VERSION "eCMPilot HS1 database-first 2026-10-28; PSA-RE 67f7581e7622410efdbb29c7eda3b86982b9b450; Apache-2.0"

NS_ :

BS_:

BU_: AAS ABS ARTIV AVAS BCP BSI BSM BVA CAV CMM CSS CVM DAE DMTR ESM E_VCU HCU1 HCU2 LVNSD MCM MDS RBG SBW VCU

BO_ 1012 E_VCU_BattTempSlots: 8 E_VCU
 SG_ RawByte8_Mux7 m7 : 63|8@0+ (1,0) [0|255] "raw"  BSI,MDS
 SG_ BatteryTempSlot49 m6 : 63|8@0+ (1,-40) [-40|215] "degC"  BSI,MDS
 SG_ BatteryTempSlot42 m5 : 63|8@0+ (1,-40) [-40|215] "degC"  BSI,MDS
 SG_ BatteryTempSlot35 m4 : 63|8@0+ (1,-40) [-40|215] "degC"  BSI,MDS
 SG_ BatteryTempSlot28 m3 : 63|8@0+ (1,-40) [-40|215] "degC"  BSI,MDS
 SG_ BatteryTempSlot21 m2 : 63|8@0+ (1,-40) [-40|215] "degC"  BSI,MDS
 SG_ BatteryTempSlot14 m1 : 63|8@0+ (1,-40) [-40|215] "degC"  BSI,MDS
 SG_ BatteryTempSlot07 m0 : 63|8@0+ (1,-40) [-40|215] "degC"  BSI,MDS
 SG_ RawByte7_Mux7 m7 : 55|8@0+ (1,0) [0|255] "raw"  BSI,MDS
 SG_ BatteryTempSlot48 m6 : 55|8@0+ (1,-40) [-40|215] "degC"  BSI,MDS
 SG_ BatteryTempSlot41 m5 : 55|8@0+ (1,-40) [-40|215] "degC"  BSI,MDS
 SG_ BatteryTempSlot34 m4 : 55|8@0+ (1,-40) [-40|215] "degC"  BSI,MDS
 SG_ BatteryTempSlot27 m3 : 55|8@0+ (1,-40) [-40|215] "degC"  BSI,MDS
 SG_ BatteryTempSlot20 m2 : 55|8@0+ (1,-40) [-40|215] "degC"  BSI,MDS
 SG_ BatteryTempSlot13 m1 : 55|8@0+ (1,-40) [-40|215] "degC"  BSI,MDS
 SG_ BatteryTempSlot06 m0 : 55|8@0+ (1,-40) [-40|215] "degC"  BSI,MDS
 SG_ BatteryTempSlot54 m7 : 47|8@0+ (1,-40) [-40|215] "degC"  BSI,MDS
 SG_ BatteryTempSlot47 m6 : 47|8@0+ (1,-40) [-40|215] "degC"  BSI,MDS
 SG_ BatteryTempSlot40 m5 : 47|8@0+ (1,-40) [-40|215] "degC"  BSI,MDS
 SG_ BatteryTempSlot33 m4 : 47|8@0+ (1,-40) [-40|215] "degC"  BSI,MDS
 SG_ BatteryTempSlot26 m3 : 47|8@0+ (1,-40) [-40|215] "degC"  BSI,MDS
 SG_ BatteryTempSlot19 m2 : 47|8@0+ (1,-40) [-40|215] "degC"  BSI,MDS
 SG_ BatteryTempSlot12 m1 : 47|8@0+ (1,-40) [-40|215] "degC"  BSI,MDS
 SG_ BatteryTempSlot05 m0 : 47|8@0+ (1,-40) [-40|215] "degC"  BSI,MDS
 SG_ BatteryTempSlot53 m7 : 39|8@0+ (1,-40) [-40|215] "degC"  BSI,MDS
 SG_ BatteryTempSlot46 m6 : 39|8@0+ (1,-40) [-40|215] "degC"  BSI,MDS
 SG_ BatteryTempSlot39 m5 : 39|8@0+ (1,-40) [-40|215] "degC"  BSI,MDS
 SG_ BatteryTempSlot32 m4 : 39|8@0+ (1,-40) [-40|215] "degC"  BSI,MDS
 SG_ BatteryTempSlot25 m3 : 39|8@0+ (1,-40) [-40|215] "degC"  BSI,MDS
 SG_ BatteryTempSlot18 m2 : 39|8@0+ (1,-40) [-40|215] "degC"  BSI,MDS
 SG_ BatteryTempSlot11 m1 : 39|8@0+ (1,-40) [-40|215] "degC"  BSI,MDS
 SG_ BatteryTempSlot04 m0 : 39|8@0+ (1,-40) [-40|215] "degC"  BSI,MDS
 SG_ BatteryTempSlot52 m7 : 31|8@0+ (1,-40) [-40|215] "degC"  BSI,MDS
 SG_ BatteryTempSlot45 m6 : 31|8@0+ (1,-40) [-40|215] "degC"  BSI,MDS
 SG_ BatteryTempSlot38 m5 : 31|8@0+ (1,-40) [-40|215] "degC"  BSI,MDS
 SG_ BatteryTempSlot31 m4 : 31|8@0+ (1,-40) [-40|215] "degC"  BSI,MDS
 SG_ BatteryTempSlot24 m3 : 31|8@0+ (1,-40) [-40|215] "degC"  BSI,MDS
 SG_ BatteryTempSlot17 m2 : 31|8@0+ (1,-40) [-40|215] "degC"  BSI,MDS
 SG_ BatteryTempSlot10 m1 : 31|8@0+ (1,-40) [-40|215] "degC"  BSI,MDS
 SG_ BatteryTempSlot03 m0 : 31|8@0+ (1,-40) [-40|215] "degC"  BSI,MDS
 SG_ BatteryTempSlot51 m7 : 23|8@0+ (1,-40) [-40|215] "degC"  BSI,MDS
 SG_ BatteryTempSlot44 m6 : 23|8@0+ (1,-40) [-40|215] "degC"  BSI,MDS
 SG_ BatteryTempSlot37 m5 : 23|8@0+ (1,-40) [-40|215] "degC"  BSI,MDS
 SG_ BatteryTempSlot30 m4 : 23|8@0+ (1,-40) [-40|215] "degC"  BSI,MDS
 SG_ BatteryTempSlot23 m3 : 23|8@0+ (1,-40) [-40|215] "degC"  BSI,MDS
 SG_ BatteryTempSlot16 m2 : 23|8@0+ (1,-40) [-40|215] "degC"  BSI,MDS
 SG_ BatteryTempSlot09 m1 : 23|8@0+ (1,-40) [-40|215] "degC"  BSI,MDS
 SG_ BatteryTempSlot02 m0 : 23|8@0+ (1,-40) [-40|215] "degC"  BSI,MDS
 SG_ BatteryTempSlot50 m7 : 15|8@0+ (1,-40) [-40|215] "degC"  BSI,MDS
 SG_ BatteryTempSlot43 m6 : 15|8@0+ (1,-40) [-40|215] "degC"  BSI,MDS
 SG_ BatteryTempSlot36 m5 : 15|8@0+ (1,-40) [-40|215] "degC"  BSI,MDS
 SG_ BatteryTempSlot29 m4 : 15|8@0+ (1,-40) [-40|215] "degC"  BSI,MDS
 SG_ BatteryTempSlot22 m3 : 15|8@0+ (1,-40) [-40|215] "degC"  BSI,MDS
 SG_ BatteryTempSlot15 m2 : 15|8@0+ (1,-40) [-40|215] "degC"  BSI,MDS
 SG_ BatteryTempSlot08 m1 : 15|8@0+ (1,-40) [-40|215] "degC"  BSI,MDS
 SG_ BatteryTempSlot01 m0 : 15|8@0+ (1,-40) [-40|215] "degC"  BSI,MDS
 SG_ RawBits3_7 : 4|5@0+ (1,0) [0|31] "raw"  BSI,MDS
 SG_ TemperatureGroup M : 7|3@0+ (1,0) [0|7] ""  BSI,MDS

BO_ 1018 Unknown_Message03: 2 Vector__XXX
 SG_ RawByte2 : 15|8@0+ (1,0) [0|255] "raw" Vector__XXX
 SG_ RawByte1 : 7|8@0+ (1,0) [0|255] "raw" Vector__XXX

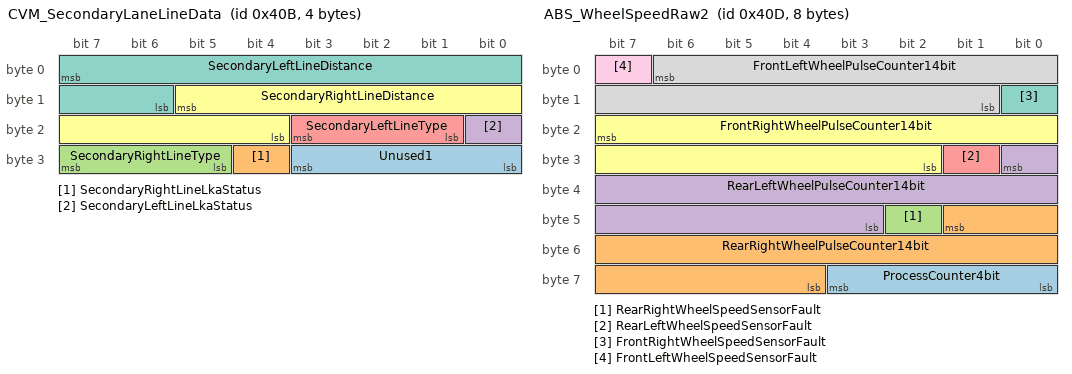
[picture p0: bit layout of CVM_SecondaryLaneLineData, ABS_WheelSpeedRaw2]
BO_ 1035 CVM_SecondaryLaneLineData: 4 CVM
 SG_ Unused1 : 27|4@0+ (1,0) [0|15] ""  BSI
 SG_ SecondaryRightLineLkaStatus : 28|1@0+ (1,0) [0|1] ""  BSI
 SG_ SecondaryRightLineType : 31|3@0+ (1,0) [0|7] ""  BSI
 SG_ SecondaryLeftLineLkaStatus : 16|1@0+ (1,0) [0|1] ""  BSI
 SG_ SecondaryLeftLineType : 19|3@0+ (1,0) [0|7] ""  BSI
 SG_ SecondaryRightLineDistance : 13|10@0- (0.016,0) [-5|5] "m"  BSI
 SG_ SecondaryLeftLineDistance : 7|10@0- (0.016,0) [-5|5] "m"  BSI

BO_ 1037 ABS_WheelSpeedRaw2: 8 ABS
 SG_ ProcessCounter4bit : 59|4@0+ (1,0) [0|15] ""  CVM,BSM,SBW,AAS,HCU1
 SG_ RearRightWheelPulseCounter14bit : 41|14@0+ (1,0) [0|16383] ""  CVM,BSM,SBW,AAS,HCU1
 SG_ RearRightWheelSpeedSensorFault : 42|1@0+ (1,0) [0|1] ""  CVM,BSM,SBW,AAS,HCU1
 SG_ RearLeftWheelPulseCounter14bit : 24|14@0+ (1,0) [0|16383] ""  CVM,BSM,SBW,AAS,HCU1
 SG_ RearLeftWheelSpeedSensorFault : 25|1@0+ (1,0) [0|1] ""  CVM,BSM,SBW,AAS,HCU1
 SG_ FrontRightWheelPulseCounter14bit : 23|14@0+ (1,0) [0|16383] ""  CVM,BSM,SBW,AAS,HCU1
 SG_ FrontRightWheelSpeedSensorFault : 8|1@0+ (1,0) [0|1] ""  CVM,BSM,SBW,AAS,HCU1
 SG_ FrontLeftWheelPulseCounter14bit : 6|14@0+ (1,0) [0|16383] ""  CVM,BSM,SBW,AAS,HCU1
 SG_ FrontLeftWheelSpeedSensorFault : 7|1@0+ (1,0) [0|1] ""  CVM,BSM,SBW,AAS,HCU1

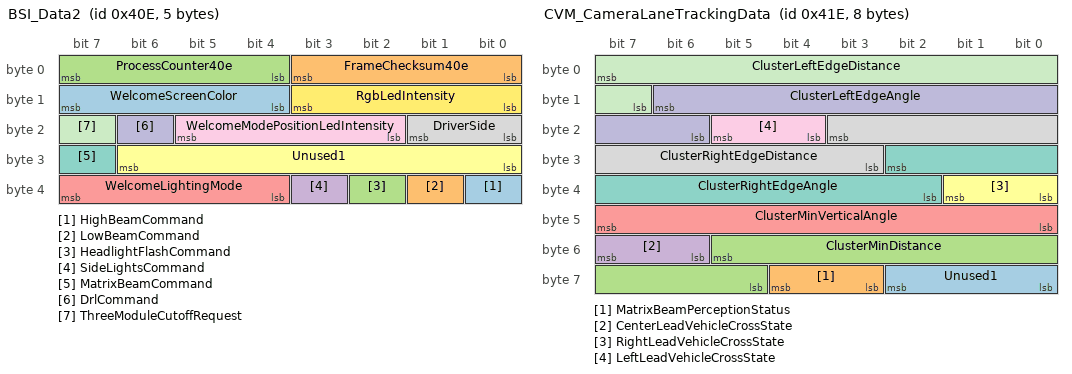
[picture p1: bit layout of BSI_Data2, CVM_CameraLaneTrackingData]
BO_ 1038 BSI_Data2: 5 BSI
 SG_ HighBeamCommand : 32|1@0+ (1,0) [0|1] ""  BCP,AVAS
 SG_ LowBeamCommand : 33|1@0+ (1,0) [0|1] ""  BCP,AVAS
 SG_ HeadlightFlashCommand : 34|1@0+ (1,0) [0|1] ""  BCP,AVAS
 SG_ SideLightsCommand : 35|1@0+ (1,0) [0|1] ""  BCP,AVAS
 SG_ WelcomeLightingMode : 39|4@0+ (1,0) [0|15] ""  BCP,AVAS
 SG_ Unused1 : 30|7@0+ (1,0) [0|127] ""  BCP,AVAS
 SG_ MatrixBeamCommand : 31|1@0+ (1,0) [0|1] ""  BCP,AVAS
 SG_ DriverSide : 17|2@0+ (1,0) [0|3] ""  BCP,AVAS
 SG_ WelcomeModePositionLedIntensity : 21|4@0+ (1,0) [0|15] ""  BCP,AVAS
 SG_ DrlCommand : 22|1@0+ (1,0) [0|1] ""  BCP,AVAS
 SG_ ThreeModuleCutoffRequest : 23|1@0+ (1,0) [0|1] ""  BCP,AVAS
 SG_ RgbLedIntensity : 11|4@0+ (1,0) [0|15] ""  BCP,AVAS
 SG_ WelcomeScreenColor : 15|4@0+ (1,0) [0|15] ""  BCP,AVAS
 SG_ FrameChecksum40e : 3|4@0+ (1,0) [0|15] ""  BCP,AVAS
 SG_ ProcessCounter40e : 7|4@0+ (1,0) [0|15] ""  BCP,AVAS

BO_ 1042 BSI_CabinData4: 8 BSI
 SG_ FapDownstreamTemperature : 63|8@0+ (1,0) [3|250] ""  VCU,CVM,ABS,BCP,CSS,CMM,BVA,AAS,HCU1,DAE,SBW,BSM,E_VCU
 SG_ MinAdditiveLevelReached : 49|2@0+ (1,0) [0|3] ""  VCU,CVM,ABS,BCP,CSS,CMM,BVA,AAS,HCU1,DAE,SBW,BSM,E_VCU
 SG_ RearWindowStatus : 50|1@0+ (1,0) [0|1] ""  VCU,CVM,ABS,BCP,CSS,CMM,BVA,AAS,HCU1,DAE,SBW,BSM,E_VCU
 SG_ DoorsStatus : 55|5@0+ (1,0) [0|31] ""  VCU,CVM,ABS,BCP,CSS,CMM,BVA,AAS,HCU1,DAE,SBW,BSM,E_VCU
 SG_ EngineOilTemperatureBsi : 47|8@0+ (1,-40) [-40|214] "degC"  VCU,CVM,ABS,BCP,CSS,CMM,BVA,AAS,HCU1,DAE,SBW,BSM,E_VCU
 SG_ SlidingRoofState : 33|2@0+ (1,0) [0|3] ""  VCU,CVM,ABS,BCP,CSS,CMM,BVA,AAS,HCU1,DAE,SBW,BSM,E_VCU
 SG_ Unused6 : 35|2@0+ (1,0) [0|3] ""  VCU,CVM,ABS,BCP,CSS,CMM,BVA,AAS,HCU1,DAE,SBW,BSM,E_VCU
 SG_ Unused5 : 39|4@0+ (1,0) [0|15] ""  VCU,CVM,ABS,BCP,CSS,CMM,BVA,AAS,HCU1,DAE,SBW,BSM,E_VCU
 SG_ FuelLow : 24|1@0+ (1,0) [0|1] ""  VCU,CVM,ABS,BCP,CSS,CMM,BVA,AAS,HCU1,DAE,SBW,BSM,E_VCU
 SG_ FuelGaugeDiagnostic : 26|2@0+ (1,0) [0|3] ""  VCU,CVM,ABS,BCP,CSS,CMM,BVA,AAS,HCU1,DAE,SBW,BSM,E_VCU
 SG_ Unused4 : 29|3@0+ (1,0) [0|7] ""  VCU,CVM,ABS,BCP,CSS,CMM,BVA,AAS,HCU1,DAE,SBW,BSM,E_VCU
 SG_ PowerSteeringModeRequest : 31|2@0+ (1,0) [0|3] ""  VCU,CVM,ABS,BCP,CSS,CMM,BVA,AAS,HCU1,DAE,SBW,BSM,E_VCU
 SG_ GearboxSnowSwitch : 16|1@0+ (1,0) [0|1] ""  VCU,CVM,ABS,BCP,CSS,CMM,BVA,AAS,HCU1,DAE,SBW,BSM,E_VCU
 SG_ GearboxSportSwitch : 17|1@0+ (1,0) [0|1] ""  VCU,CVM,ABS,BCP,CSS,CMM,BVA,AAS,HCU1,DAE,SBW,BSM,E_VCU
 SG_ GearboxPaddleInfo : 19|2@0+ (1,0) [0|3] ""  VCU,CVM,ABS,BCP,CSS,CMM,BVA,AAS,HCU1,DAE,SBW,BSM,E_VCU
 SG_ Unused3 : 22|3@0+ (1,0) [0|7] ""  VCU,CVM,ABS,BCP,CSS,CMM,BVA,AAS,HCU1,DAE,SBW,BSM,E_VCU
 SG_ AsrEspDisconnectRequest : 23|1@0+ (1,0) [0|1] ""  VCU,CVM,ABS,BCP,CSS,CMM,BVA,AAS,HCU1,DAE,SBW,BSM,E_VCU
 SG_ Unused2 : 8|1@0+ (1,0) [0|1] ""  VCU,CVM,ABS,BCP,CSS,CMM,BVA,AAS,HCU1,DAE,SBW,BSM,E_VCU
 SG_ BrakeSwitchDiagnosticCondition : 9|1@0+ (1,0) [0|1] ""  VCU,CVM,ABS,BCP,CSS,CMM,BVA,AAS,HCU1,DAE,SBW,BSM,E_VCU
 SG_ EngineOilMeasurementRequest : 10|1@0+ (1,0) [0|1] ""  VCU,CVM,ABS,BCP,CSS,CMM,BVA,AAS,HCU1,DAE,SBW,BSM,E_VCU
 SG_ CabinHeatingRequest : 11|1@0+ (1,0) [0|1] ""  VCU,CVM,ABS,BCP,CSS,CMM,BVA,AAS,HCU1,DAE,SBW,BSM,E_VCU
 SG_ AdaptiveDampingModeRequest : 13|2@0+ (1,0) [0|3] ""  VCU,CVM,ABS,BCP,CSS,CMM,BVA,AAS,HCU1,DAE,SBW,BSM,E_VCU
 SG_ Unused1 : 15|2@0+ (1,0) [0|3] ""  VCU,CVM,ABS,BCP,CSS,CMM,BVA,AAS,HCU1,DAE,SBW,BSM,E_VCU
 SG_ BrakePedalSwitchDisabled : 0|1@0+ (1,0) [0|1] ""  VCU,CVM,ABS,BCP,CSS,CMM,BVA,AAS,HCU1,DAE,SBW,BSM,E_VCU
 SG_ GearboxManualModePushRequest : 1|1@0+ (1,0) [0|1] ""  VCU,CVM,ABS,BCP,CSS,CMM,BVA,AAS,HCU1,DAE,SBW,BSM,E_VCU
 SG_ ReverseGearManualGearbox : 2|1@0+ (1,0) [0|1] ""  VCU,CVM,ABS,BCP,CSS,CMM,BVA,AAS,HCU1,DAE,SBW,BSM,E_VCU
 SG_ ParkingBrakeSwitch : 3|1@0+ (1,0) [0|1] ""  VCU,CVM,ABS,BCP,CSS,CMM,BVA,AAS,HCU1,DAE,SBW,BSM,E_VCU
 SG_ DynamicPackActivationComplement : 4|1@0+ (1,0) [0|1] ""  VCU,CVM,ABS,BCP,CSS,CMM,BVA,AAS,HCU1,DAE,SBW,BSM,E_VCU
 SG_ BrakePedalSwitch : 5|1@0+ (1,0) [0|1] ""  VCU,CVM,ABS,BCP,CSS,CMM,BVA,AAS,HCU1,DAE,SBW,BSM,E_VCU
 SG_ DynamicPackActivation : 6|1@0+ (1,0) [0|1] ""  VCU,CVM,ABS,BCP,CSS,CMM,BVA,AAS,HCU1,DAE,SBW,BSM,E_VCU
 SG_ ElectricalSystemNeedFault : 7|1@0+ (1,0) [0|1] ""  VCU,CVM,ABS,BCP,CSS,CMM,BVA,AAS,HCU1,DAE,SBW,BSM,E_VCU

BO_ 1054 CVM_CameraLaneTrackingData: 8 CVM
 SG_ Unused1 : 58|3@0+ (1,0) [0|7] ""  BCP,BSI
 SG_ MatrixBeamPerceptionStatus : 60|2@0+ (1,0) [0|3] ""  BCP,BSI
 SG_ ClusterMinDistance : 53|9@0+ (2,0) [0|600] "m"  BCP,BSI
 SG_ CenterLeadVehicleCrossState : 55|2@0+ (1,0) [0|3] ""  BCP,BSI
 SG_ ClusterMinVerticalAngle : 47|8@0- (0.1,0) [-12|12] "%rad"  BCP,BSI
 SG_ RightLeadVehicleCrossState : 33|2@0+ (1,0) [0|3] ""  BCP,BSI
 SG_ ClusterRightEdgeAngle : 26|9@0- (0.1,0) [-25|25] "°"  BCP,BSI
 SG_ ClusterRightEdgeDistance : 19|9@0+ (2,0) [0|600] "m"  BCP,BSI
 SG_ LeftLeadVehicleCrossState : 21|2@0+ (1,0) [0|3] ""  BCP,BSI
 SG_ ClusterLeftEdgeAngle : 14|9@0- (0.1,0) [-25|25] "°"  BCP,BSI
 SG_ ClusterLeftEdgeDistance : 7|9@0+ (2,0) [0|600] "m"  BCP,BSI

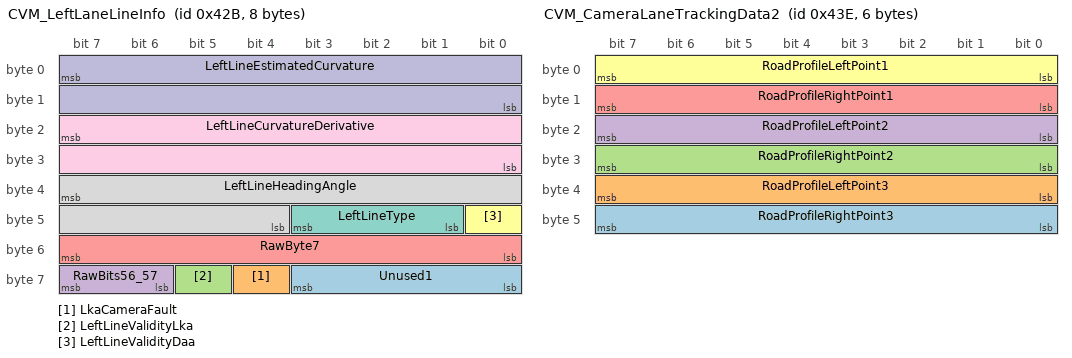
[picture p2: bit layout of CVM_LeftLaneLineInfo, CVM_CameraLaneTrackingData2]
BO_ 1067 CVM_LeftLaneLineInfo: 8 CVM
 SG_ Unused1 : 59|4@0+ (1,0) [0|15] ""  BSI
 SG_ LkaCameraFault : 60|1@0+ (1,0) [0|1] ""  BSI
 SG_ LeftLineValidityLka : 61|1@0+ (1,0) [0|1] ""  BSI
 SG_ RawBits56_57 : 63|2@0+ (1,0) [0|3] "raw"  BSI
 SG_ RawByte7 : 55|8@0+ (1,0) [0|255] "raw"  BSI
 SG_ LeftLineValidityDaa : 40|1@0+ (1,0) [0|1] ""  BSI
 SG_ LeftLineType : 43|3@0+ (1,0) [0|7] ""  BSI
 SG_ LeftLineHeadingAngle : 39|12@0- (0.015,0) [-30|30] "°"  BSI
 SG_ LeftLineCurvatureDerivative : 23|16@0- (4e-09,0) [-0.00012|0.00012] ""  BSI
 SG_ LeftLineEstimatedCurvature : 7|16@0- (2e-06,0) [-0.05|0.05] "m-1"  BSI

BO_ 1074 BSI_CabinData6: 8 BSI
 SG_ EngineStartIntentGeneral : 57|2@0+ (1,0) [0|3] ""  VCU,ESM,CVM,DMTR,DAE,SBW,ABS,BCP,CSS,CMM,BVA,BSM,HCU1,LVNSD,MDS,E_VCU
 SG_ EcoModeDriverRequest : 58|1@0+ (1,0) [0|1] ""  VCU,ESM,CVM,DMTR,DAE,SBW,ABS,BCP,CSS,CMM,BVA,BSM,HCU1,LVNSD,MDS,E_VCU
 SG_ HybridPowerLatchWakeup : 59|1@0+ (1,0) [0|1] ""  VCU,ESM,CVM,DMTR,DAE,SBW,ABS,BCP,CSS,CMM,BVA,BSM,HCU1,LVNSD,MDS,E_VCU
 SG_ ElectricalNetworkState : 63|4@0+ (1,0) [0|15] ""  VCU,ESM,CVM,DMTR,DAE,SBW,ABS,BCP,CSS,CMM,BVA,BSM,HCU1,LVNSD,MDS,E_VCU
 SG_ MainStatus : 49|2@0+ (1,0) [0|3] ""  VCU,ESM,CVM,DMTR,DAE,SBW,ABS,BCP,CSS,CMM,BVA,BSM,HCU1,LVNSD,MDS,E_VCU
 SG_ FaultLogContext : 55|6@0+ (1,0) [0|63] ""  VCU,ESM,CVM,DMTR,DAE,SBW,ABS,BCP,CSS,CMM,BVA,BSM,HCU1,LVNSD,MDS,E_VCU
 SG_ AddedFuelVolumeCounter : 42|3@0+ (1,0) [0|6] ""  VCU,ESM,CVM,DMTR,DAE,SBW,ABS,BCP,CSS,CMM,BVA,BSM,HCU1,LVNSD,MDS,E_VCU
 SG_ StartRequestStatus : 43|1@0+ (1,0) [0|1] ""  VCU,ESM,CVM,DMTR,DAE,SBW,ABS,BCP,CSS,CMM,BVA,BSM,HCU1,LVNSD,MDS,E_VCU
 SG_ Unused2 : 44|1@0+ (1,0) [0|1] ""  VCU,ESM,CVM,DMTR,DAE,SBW,ABS,BCP,CSS,CMM,BVA,BSM,HCU1,LVNSD,MDS,E_VCU
 SG_ UcapsPrechargeWakeup : 45|1@0+ (1,0) [0|1] ""  VCU,ESM,CVM,DMTR,DAE,SBW,ABS,BCP,CSS,CMM,BVA,BSM,HCU1,LVNSD,MDS,E_VCU
 SG_ EnginePostVentilationWakeup : 46|1@0+ (1,0) [0|1] ""  VCU,ESM,CVM,DMTR,DAE,SBW,ABS,BCP,CSS,CMM,BVA,BSM,HCU1,LVNSD,MDS,E_VCU
 SG_ TcuHydraulicWakeupRequest : 47|1@0+ (1,0) [0|1] ""  VCU,ESM,CVM,DMTR,DAE,SBW,ABS,BCP,CSS,CMM,BVA,BSM,HCU1,LVNSD,MDS,E_VCU
 SG_ TireHeightCorrectionWakeu_4ee41a : 32|1@0+ (1,0) [0|1] ""  VCU,ESM,CVM,DMTR,DAE,SBW,ABS,BCP,CSS,CMM,BVA,BSM,HCU1,LVNSD,MDS,E_VCU
 SG_ EbbBrakeAssistWakeup : 33|1@0+ (1,0) [0|1] ""  VCU,ESM,CVM,DMTR,DAE,SBW,ABS,BCP,CSS,CMM,BVA,BSM,HCU1,LVNSD,MDS,E_VCU
 SG_ DisplayNeedsWakeupRequest : 34|1@0+ (1,0) [0|1] ""  VCU,ESM,CVM,DMTR,DAE,SBW,ABS,BCP,CSS,CMM,BVA,BSM,HCU1,LVNSD,MDS,E_VCU
 SG_ MecatronicHeadlampWakeupRequest : 35|1@0+ (1,0) [0|1] ""  VCU,ESM,CVM,DMTR,DAE,SBW,ABS,BCP,CSS,CMM,BVA,BSM,HCU1,LVNSD,MDS,E_VCU
 SG_ EngineOilMeasurementWakeup : 36|1@0+ (1,0) [0|1] ""  VCU,ESM,CVM,DMTR,DAE,SBW,ABS,BCP,CSS,CMM,BVA,BSM,HCU1,LVNSD,MDS,E_VCU
 SG_ VehicleOverloadWakeup : 37|1@0+ (1,0) [0|1] ""  VCU,ESM,CVM,DMTR,DAE,SBW,ABS,BCP,CSS,CMM,BVA,BSM,HCU1,LVNSD,MDS,E_VCU
 SG_ EngineStartPreparationWakeup : 38|1@0+ (1,0) [0|1] ""  VCU,ESM,CVM,DMTR,DAE,SBW,ABS,BCP,CSS,CMM,BVA,BSM,HCU1,LVNSD,MDS,E_VCU
 SG_ BrakeEcuSpeedWakeupRequest : 39|1@0+ (1,0) [0|1] ""  VCU,ESM,CVM,DMTR,DAE,SBW,ABS,BCP,CSS,CMM,BVA,BSM,HCU1,LVNSD,MDS,E_VCU
 SG_ AddedFuelVolume : 31|8@0+ (0.5,0) [0|126.5] "L"  VCU,ESM,CVM,DMTR,DAE,SBW,ABS,BCP,CSS,CMM,BVA,BSM,HCU1,LVNSD,MDS,E_VCU
 SG_ FseDisplayWakeupRequest : 16|1@0+ (1,0) [0|1] ""  VCU,ESM,CVM,DMTR,DAE,SBW,ABS,BCP,CSS,CMM,BVA,BSM,HCU1,LVNSD,MDS,E_VCU
 SG_ ShortSharedPrePostWakeup : 17|1@0+ (1,0) [0|1] ""  VCU,ESM,CVM,DMTR,DAE,SBW,ABS,BCP,CSS,CMM,BVA,BSM,HCU1,LVNSD,MDS,E_VCU
 SG_ ShortPostMainWakeup1 : 18|1@0+ (1,0) [0|1] ""  VCU,ESM,CVM,DMTR,DAE,SBW,ABS,BCP,CSS,CMM,BVA,BSM,HCU1,LVNSD,MDS,E_VCU
 SG_ PriorityElectricalConsumer : 19|1@0+ (1,0) [0|1] ""  VCU,ESM,CVM,DMTR,DAE,SBW,ABS,BCP,CSS,CMM,BVA,BSM,HCU1,LVNSD,MDS,E_VCU
 SG_ HadcEnableRequest : 20|1@0+ (1,0) [0|1] ""  VCU,ESM,CVM,DMTR,DAE,SBW,ABS,BCP,CSS,CMM,BVA,BSM,HCU1,LVNSD,MDS,E_VCU
 SG_ EngineStartPreparationRequest : 21|1@0+ (1,0) [0|1] ""  VCU,ESM,CVM,DMTR,DAE,SBW,ABS,BCP,CSS,CMM,BVA,BSM,HCU1,LVNSD,MDS,E_VCU
 SG_ PulseStartRequest : 23|2@0+ (1,0) [0|3] ""  VCU,ESM,CVM,DMTR,DAE,SBW,ABS,BCP,CSS,CMM,BVA,BSM,HCU1,LVNSD,MDS,E_VCU
 SG_ BsiCalculationProcessCounter : 11|4@0+ (1,0) [0|15] ""  VCU,ESM,CVM,DMTR,DAE,SBW,ABS,BCP,CSS,CMM,BVA,BSM,HCU1,LVNSD,MDS,E_VCU
 SG_ ElectricalSystemStartIntent : 13|2@0+ (1,0) [0|3] ""  VCU,ESM,CVM,DMTR,DAE,SBW,ABS,BCP,CSS,CMM,BVA,BSM,HCU1,LVNSD,MDS,E_VCU
 SG_ Unused1 : 15|2@0+ (1,0) [0|3] ""  VCU,ESM,CVM,DMTR,DAE,SBW,ABS,BCP,CSS,CMM,BVA,BSM,HCU1,LVNSD,MDS,E_VCU
 SG_ EngineStopRequest : 1|2@0+ (1,0) [0|3] ""  VCU,ESM,CVM,DMTR,DAE,SBW,ABS,BCP,CSS,CMM,BVA,BSM,HCU1,LVNSD,MDS,E_VCU
 SG_ StarterStopRequest : 2|1@0+ (1,0) [0|1] ""  VCU,ESM,CVM,DMTR,DAE,SBW,ABS,BCP,CSS,CMM,BVA,BSM,HCU1,LVNSD,MDS,E_VCU
 SG_ HeightCorrectionWakeupRequest : 3|1@0+ (1,0) [0|1] ""  VCU,ESM,CVM,DMTR,DAE,SBW,ABS,BCP,CSS,CMM,BVA,BSM,HCU1,LVNSD,MDS,E_VCU
 SG_ AntiTheftWakeupRequest : 4|1@0+ (1,0) [0|1] ""  VCU,ESM,CVM,DMTR,DAE,SBW,ABS,BCP,CSS,CMM,BVA,BSM,HCU1,LVNSD,MDS,E_VCU
 SG_ GearboxStateWakeupRequest : 5|1@0+ (1,0) [0|1] ""  VCU,ESM,CVM,DMTR,DAE,SBW,ABS,BCP,CSS,CMM,BVA,BSM,HCU1,LVNSD,MDS,E_VCU
 SG_ MainWakeupStatus : 7|2@0+ (1,0) [0|3] ""  VCU,ESM,CVM,DMTR,DAE,SBW,ABS,BCP,CSS,CMM,BVA,BSM,HCU1,LVNSD,MDS,E_VCU

BO_ 1086 CVM_CameraLaneTrackingData2: 6 CVM
 SG_ RoadProfileRightPoint3 : 47|8@0+ (0.002,-0.25) [-0.25|0.25] "m"  CSS
 SG_ RoadProfileLeftPoint3 : 39|8@0+ (0.002,-0.25) [-0.25|0.25] "m"  CSS
 SG_ RoadProfileRightPoint2 : 31|8@0+ (0.002,-0.25) [-0.25|0.25] "m"  CSS
 SG_ RoadProfileLeftPoint2 : 23|8@0+ (0.002,-0.25) [-0.25|0.25] "m"  CSS
 SG_ RoadProfileRightPoint1 : 15|8@0+ (0.002,-0.25) [-0.25|0.25] "m"  CSS
 SG_ RoadProfileLeftPoint1 : 7|8@0+ (0.002,-0.25) [-0.25|0.25] "m"  CSS

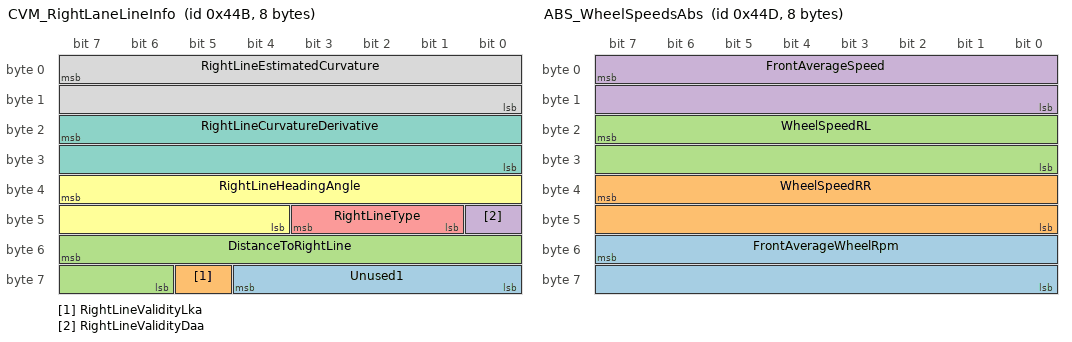
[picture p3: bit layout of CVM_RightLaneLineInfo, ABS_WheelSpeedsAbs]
BO_ 1099 CVM_RightLaneLineInfo: 8 CVM
 SG_ Unused1 : 60|5@0+ (1,0) [0|31] ""  BSI
 SG_ RightLineValidityLka : 61|1@0+ (1,0) [0|1] ""  BSI
 SG_ DistanceToRightLine : 55|10@0- (0.016,0) [-5|5] "m"  BSI
 SG_ RightLineValidityDaa : 40|1@0+ (1,0) [0|1] ""  BSI
 SG_ RightLineType : 43|3@0+ (1,0) [0|7] ""  BSI
 SG_ RightLineHeadingAngle : 39|12@0- (0.015,0) [-30|30] "°"  BSI
 SG_ RightLineCurvatureDerivative : 23|16@0- (4e-09,0) [-0.00012|0.00012] ""  BSI
 SG_ RightLineEstimatedCurvature : 7|16@0- (2e-06,0) [-0.05|0.05] "m-1"  BSI

BO_ 1101 ABS_WheelSpeedsAbs: 8 ABS
 SG_ FrontAverageWheelRpm : 55|16@0+ (0.04,0) [0|2621] "rpm"  VCU,CVM,BSM,SBW,BVA,CMM,HCU1
 SG_ WheelSpeedRR : 39|16@0+ (0.01,0) [0|655.34] "km/h"  VCU,CVM,BSM,SBW,BVA,CMM,HCU1
 SG_ WheelSpeedRL : 23|16@0+ (0.01,0) [0|655.34] "km/h"  VCU,CVM,BSM,SBW,BVA,CMM,HCU1
 SG_ FrontAverageSpeed : 7|16@0+ (0.01,0) [0|655.34] "km/h"  VCU,CVM,BSM,SBW,BVA,CMM,HCU1

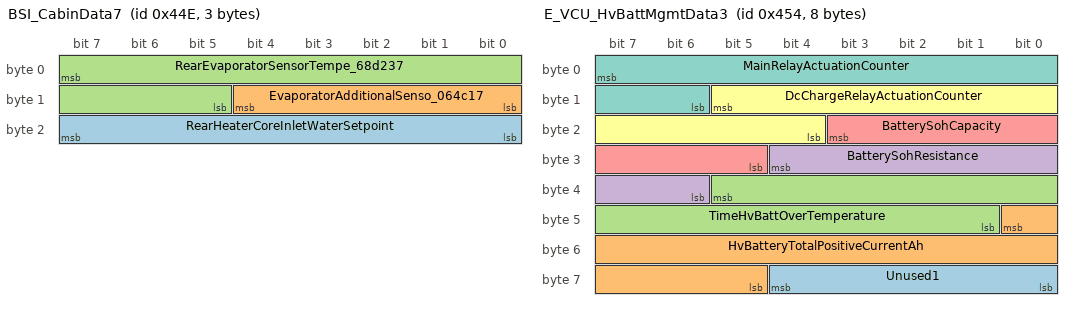
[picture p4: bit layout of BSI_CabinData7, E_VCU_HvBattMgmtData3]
BO_ 1102 BSI_CabinData7: 3 BSI
 SG_ RearHeaterCoreInletWaterSetpoint : 23|8@0+ (0.5,0) [0|70] "degC"  E_VCU
 SG_ EvaporatorAdditionalSenso_064c17 : 12|5@0+ (0.5,0) [0|15] "degC"  E_VCU
 SG_ RearEvaporatorSensorTempe_68d237 : 7|11@0+ (0.1,-40) [-40|85] "degC"  E_VCU

BO_ 1108 E_VCU_HvBattMgmtData3: 8 E_VCU
 SG_ Unused1 : 60|5@0+ (1,0) [0|31] ""  MDS,BSI
 SG_ HvBatteryTotalPositiveCurrentAh : 40|12@0+ (125,0) [0|500000] "Ah"  MDS,BSI
 SG_ TimeHvBattOverTemperature : 37|13@0+ (0.1,0) [0|600] "h"  MDS,BSI
 SG_ BatterySohResistance : 28|7@0+ (1,0) [0|100] "%"  MDS,BSI
 SG_ BatterySohCapacity : 19|7@0+ (1,0) [0|100] "%"  MDS,BSI
 SG_ DcChargeRelayActuationCounter : 13|10@0+ (200,0) [0|200000] ""  MDS,BSI
 SG_ MainRelayActuationCounter : 7|10@0+ (200,0) [0|200000] ""  MDS,BSI

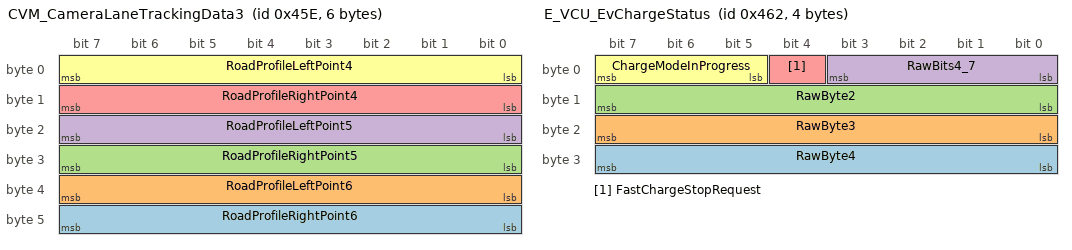
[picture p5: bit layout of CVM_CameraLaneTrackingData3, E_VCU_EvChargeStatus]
BO_ 1118 CVM_CameraLaneTrackingData3: 6 CVM
 SG_ RoadProfileRightPoint6 : 47|8@0+ (0.002,-0.25) [-0.25|0.25] "m"  CSS
 SG_ RoadProfileLeftPoint6 : 39|8@0+ (0.002,-0.25) [-0.25|0.25] "m"  CSS
 SG_ RoadProfileRightPoint5 : 31|8@0+ (0.002,-0.25) [-0.25|0.25] "m"  CSS
 SG_ RoadProfileLeftPoint5 : 23|8@0+ (0.002,-0.25) [-0.25|0.25] "m"  CSS
 SG_ RoadProfileRightPoint4 : 15|8@0+ (0.002,-0.25) [-0.25|0.25] "m"  CSS
 SG_ RoadProfileLeftPoint4 : 7|8@0+ (0.002,-0.25) [-0.25|0.25] "m"  CSS

BO_ 1122 E_VCU_EvChargeStatus: 4 E_VCU
 SG_ RawByte4 : 31|8@0+ (1,0) [0|255] "raw"  BSI
 SG_ RawByte3 : 23|8@0+ (1,0) [0|255] "raw"  BSI
 SG_ RawByte2 : 15|8@0+ (1,0) [0|255] "raw"  BSI
 SG_ RawBits4_7 : 3|4@0+ (1,0) [0|15] "raw"  BSI
 SG_ FastChargeStopRequest : 4|1@0+ (1,0) [0|1] ""  BSI
 SG_ ChargeModeInProgress : 7|3@0+ (1,0) [0|7] ""  BSI

BO_ 1128 E_VCU_EngineDynData3: 8 E_VCU
 SG_ ElectricalConsumerClass1Cut : 56|1@0+ (1,0) [0|1] ""  BCP,SBW,DMTR,BVA,BSI,DAE,ABS
 SG_ ElectricalConsumerClass2Cut : 57|1@0+ (1,0) [0|1] ""  BCP,SBW,DMTR,BVA,BSI,DAE,ABS
 SG_ ElectricalConsumerClass3Cut : 58|1@0+ (1,0) [0|1] ""  BCP,SBW,DMTR,BVA,BSI,DAE,ABS
 SG_ ElectricalConsumerClass4Cut : 59|1@0+ (1,0) [0|1] ""  BCP,SBW,DMTR,BVA,BSI,DAE,ABS
 SG_ ElectricalConsumerClass5Cut : 60|1@0+ (1,0) [0|1] ""  BCP,SBW,DMTR,BVA,BSI,DAE,ABS
 SG_ ElectricalConsumerClass6Cut : 61|1@0+ (1,0) [0|1] ""  BCP,SBW,DMTR,BVA,BSI,DAE,ABS
 SG_ ElectricalConsumerClass7Cut : 62|1@0+ (1,0) [0|1] ""  BCP,SBW,DMTR,BVA,BSI,DAE,ABS
 SG_ ElectricalConsumerClass8Cut : 63|1@0+ (1,0) [0|1] ""  BCP,SBW,DMTR,BVA,BSI,DAE,ABS
 SG_ ElectricalConsumerClass9Cut : 48|1@0+ (1,0) [0|1] ""  BCP,SBW,DMTR,BVA,BSI,DAE,ABS
 SG_ EngineStopImminent : 49|1@0+ (1,0) [0|1] ""  BCP,SBW,DMTR,BVA,BSI,DAE,ABS
 SG_ LoadSheddingRequest : 50|1@0+ (1,0) [0|1] ""  BCP,SBW,DMTR,BVA,BSI,DAE,ABS
 SG_ VacuumSupplyFaultLampRequest : 51|1@0+ (1,0) [0|1] ""  BCP,SBW,DMTR,BVA,BSI,DAE,ABS
 SG_ GeneratorLoadRequest : 53|2@0+ (1,0) [0|3] ""  BCP,SBW,DMTR,BVA,BSI,DAE,ABS
 SG_ AutomaticGearboxLockupRequest : 54|1@0+ (1,0) [0|1] ""  BCP,SBW,DMTR,BVA,BSI,DAE,ABS
 SG_ SafetyLoadSheddingLevel1 : 55|1@0+ (1,0) [0|1] ""  BCP,SBW,DMTR,BVA,BSI,DAE,ABS
 SG_ ElectricalSupplyStatus12v : 43|4@0+ (1,0) [0|15] ""  BCP,SBW,DMTR,BVA,BSI,DAE,ABS
 SG_ StubbedSignal1 : 44|1@0+ (1,0) [0|1] ""  BCP,SBW,DMTR,BVA,BSI,DAE,ABS
 SG_ RawBits41_42 : 46|2@0+ (1,0) [0|3] "raw"  BCP,SBW,DMTR,BVA,BSI,DAE,ABS
 SG_ CreepAuthorization : 47|1@0+ (1,0) [0|1] ""  BCP,SBW,DMTR,BVA,BSI,DAE,ABS
 SG_ RelayR3ControlRequest : 32|1@0+ (1,0) [0|1] ""  BCP,SBW,DMTR,BVA,BSI,DAE,ABS
 SG_ RelayR2ControlRequest : 33|1@0+ (1,0) [0|1] ""  BCP,SBW,DMTR,BVA,BSI,DAE,ABS
 SG_ RelayR1ControlRequest : 34|1@0+ (1,0) [0|1] ""  BCP,SBW,DMTR,BVA,BSI,DAE,ABS
 SG_ GeneratorProductionFault : 35|1@0+ (1,0) [0|1] ""  BCP,SBW,DMTR,BVA,BSI,DAE,ABS
 SG_ DcdcLvVoltageSetpoint : 25|6@0+ (0.1,10.6) [10.6|16] "V"  BCP,SBW,DMTR,BVA,BSI,DAE,ABS
 SG_ GeneratorProductionLevel : 28|3@0+ (1,0) [0|7] ""  BCP,SBW,DMTR,BVA,BSI,DAE,ABS
 SG_ GeneratorProductionStatus : 31|3@0+ (1,0) [0|7] ""  BCP,SBW,DMTR,BVA,BSI,DAE,ABS
 SG_ StarterInhibitDriverUnavailable : 16|1@0+ (1,0) [0|1] ""  BCP,SBW,DMTR,BVA,BSI,DAE,ABS
 SG_ BoostPressure : 21|5@0+ (100,0) [0|3000] "mbar"  BCP,SBW,DMTR,BVA,BSI,DAE,ABS
 SG_ ElectricalConsumerActivat_f46ef1 : 23|2@0+ (1,0) [0|3] ""  BCP,SBW,DMTR,BVA,BSI,DAE,ABS
 SG_ TractionChainStatus : 9|2@0+ (1,0) [0|3] ""  BCP,SBW,DMTR,BVA,BSI,DAE,ABS
 SG_ StartAuthorizationStatus : 11|2@0+ (1,0) [0|3] ""  BCP,SBW,DMTR,BVA,BSI,DAE,ABS
 SG_ CmmFault : 13|2@0+ (1,0) [0|3] ""  BCP,SBW,DMTR,BVA,BSI,DAE,ABS
 SG_ TurboTransitionInProgress : 15|2@0+ (1,0) [0|3] ""  BCP,SBW,DMTR,BVA,BSI,DAE,ABS
 SG_ Unused1 : 2|3@0+ (1,0) [0|7] ""  BCP,SBW,DMTR,BVA,BSI,DAE,ABS
 SG_ DampFunctionStatus : 4|2@0+ (1,0) [0|3] ""  BCP,SBW,DMTR,BVA,BSI,DAE,ABS
 SG_ StarterProtectionStatus : 5|1@0+ (1,0) [0|1] ""  BCP,SBW,DMTR,BVA,BSI,DAE,ABS
 SG_ BrakePedalSecondarySwitch_db3725 : 6|1@0+ (1,0) [0|1] ""  BCP,SBW,DMTR,BVA,BSI,DAE,ABS
 SG_ StarterCommandFeedback : 7|1@0+ (1,0) [0|1] ""  BCP,SBW,DMTR,BVA,BSI,DAE,ABS

BO_ 1134 BSI_CabinData8: 2 BSI
 SG_ RawBits9_15 : 14|7@0+ (1,0) [0|127] "raw"  CMM
 SG_ FuelGaugeResistance : 7|9@0+ (1,0) [0|500] "Ohm"  CMM

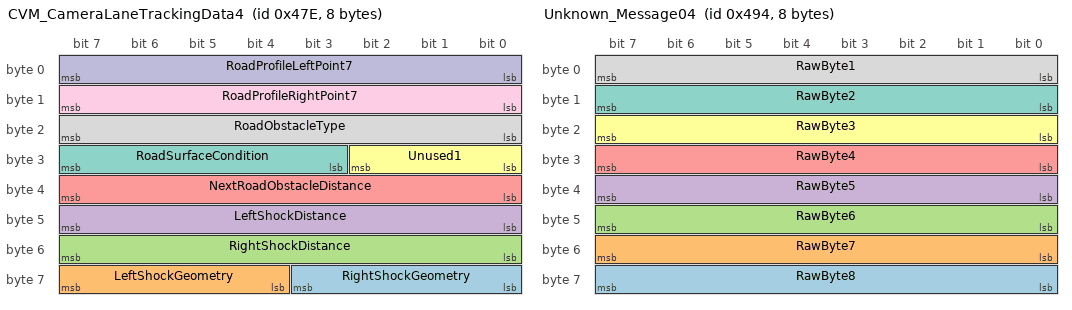
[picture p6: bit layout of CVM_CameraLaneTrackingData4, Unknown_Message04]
BO_ 1150 CVM_CameraLaneTrackingData4: 8 CVM
 SG_ RightShockGeometry : 59|4@0+ (1,0) [0|12] ""  CSS
 SG_ LeftShockGeometry : 63|4@0+ (1,0) [0|12] ""  CSS
 SG_ RightShockDistance : 55|8@0+ (0.03,5) [5|12.02] "m"  CSS
 SG_ LeftShockDistance : 47|8@0+ (0.03,5) [5|12.02] "m"  CSS
 SG_ NextRoadObstacleDistance : 39|8@0+ (0.03,5) [5|12.02] "m"  CSS
 SG_ Unused1 : 26|3@0+ (1,0) [0|7] ""  CSS
 SG_ RoadSurfaceCondition : 31|5@0+ (0.05,0) [0|1] ""  CSS
 SG_ RoadObstacleType : 23|8@0+ (1,0) [0|255] ""  CSS
 SG_ RoadProfileRightPoint7 : 15|8@0+ (0.002,-0.25) [-0.25|0.25] "m"  CSS
 SG_ RoadProfileLeftPoint7 : 7|8@0+ (0.002,-0.25) [-0.25|0.25] "m"  CSS

BO_ 1161 E_VCU_GearboxDataV2: 8 E_VCU
 SG_ DriverTargetGearDisplay : 59|4@0+ (1,0) [0|15] ""  CVM,ABS,SBW,BCP,CMM,BSI,BSM
 SG_ GearboxDynamicModeAvailability : 61|2@0+ (1,0) [0|3] ""  CVM,ABS,SBW,BCP,CMM,BSI,BSM
 SG_ GearboxLongInitInProgress : 62|1@0+ (1,0) [0|1] ""  CVM,ABS,SBW,BCP,CMM,BSI,BSM
 SG_ GearboxRedWarningLampRequest : 63|1@0+ (1,0) [0|1] ""  CVM,ABS,SBW,BCP,CMM,BSI,BSM
 SG_ PowertrainSportinessIndexState : 55|8@0+ (1,0) [0|255] ""  CVM,ABS,SBW,BCP,CMM,BSI,BSM
 SG_ TorqueConversionRatioExtended : 35|12@0+ (0.01,1) [1|40] ""  CVM,ABS,SBW,BCP,CMM,BSI,BSM
 SG_ GearboxDynamicModeStatus : 37|2@0+ (1,0) [0|3] ""  CVM,ABS,SBW,BCP,CMM,BSI,BSM
 SG_ BrakePressRequest : 38|1@0+ (1,0) [0|1] ""  CVM,ABS,SBW,BCP,CMM,BSI,BSM
 SG_ SportMode : 39|1@0+ (1,0) [0|1] ""  CVM,ABS,SBW,BCP,CMM,BSI,BSM
 SG_ GearboxOilTemperature : 31|8@0+ (1,-40) [-40|214] "degC"  CVM,ABS,SBW,BCP,CMM,BSI,BSM
 SG_ GearboxMilContinuousRequest : 16|1@0+ (1,0) [0|1] ""  CVM,ABS,SBW,BCP,CMM,BSI,BSM
 SG_ GearboxMilBlinkingRequest : 17|1@0+ (1,0) [0|1] ""  CVM,ABS,SBW,BCP,CMM,BSI,BSM
 SG_ GearboxMilOnCounterResetCommand : 18|1@0+ (1,0) [0|1] ""  CVM,ABS,SBW,BCP,CMM,BSI,BSM
 SG_ GearboxMisfireAlgorithmDi_6d0f78 : 19|1@0+ (1,0) [0|1] ""  CVM,ABS,SBW,BCP,CMM,BSI,BSM
 SG_ CrankingProhibit : 20|1@0+ (1,0) [0|1] ""  CVM,ABS,SBW,BCP,CMM,BSI,BSM
 SG_ DoublePedalPressDetection : 21|1@0+ (1,0) [0|1] ""  CVM,ABS,SBW,BCP,CMM,BSI,BSM
 SG_ ShiftLockActive : 22|1@0+ (1,0) [0|1] ""  CVM,ABS,SBW,BCP,CMM,BSI,BSM
 SG_ RadiatorFanIncreaseReques_ff8db7 : 23|1@0+ (1,0) [0|1] ""  CVM,ABS,SBW,BCP,CMM,BSI,BSM
 SG_ GearboxReadinessCodeSummary : 8|1@0+ (1,0) [0|1] ""  CVM,ABS,SBW,BCP,CMM,BSI,BSM
 SG_ GearChangeRefused : 9|1@0+ (1,0) [0|1] ""  CVM,ABS,SBW,BCP,CMM,BSI,BSM
 SG_ GearboxDrivingLawSelection : 11|2@0+ (1,0) [0|3] ""  CVM,ABS,SBW,BCP,CMM,BSI,BSM
 SG_ GearboxFaultsStates : 15|4@0+ (1,0) [0|15] ""  CVM,ABS,SBW,BCP,CMM,BSI,BSM
 SG_ GearPositionDisplay : 3|4@0+ (1,0) [0|15] ""  CVM,ABS,SBW,BCP,CMM,BSI,BSM
 SG_ GearboxMechanicallyEngagedGear : 7|4@0+ (1,0) [0|15] ""  CVM,ABS,SBW,BCP,CMM,BSI,BSM

BO_ 1172 Unknown_Message04: 8 Vector__XXX
 SG_ RawByte8 : 63|8@0+ (1,0) [0|255] "raw" Vector__XXX
 SG_ RawByte7 : 55|8@0+ (1,0) [0|255] "raw" Vector__XXX
 SG_ RawByte6 : 47|8@0+ (1,0) [0|255] "raw" Vector__XXX
 SG_ RawByte5 : 39|8@0+ (1,0) [0|255] "raw" Vector__XXX
 SG_ RawByte4 : 31|8@0+ (1,0) [0|255] "raw" Vector__XXX
 SG_ RawByte3 : 23|8@0+ (1,0) [0|255] "raw" Vector__XXX
 SG_ RawByte2 : 15|8@0+ (1,0) [0|255] "raw" Vector__XXX
 SG_ RawByte1 : 7|8@0+ (1,0) [0|255] "raw" Vector__XXX

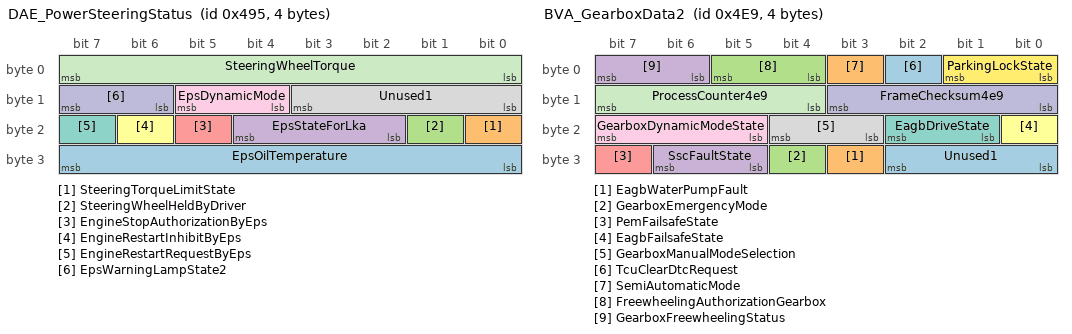
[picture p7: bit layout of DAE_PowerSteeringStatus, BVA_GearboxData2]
BO_ 1173 DAE_PowerSteeringStatus: 4 DAE
 SG_ EpsOilTemperature : 31|8@0+ (1,-40) [-40|214] "degC"  BSI,CMM,E_VCU
 SG_ SteeringTorqueLimitState : 16|1@0+ (1,0) [0|1] ""  BSI,CMM,E_VCU
 SG_ SteeringWheelHeldByDriver : 17|1@0+ (1,0) [0|1] ""  BSI,CMM,E_VCU
 SG_ EpsStateForLka : 20|3@0+ (1,0) [0|7] ""  BSI,CMM,E_VCU
 SG_ EngineStopAuthorizationByEps : 21|1@0+ (1,0) [0|1] ""  BSI,CMM,E_VCU
 SG_ EngineRestartInhibitByEps : 22|1@0+ (1,0) [0|1] ""  BSI,CMM,E_VCU
 SG_ EngineRestartRequestByEps : 23|1@0+ (1,0) [0|1] ""  BSI,CMM,E_VCU
 SG_ Unused1 : 11|4@0+ (1,0) [0|15] ""  BSI,CMM,E_VCU
 SG_ EpsDynamicMode : 13|2@0+ (1,0) [0|3] ""  BSI,CMM,E_VCU
 SG_ EpsWarningLampState2 : 15|2@0+ (1,0) [0|3] ""  BSI,CMM,E_VCU
 SG_ SteeringWheelTorque : 7|8@0- (0.25,0) [-32|31.5] "Nm"  BSI,CMM,E_VCU

BO_ 1186 Unknown_Message05: 2 Vector__XXX
 SG_ RawByte2 : 15|8@0+ (1,0) [0|255] "raw" Vector__XXX
 SG_ RawByte1 : 7|8@0+ (1,0) [0|255] "raw" Vector__XXX

BO_ 1230 BSI_CabinData11: 8 BSI
 SG_ RawByte8 : 63|8@0+ (1,0) [0|255] "raw" Vector__XXX
 SG_ RawBits54_55 : 49|2@0+ (1,0) [0|3] "raw" Vector__XXX
 SG_ FrontLeftWheelStatus : 54|5@0+ (1,0) [0|31] "" Vector__XXX
 SG_ FrontRightWheelStatus : 43|5@0+ (1,0) [0|31] "" Vector__XXX
 SG_ RearLeftWheelStatus : 32|5@0+ (1,0) [0|31] "" Vector__XXX
 SG_ RearRightWheelStatus : 37|5@0+ (1,0) [0|31] "" Vector__XXX
 SG_ AbsFault : 38|1@0+ (1,0) [0|1] "" Vector__XXX
 SG_ BrakeLevelAlert : 39|1@0+ (1,0) [0|1] "" Vector__XXX
 SG_ RejectPowerOnInEco : 24|1@0+ (1,0) [0|1] "" Vector__XXX
 SG_ BrakesFault : 25|1@0+ (1,0) [0|1] "" Vector__XXX
 SG_ FonctActLvvRvv : 27|2@0+ (1,0) [0|3] "" Vector__XXX
 SG_ GearPositionToDisplay : 31|4@0+ (1,0) [0|15] "" Vector__XXX
 SG_ FrontBlowerPlusSwitchState : 19|4@0+ (1,0) [0|15] "" Vector__XXX
 SG_ RearBlowerPlusSwitchState : 23|4@0+ (1,0) [0|15] "" Vector__XXX
 SG_ UnderinflationAlert : 8|1@0+ (1,0) [0|1] "" Vector__XXX
 SG_ CenterTemperatureSetpoint : 11|3@0+ (1,0) [0|7] "" Vector__XXX
 SG_ MaintenanceType2 : 12|1@0+ (1,0) [0|1] "" Vector__XXX
 SG_ MaintenanceType : 13|1@0+ (1,0) [0|1] "" Vector__XXX
 SG_ TimeSymbol : 14|1@0+ (1,0) [0|1] "" Vector__XXX
 SG_ ParkingBrakes : 15|1@0+ (1,0) [0|1] "" Vector__XXX
 SG_ ParticleFilterFault : 0|1@0+ (1,0) [0|1] "" Vector__XXX
 SG_ CheckAutonomy : 1|1@0+ (1,0) [0|1] "" Vector__XXX
 SG_ DistanceBlinking : 2|1@0+ (1,0) [0|1] "" Vector__XXX
 SG_ MaintenanceWrenchIconDisplay : 3|1@0+ (1,0) [0|1] "" Vector__XXX
 SG_ OilPressureAlert : 4|1@0+ (1,0) [0|1] "" Vector__XXX
 SG_ OilLevelAlert : 5|1@0+ (1,0) [0|1] "" Vector__XXX
 SG_ LowFuelBlink : 6|1@0+ (1,0) [0|1] "" Vector__XXX
 SG_ DieselWaterFault : 7|1@0+ (1,0) [0|1] "" Vector__XXX

BO_ 1257 BVA_GearboxData2: 4 BVA
 SG_ Unused1 : 26|3@0+ (1,0) [0|7] ""  ABS,CMM,BSI,AAS,LVNSD,VCU
 SG_ EagbWaterPumpFault : 27|1@0+ (1,0) [0|1] ""  ABS,CMM,BSI,AAS,LVNSD,VCU
 SG_ GearboxEmergencyMode : 28|1@0+ (1,0) [0|1] ""  ABS,CMM,BSI,AAS,LVNSD,VCU
 SG_ SscFaultState : 30|2@0+ (1,0) [0|3] ""  ABS,CMM,BSI,AAS,LVNSD,VCU
 SG_ PemFailsafeState : 31|1@0+ (1,0) [0|1] ""  ABS,CMM,BSI,AAS,LVNSD,VCU
 SG_ EagbFailsafeState : 16|1@0+ (1,0) [0|1] ""  ABS,CMM,BSI,AAS,LVNSD,VCU
 SG_ EagbDriveState : 18|2@0+ (1,0) [0|3] ""  ABS,CMM,BSI,AAS,LVNSD,VCU
 SG_ GearboxManualModeSelection : 20|2@0+ (1,0) [0|3] ""  ABS,CMM,BSI,AAS,LVNSD,VCU
 SG_ GearboxDynamicModeState : 23|3@0+ (1,0) [0|7] ""  ABS,CMM,BSI,AAS,LVNSD,VCU
 SG_ FrameChecksum4e9 : 11|4@0+ (1,0) [0|15] ""  ABS,CMM,BSI,AAS,LVNSD,VCU
 SG_ ProcessCounter4e9 : 15|4@0+ (1,0) [0|15] ""  ABS,CMM,BSI,AAS,LVNSD,VCU
 SG_ ParkingLockState : 1|2@0+ (1,0) [0|3] ""  ABS,CMM,BSI,AAS,LVNSD,VCU
 SG_ TcuClearDtcRequest : 2|1@0+ (1,0) [0|1] ""  ABS,CMM,BSI,AAS,LVNSD,VCU
 SG_ SemiAutomaticMode : 3|1@0+ (1,0) [0|1] ""  ABS,CMM,BSI,AAS,LVNSD,VCU
 SG_ FreewheelingAuthorizationGearbox : 5|2@0+ (1,0) [0|3] ""  ABS,CMM,BSI,AAS,LVNSD,VCU
 SG_ GearboxFreewheelingStatus : 7|2@0+ (1,0) [0|3] ""  ABS,CMM,BSI,AAS,LVNSD,VCU

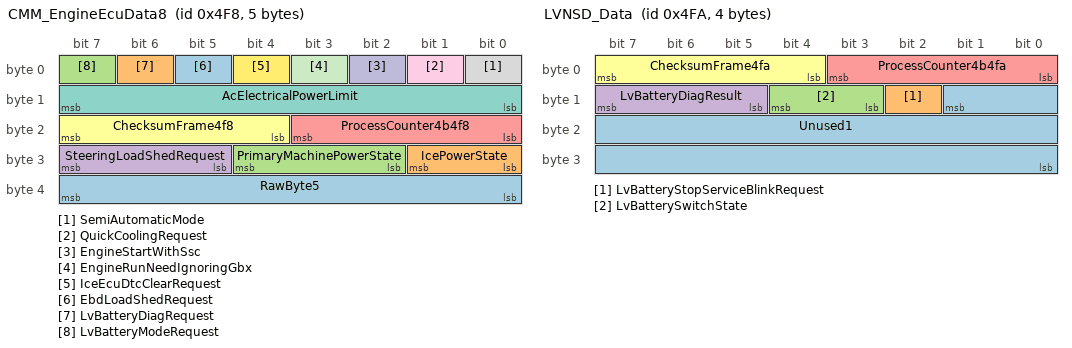
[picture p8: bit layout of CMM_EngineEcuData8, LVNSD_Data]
BO_ 1272 CMM_EngineEcuData8: 5 CMM
 SG_ RawByte5 : 39|8@0+ (1,0) [0|255] "raw"  LVNSD,BVA,BSI,DAE,ABS,VCU
 SG_ IcePowerState : 25|2@0+ (1,0) [0|3] ""  LVNSD,BVA,BSI,DAE,ABS,VCU
 SG_ PrimaryMachinePowerState : 28|3@0+ (1,0) [0|7] ""  LVNSD,BVA,BSI,DAE,ABS,VCU
 SG_ SteeringLoadShedRequest : 31|3@0+ (1,0) [0|7] ""  LVNSD,BVA,BSI,DAE,ABS,VCU
 SG_ ProcessCounter4b4f8 : 19|4@0+ (1,0) [0|15] ""  LVNSD,BVA,BSI,DAE,ABS,VCU
 SG_ ChecksumFrame4f8 : 23|4@0+ (1,0) [0|15] ""  LVNSD,BVA,BSI,DAE,ABS,VCU
 SG_ AcElectricalPowerLimit : 15|8@0+ (50,0) [0|12000] "W"  LVNSD,BVA,BSI,DAE,ABS,VCU
 SG_ SemiAutomaticMode : 0|1@0+ (1,0) [0|1] ""  LVNSD,BVA,BSI,DAE,ABS,VCU
 SG_ QuickCoolingRequest : 1|1@0+ (1,0) [0|1] ""  LVNSD,BVA,BSI,DAE,ABS,VCU
 SG_ EngineStartWithSsc : 2|1@0+ (1,0) [0|1] ""  LVNSD,BVA,BSI,DAE,ABS,VCU
 SG_ EngineRunNeedIgnoringGbx : 3|1@0+ (1,0) [0|1] ""  LVNSD,BVA,BSI,DAE,ABS,VCU
 SG_ IceEcuDtcClearRequest : 4|1@0+ (1,0) [0|1] ""  LVNSD,BVA,BSI,DAE,ABS,VCU
 SG_ EbdLoadShedRequest : 5|1@0+ (1,0) [0|1] ""  LVNSD,BVA,BSI,DAE,ABS,VCU
 SG_ LvBatteryDiagRequest : 6|1@0+ (1,0) [0|1] ""  LVNSD,BVA,BSI,DAE,ABS,VCU
 SG_ LvBatteryModeRequest : 7|1@0+ (1,0) [0|1] ""  LVNSD,BVA,BSI,DAE,ABS,VCU

BO_ 1274 LVNSD_Data: 4 LVNSD
 SG_ Unused1 : 9|18@0+ (1,0) [0|262143] ""  CMM
 SG_ LvBatteryStopServiceBlinkRequest : 10|1@0+ (1,0) [0|1] ""  CMM
 SG_ LvBatterySwitchState : 12|2@0+ (1,0) [0|3] ""  CMM
 SG_ LvBatteryDiagResult : 15|3@0+ (1,0) [0|7] ""  CMM
 SG_ ProcessCounter4b4fa : 3|4@0+ (1,0) [0|15] ""  CMM
 SG_ ChecksumFrame4fa : 7|4@0+ (1,0) [0|15] ""  CMM

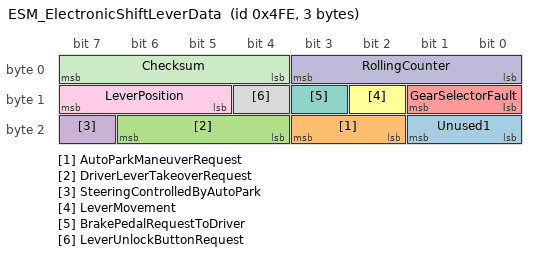
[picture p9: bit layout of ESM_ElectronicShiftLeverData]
BO_ 1278 ESM_ElectronicShiftLeverData: 3 ESM
 SG_ Unused1 : 17|2@0+ (1,0) [0|3] ""  CMM,BVA,SBW,ABS,AAS,E_VCU
 SG_ AutoParkManeuverRequest : 19|2@0+ (1,0) [0|3] ""  CMM,BVA,SBW,ABS,AAS,E_VCU
 SG_ DriverLeverTakeoverRequest : 22|3@0+ (1,0) [0|7] ""  CMM,BVA,SBW,ABS,AAS,E_VCU
 SG_ SteeringControlledByAutoPark : 23|1@0+ (1,0) [0|1] ""  CMM,BVA,SBW,ABS,AAS,E_VCU
 SG_ GearSelectorFault : 9|2@0+ (1,0) [0|3] ""  CMM,BVA,SBW,ABS,AAS,E_VCU
 SG_ LeverMovement : 10|1@0+ (1,0) [0|1] ""  CMM,BVA,SBW,ABS,AAS,E_VCU
 SG_ BrakePedalRequestToDriver : 11|1@0+ (1,0) [0|1] ""  CMM,BVA,SBW,ABS,AAS,E_VCU
 SG_ LeverUnlockButtonRequest : 12|1@0+ (1,0) [0|1] ""  CMM,BVA,SBW,ABS,AAS,E_VCU
 SG_ LeverPosition : 15|3@0+ (1,0) [0|7] ""  CMM,BVA,SBW,ABS,AAS,E_VCU
 SG_ RollingCounter : 3|4@0+ (1,0) [0|15] ""  CMM,BVA,SBW,ABS,AAS,E_VCU
 SG_ Checksum : 7|4@0+ (1,0) [0|15] ""  CMM,BVA,SBW,ABS,AAS,E_VCU

BO_TX_BU_ 1012 : E_VCU,VCU;
BO_TX_BU_ 1108 : E_VCU,VCU;
BO_TX_BU_ 1128 : E_VCU,CMM;
BO_TX_BU_ 1161 : E_VCU,BVA;
BO_TX_BU_ 1278 : ESM,BSI;
CM_ BO_ 1012 "Observed OBD 6/14 HS1. CAN ID 0x3F4; ID_DLC_match. PSA-RE name: TRACTION_BATTERY_DYNAMIC_DATA_7. Traction battery management data: measured HV current/voltage, disconnect state, unexpected contactor opening and hydrogen detection. Source: https://github.com/prototux/PSA-RE/blob/67f7581e7622410efdbb29c7eda3b86982b9b450/buses/AEE2010.electric/HS.HS1/3F4.yml. Database sender alternatives: E_VCU,VCU. ECU labels are database claims; forwarding/physical transmitter not independently identified. All fitting source fields retained, including default/unavailable-only candidates. See audit/source JSON for exclusions and unresolved alternatives.";
CM_ SG_ 1012 RawByte8_Mux7 "RAW. PSA-RE bits 8.7-8.0. Raw unmapped/padding bits; no physical interpretation.";
CM_ SG_ 1012 BatteryTempSlot49 "DATABASE_CANDIDATE: layout imported; physical meaning not independently verified. PSA-RE bits 8.7-8.0. Logical group/byte temperature slot. Physical sensor numbering and repeated values unverified. Group-7 padding is raw, not a -40 degC sensor. Raw invalid=255; numeric DBC decoders may still scale it: check raw before use.";
CM_ SG_ 1012 BatteryTempSlot42 "DATABASE_CANDIDATE: layout imported; physical meaning not independently verified. PSA-RE bits 8.7-8.0. Logical group/byte temperature slot. Physical sensor numbering and repeated values unverified. Group-7 padding is raw, not a -40 degC sensor. Raw invalid=255; numeric DBC decoders may still scale it: check raw before use.";
CM_ SG_ 1012 BatteryTempSlot35 "DATABASE_CANDIDATE: layout imported; physical meaning not independently verified. PSA-RE bits 8.7-8.0. Logical group/byte temperature slot. Physical sensor numbering and repeated values unverified. Group-7 padding is raw, not a -40 degC sensor. Raw invalid=255; numeric DBC decoders may still scale it: check raw before use.";
CM_ SG_ 1012 BatteryTempSlot28 "DATABASE_CANDIDATE: layout imported; physical meaning not independently verified. PSA-RE bits 8.7-8.0. Logical group/byte temperature slot. Physical sensor numbering and repeated values unverified. Group-7 padding is raw, not a -40 degC sensor. Raw invalid=255; numeric DBC decoders may still scale it: check raw before use.";
CM_ SG_ 1012 BatteryTempSlot21 "DATABASE_CANDIDATE: layout imported; physical meaning not independently verified. PSA-RE bits 8.7-8.0. Logical group/byte temperature slot. Physical sensor numbering and repeated values unverified. Group-7 padding is raw, not a -40 degC sensor. Raw invalid=255; numeric DBC decoders may still scale it: check raw before use.";
CM_ SG_ 1012 BatteryTempSlot14 "DATABASE_CANDIDATE: layout imported; physical meaning not independently verified. PSA-RE bits 8.7-8.0. Logical group/byte temperature slot. Physical sensor numbering and repeated values unverified. Group-7 padding is raw, not a -40 degC sensor. Raw invalid=255; numeric DBC decoders may still scale it: check raw before use.";
CM_ SG_ 1012 BatteryTempSlot07 "DATABASE_CANDIDATE: layout imported; physical meaning not independently verified. PSA-RE bits 8.7-8.0. Logical group/byte temperature slot. Physical sensor numbering and repeated values unverified. Group-7 padding is raw, not a -40 degC sensor. Raw invalid=255; numeric DBC decoders may still scale it: check raw before use.";
CM_ SG_ 1012 RawByte7_Mux7 "RAW. PSA-RE bits 7.7-7.0. Raw unmapped/padding bits; no physical interpretation.";
CM_ SG_ 1012 BatteryTempSlot48 "DATABASE_CANDIDATE: layout imported; physical meaning not independently verified. PSA-RE bits 7.7-7.0. Logical group/byte temperature slot. Physical sensor numbering and repeated values unverified. Group-7 padding is raw, not a -40 degC sensor. Raw invalid=255; numeric DBC decoders may still scale it: check raw before use.";
CM_ SG_ 1012 BatteryTempSlot41 "DATABASE_CANDIDATE: layout imported; physical meaning not independently verified. PSA-RE bits 7.7-7.0. Logical group/byte temperature slot. Physical sensor numbering and repeated values unverified. Group-7 padding is raw, not a -40 degC sensor. Raw invalid=255; numeric DBC decoders may still scale it: check raw before use.";
CM_ SG_ 1012 BatteryTempSlot34 "DATABASE_CANDIDATE: layout imported; physical meaning not independently verified. PSA-RE bits 7.7-7.0. Logical group/byte temperature slot. Physical sensor numbering and repeated values unverified. Group-7 padding is raw, not a -40 degC sensor. Raw invalid=255; numeric DBC decoders may still scale it: check raw before use.";
CM_ SG_ 1012 BatteryTempSlot27 "DATABASE_CANDIDATE: layout imported; physical meaning not independently verified. PSA-RE bits 7.7-7.0. Logical group/byte temperature slot. Physical sensor numbering and repeated values unverified. Group-7 padding is raw, not a -40 degC sensor. Raw invalid=255; numeric DBC decoders may still scale it: check raw before use.";
CM_ SG_ 1012 BatteryTempSlot20 "DATABASE_CANDIDATE: layout imported; physical meaning not independently verified. PSA-RE bits 7.7-7.0. Logical group/byte temperature slot. Physical sensor numbering and repeated values unverified. Group-7 padding is raw, not a -40 degC sensor. Raw invalid=255; numeric DBC decoders may still scale it: check raw before use.";
CM_ SG_ 1012 BatteryTempSlot13 "DATABASE_CANDIDATE: layout imported; physical meaning not independently verified. PSA-RE bits 7.7-7.0. Logical group/byte temperature slot. Physical sensor numbering and repeated values unverified. Group-7 padding is raw, not a -40 degC sensor. Raw invalid=255; numeric DBC decoders may still scale it: check raw before use.";
CM_ SG_ 1012 BatteryTempSlot06 "DATABASE_CANDIDATE: layout imported; physical meaning not independently verified. PSA-RE bits 7.7-7.0. Logical group/byte temperature slot. Physical sensor numbering and repeated values unverified. Group-7 padding is raw, not a -40 degC sensor. Raw invalid=255; numeric DBC decoders may still scale it: check raw before use.";
CM_ SG_ 1012 BatteryTempSlot54 "DATABASE_CANDIDATE: layout imported; physical meaning not independently verified. PSA-RE bits 6.7-6.0. Logical group/byte temperature slot. Physical sensor numbering and repeated values unverified. Group-7 padding is raw, not a -40 degC sensor. Raw invalid=255; numeric DBC decoders may still scale it: check raw before use.";
CM_ SG_ 1012 BatteryTempSlot47 "DATABASE_CANDIDATE: layout imported; physical meaning not independently verified. PSA-RE bits 6.7-6.0. Logical group/byte temperature slot. Physical sensor numbering and repeated values unverified. Group-7 padding is raw, not a -40 degC sensor. Raw invalid=255; numeric DBC decoders may still scale it: check raw before use.";
CM_ SG_ 1012 BatteryTempSlot40 "DATABASE_CANDIDATE: layout imported; physical meaning not independently verified. PSA-RE bits 6.7-6.0. Logical group/byte temperature slot. Physical sensor numbering and repeated values unverified. Group-7 padding is raw, not a -40 degC sensor. Raw invalid=255; numeric DBC decoders may still scale it: check raw before use.";
CM_ SG_ 1012 BatteryTempSlot33 "DATABASE_CANDIDATE: layout imported; physical meaning not independently verified. PSA-RE bits 6.7-6.0. Logical group/byte temperature slot. Physical sensor numbering and repeated values unverified. Group-7 padding is raw, not a -40 degC sensor. Raw invalid=255; numeric DBC decoders may still scale it: check raw before use.";
CM_ SG_ 1012 BatteryTempSlot26 "DATABASE_CANDIDATE: layout imported; physical meaning not independently verified. PSA-RE bits 6.7-6.0. Logical group/byte temperature slot. Physical sensor numbering and repeated values unverified. Group-7 padding is raw, not a -40 degC sensor. Raw invalid=255; numeric DBC decoders may still scale it: check raw before use.";
CM_ SG_ 1012 BatteryTempSlot19 "DATABASE_CANDIDATE: layout imported; physical meaning not independently verified. PSA-RE bits 6.7-6.0. Logical group/byte temperature slot. Physical sensor numbering and repeated values unverified. Group-7 padding is raw, not a -40 degC sensor. Raw invalid=255; numeric DBC decoders may still scale it: check raw before use.";
CM_ SG_ 1012 BatteryTempSlot12 "DATABASE_CANDIDATE: layout imported; physical meaning not independently verified. PSA-RE bits 6.7-6.0. Logical group/byte temperature slot. Physical sensor numbering and repeated values unverified. Group-7 padding is raw, not a -40 degC sensor. Raw invalid=255; numeric DBC decoders may still scale it: check raw before use.";
CM_ SG_ 1012 BatteryTempSlot05 "DATABASE_CANDIDATE: layout imported; physical meaning not independently verified. PSA-RE bits 6.7-6.0. Logical group/byte temperature slot. Physical sensor numbering and repeated values unverified. Group-7 padding is raw, not a -40 degC sensor. Raw invalid=255; numeric DBC decoders may still scale it: check raw before use.";
CM_ SG_ 1012 BatteryTempSlot53 "DATABASE_CANDIDATE: layout imported; physical meaning not independently verified. PSA-RE bits 5.7-5.0. Logical group/byte temperature slot. Physical sensor numbering and repeated values unverified. Group-7 padding is raw, not a -40 degC sensor. Raw invalid=255; numeric DBC decoders may still scale it: check raw before use.";
CM_ SG_ 1012 BatteryTempSlot46 "DATABASE_CANDIDATE: layout imported; physical meaning not independently verified. PSA-RE bits 5.7-5.0. Logical group/byte temperature slot. Physical sensor numbering and repeated values unverified. Group-7 padding is raw, not a -40 degC sensor. Raw invalid=255; numeric DBC decoders may still scale it: check raw before use.";
CM_ SG_ 1012 BatteryTempSlot39 "DATABASE_CANDIDATE: layout imported; physical meaning not independently verified. PSA-RE bits 5.7-5.0. Logical group/byte temperature slot. Physical sensor numbering and repeated values unverified. Group-7 padding is raw, not a -40 degC sensor. Raw invalid=255; numeric DBC decoders may still scale it: check raw before use.";
CM_ SG_ 1012 BatteryTempSlot32 "DATABASE_CANDIDATE: layout imported; physical meaning not independently verified. PSA-RE bits 5.7-5.0. Logical group/byte temperature slot. Physical sensor numbering and repeated values unverified. Group-7 padding is raw, not a -40 degC sensor. Raw invalid=255; numeric DBC decoders may still scale it: check raw before use.";
CM_ SG_ 1012 BatteryTempSlot25 "DATABASE_CANDIDATE: layout imported; physical meaning not independently verified. PSA-RE bits 5.7-5.0. Logical group/byte temperature slot. Physical sensor numbering and repeated values unverified. Group-7 padding is raw, not a -40 degC sensor. Raw invalid=255; numeric DBC decoders may still scale it: check raw before use.";
CM_ SG_ 1012 BatteryTempSlot18 "DATABASE_CANDIDATE: layout imported; physical meaning not independently verified. PSA-RE bits 5.7-5.0. Logical group/byte temperature slot. Physical sensor numbering and repeated values unverified. Group-7 padding is raw, not a -40 degC sensor. Raw invalid=255; numeric DBC decoders may still scale it: check raw before use.";
CM_ SG_ 1012 BatteryTempSlot11 "DATABASE_CANDIDATE: layout imported; physical meaning not independently verified. PSA-RE bits 5.7-5.0. Logical group/byte temperature slot. Physical sensor numbering and repeated values unverified. Group-7 padding is raw, not a -40 degC sensor. Raw invalid=255; numeric DBC decoders may still scale it: check raw before use.";
CM_ SG_ 1012 BatteryTempSlot04 "DATABASE_CANDIDATE: layout imported; physical meaning not independently verified. PSA-RE bits 5.7-5.0. Logical group/byte temperature slot. Physical sensor numbering and repeated values unverified. Group-7 padding is raw, not a -40 degC sensor. Raw invalid=255; numeric DBC decoders may still scale it: check raw before use.";
CM_ SG_ 1012 BatteryTempSlot52 "DATABASE_CANDIDATE: layout imported; physical meaning not independently verified. PSA-RE bits 4.7-4.0. Logical group/byte temperature slot. Physical sensor numbering and repeated values unverified. Group-7 padding is raw, not a -40 degC sensor. Raw invalid=255; numeric DBC decoders may still scale it: check raw before use.";
CM_ SG_ 1012 BatteryTempSlot45 "DATABASE_CANDIDATE: layout imported; physical meaning not independently verified. PSA-RE bits 4.7-4.0. Logical group/byte temperature slot. Physical sensor numbering and repeated values unverified. Group-7 padding is raw, not a -40 degC sensor. Raw invalid=255; numeric DBC decoders may still scale it: check raw before use.";
CM_ SG_ 1012 BatteryTempSlot38 "DATABASE_CANDIDATE: layout imported; physical meaning not independently verified. PSA-RE bits 4.7-4.0. Logical group/byte temperature slot. Physical sensor numbering and repeated values unverified. Group-7 padding is raw, not a -40 degC sensor. Raw invalid=255; numeric DBC decoders may still scale it: check raw before use.";
CM_ SG_ 1012 BatteryTempSlot31 "DATABASE_CANDIDATE: layout imported; physical meaning not independently verified. PSA-RE bits 4.7-4.0. Logical group/byte temperature slot. Physical sensor numbering and repeated values unverified. Group-7 padding is raw, not a -40 degC sensor. Raw invalid=255; numeric DBC decoders may still scale it: check raw before use.";
CM_ SG_ 1012 BatteryTempSlot24 "DATABASE_CANDIDATE: layout imported; physical meaning not independently verified. PSA-RE bits 4.7-4.0. Logical group/byte temperature slot. Physical sensor numbering and repeated values unverified. Group-7 padding is raw, not a -40 degC sensor. Raw invalid=255; numeric DBC decoders may still scale it: check raw before use.";
CM_ SG_ 1012 BatteryTempSlot17 "DATABASE_CANDIDATE: layout imported; physical meaning not independently verified. PSA-RE bits 4.7-4.0. Logical group/byte temperature slot. Physical sensor numbering and repeated values unverified. Group-7 padding is raw, not a -40 degC sensor. Raw invalid=255; numeric DBC decoders may still scale it: check raw before use.";
CM_ SG_ 1012 BatteryTempSlot10 "DATABASE_CANDIDATE: layout imported; physical meaning not independently verified. PSA-RE bits 4.7-4.0. Logical group/byte temperature slot. Physical sensor numbering and repeated values unverified. Group-7 padding is raw, not a -40 degC sensor. Raw invalid=255; numeric DBC decoders may still scale it: check raw before use.";
CM_ SG_ 1012 BatteryTempSlot03 "DATABASE_CANDIDATE: layout imported; physical meaning not independently verified. PSA-RE bits 4.7-4.0. Logical group/byte temperature slot. Physical sensor numbering and repeated values unverified. Group-7 padding is raw, not a -40 degC sensor. Raw invalid=255; numeric DBC decoders may still scale it: check raw before use.";
CM_ SG_ 1012 BatteryTempSlot51 "DATABASE_CANDIDATE: layout imported; physical meaning not independently verified. PSA-RE bits 3.7-3.0. Logical group/byte temperature slot. Physical sensor numbering and repeated values unverified. Group-7 padding is raw, not a -40 degC sensor. Raw invalid=255; numeric DBC decoders may still scale it: check raw before use.";
CM_ SG_ 1012 BatteryTempSlot44 "DATABASE_CANDIDATE: layout imported; physical meaning not independently verified. PSA-RE bits 3.7-3.0. Logical group/byte temperature slot. Physical sensor numbering and repeated values unverified. Group-7 padding is raw, not a -40 degC sensor. Raw invalid=255; numeric DBC decoders may still scale it: check raw before use.";
CM_ SG_ 1012 BatteryTempSlot37 "DATABASE_CANDIDATE: layout imported; physical meaning not independently verified. PSA-RE bits 3.7-3.0. Logical group/byte temperature slot. Physical sensor numbering and repeated values unverified. Group-7 padding is raw, not a -40 degC sensor. Raw invalid=255; numeric DBC decoders may still scale it: check raw before use.";
CM_ SG_ 1012 BatteryTempSlot30 "DATABASE_CANDIDATE: layout imported; physical meaning not independently verified. PSA-RE bits 3.7-3.0. Logical group/byte temperature slot. Physical sensor numbering and repeated values unverified. Group-7 padding is raw, not a -40 degC sensor. Raw invalid=255; numeric DBC decoders may still scale it: check raw before use.";
CM_ SG_ 1012 BatteryTempSlot23 "DATABASE_CANDIDATE: layout imported; physical meaning not independently verified. PSA-RE bits 3.7-3.0. Logical group/byte temperature slot. Physical sensor numbering and repeated values unverified. Group-7 padding is raw, not a -40 degC sensor. Raw invalid=255; numeric DBC decoders may still scale it: check raw before use.";
CM_ SG_ 1012 BatteryTempSlot16 "DATABASE_CANDIDATE: layout imported; physical meaning not independently verified. PSA-RE bits 3.7-3.0. Logical group/byte temperature slot. Physical sensor numbering and repeated values unverified. Group-7 padding is raw, not a -40 degC sensor. Raw invalid=255; numeric DBC decoders may still scale it: check raw before use.";
CM_ SG_ 1012 BatteryTempSlot09 "DATABASE_CANDIDATE: layout imported; physical meaning not independently verified. PSA-RE bits 3.7-3.0. Logical group/byte temperature slot. Physical sensor numbering and repeated values unverified. Group-7 padding is raw, not a -40 degC sensor. Raw invalid=255; numeric DBC decoders may still scale it: check raw before use.";
CM_ SG_ 1012 BatteryTempSlot02 "DATABASE_CANDIDATE: layout imported; physical meaning not independently verified. PSA-RE bits 3.7-3.0. Logical group/byte temperature slot. Physical sensor numbering and repeated values unverified. Group-7 padding is raw, not a -40 degC sensor. Raw invalid=255; numeric DBC decoders may still scale it: check raw before use.";
CM_ SG_ 1012 BatteryTempSlot50 "DATABASE_CANDIDATE: layout imported; physical meaning not independently verified. PSA-RE bits 2.7-2.0. Logical group/byte temperature slot. Physical sensor numbering and repeated values unverified. Group-7 padding is raw, not a -40 degC sensor. Raw invalid=255; numeric DBC decoders may still scale it: check raw before use.";
CM_ SG_ 1012 BatteryTempSlot43 "DATABASE_CANDIDATE: layout imported; physical meaning not independently verified. PSA-RE bits 2.7-2.0. Logical group/byte temperature slot. Physical sensor numbering and repeated values unverified. Group-7 padding is raw, not a -40 degC sensor. Raw invalid=255; numeric DBC decoders may still scale it: check raw before use.";
CM_ SG_ 1012 BatteryTempSlot36 "DATABASE_CANDIDATE: layout imported; physical meaning not independently verified. PSA-RE bits 2.7-2.0. Logical group/byte temperature slot. Physical sensor numbering and repeated values unverified. Group-7 padding is raw, not a -40 degC sensor. Raw invalid=255; numeric DBC decoders may still scale it: check raw before use.";
CM_ SG_ 1012 BatteryTempSlot29 "DATABASE_CANDIDATE: layout imported; physical meaning not independently verified. PSA-RE bits 2.7-2.0. Logical group/byte temperature slot. Physical sensor numbering and repeated values unverified. Group-7 padding is raw, not a -40 degC sensor. Raw invalid=255; numeric DBC decoders may still scale it: check raw before use.";
CM_ SG_ 1012 BatteryTempSlot22 "DATABASE_CANDIDATE: layout imported; physical meaning not independently verified. PSA-RE bits 2.7-2.0. Logical group/byte temperature slot. Physical sensor numbering and repeated values unverified. Group-7 padding is raw, not a -40 degC sensor. Raw invalid=255; numeric DBC decoders may still scale it: check raw before use.";
CM_ SG_ 1012 BatteryTempSlot15 "DATABASE_CANDIDATE: layout imported; physical meaning not independently verified. PSA-RE bits 2.7-2.0. Logical group/byte temperature slot. Physical sensor numbering and repeated values unverified. Group-7 padding is raw, not a -40 degC sensor. Raw invalid=255; numeric DBC decoders may still scale it: check raw before use.";
CM_ SG_ 1012 BatteryTempSlot08 "DATABASE_CANDIDATE: layout imported; physical meaning not independently verified. PSA-RE bits 2.7-2.0. Logical group/byte temperature slot. Physical sensor numbering and repeated values unverified. Group-7 padding is raw, not a -40 degC sensor. Raw invalid=255; numeric DBC decoders may still scale it: check raw before use.";
CM_ SG_ 1012 BatteryTempSlot01 "DATABASE_CANDIDATE: layout imported; physical meaning not independently verified. PSA-RE bits 2.7-2.0. Logical group/byte temperature slot. Physical sensor numbering and repeated values unverified. Group-7 padding is raw, not a -40 degC sensor. Raw invalid=255; numeric DBC decoders may still scale it: check raw before use.";
CM_ SG_ 1012 RawBits3_7 "RAW. PSA-RE bits 1.4-1.0. Raw unmapped/padding bits; no physical interpretation.";
CM_ SG_ 1012 TemperatureGroup "SUPPORTED_CAPTURE: group counter. PSA-RE bits 1.7-1.5. Source group index; logical slots do not assert installed sensor identities.";
CM_ BO_ 1018 "Observed OBD 6/14 HS1. CAN ID 0x3FA; no_HS1_definition. PSA-RE name: unknown.  Source: none in HS.HS1. Database sender alternatives: unknown. ECU labels are database claims; forwarding/physical transmitter not independently identified. All fitting source fields retained, including default/unavailable-only candidates. See audit/source JSON for exclusions and unresolved alternatives.";
CM_ SG_ 1018 RawByte2 "RAW. PSA-RE bits 2.7-2.0. Raw unmapped/padding bits; no physical interpretation.";
CM_ SG_ 1018 RawByte1 "RAW. PSA-RE bits 1.7-1.0. Raw unmapped/padding bits; no physical interpretation.";
CM_ BO_ 1035 "Observed OBD 6/14 HS1. CAN ID 0x40B; DLC_unspecified. PSA-RE name: SECONDARY_LANE_LINE_DATA. Secondary lane line detection data from the camera module (CVM): distance to left/right line and detection type for lane-keeping. Source: https://github.com/prototux/PSA-RE/blob/67f7581e7622410efdbb29c7eda3b86982b9b450/buses/AEE2010.full/HS.HS1/40B.yml. Database sender alternatives: CVM. ECU labels are database claims; forwarding/physical transmitter not independently identified. All fitting source fields retained, including default/unavailable-only candidates. See audit/source JSON for exclusions and unresolved alternatives.";
CM_ SG_ 1035 Unused1 "DATABASE_CANDIDATE: layout imported; physical meaning not independently verified. PSA-RE bits 4.3-4.0. ";
CM_ SG_ 1035 SecondaryRightLineLkaStatus "DATABASE_CANDIDATE: layout imported; physical meaning not independently verified. PSA-RE bits 4.4. Secondary right line status for the LKA function, seen by the camera Upstream default raw=0 (not necessarily valid data).";
CM_ SG_ 1035 SecondaryRightLineType "DATABASE_CANDIDATE: layout imported; physical meaning not independently verified. PSA-RE bits 4.7-4.5. Secondary right line type, seen by the camera Upstream default raw=0 (not necessarily valid data).";
CM_ SG_ 1035 SecondaryLeftLineLkaStatus "DATABASE_CANDIDATE: layout imported; physical meaning not independently verified. PSA-RE bits 3.0. Secondary left line status for the LKA function, seen by the camera Upstream default raw=0 (not necessarily valid data).";
CM_ SG_ 1035 SecondaryLeftLineType "DATABASE_CANDIDATE: layout imported; physical meaning not independently verified. PSA-RE bits 3.3-3.1. Secondary left line type, seen by the camera Upstream default raw=0 (not necessarily valid data).";
CM_ SG_ 1035 SecondaryRightLineDistance "DATABASE_CANDIDATE: layout imported; physical meaning not independently verified. PSA-RE bits 2.5-3.4. Distance from the camera to the secondary right line edge Raw invalid=511; numeric DBC decoders may still scale it: check raw before use. Upstream default raw=510 (not necessarily valid data).";
CM_ SG_ 1035 SecondaryLeftLineDistance "DATABASE_CANDIDATE: layout imported; physical meaning not independently verified. PSA-RE bits 1.7-2.6. Distance from the camera to the secondary left line edge Raw invalid=511; numeric DBC decoders may still scale it: check raw before use. Upstream default raw=510 (not necessarily valid data).";
CM_ BO_ 1037 "Observed OBD 6/14 HS1. CAN ID 0x40D; ID_DLC_match. PSA-RE name: WHEEL_SPEED_RAW_2. Unfiltered wheel speeds, front and rear, left and right. Source: https://github.com/prototux/PSA-RE/blob/67f7581e7622410efdbb29c7eda3b86982b9b450/buses/AEE2010.full/HS.HS1/40D.yml. Database sender alternatives: ABS. ECU labels are database claims; forwarding/physical transmitter not independently identified. All fitting source fields retained, including default/unavailable-only candidates. See audit/source JSON for exclusions and unresolved alternatives.";
CM_ SG_ 1037 ProcessCounter4bit "DATABASE_CANDIDATE: layout imported; physical meaning not independently verified. PSA-RE bits 8.3-8.0. 4-bit process counter Upstream default raw=0 (not necessarily valid data).";
CM_ SG_ 1037 RearRightWheelPulseCounter14bit "DATABASE_CANDIDATE: layout imported; physical meaning not independently verified. PSA-RE bits 6.1-8.4. 14-bit free-running pulse counter, rear right wheel Upstream default raw=0 (not necessarily valid data).";
CM_ SG_ 1037 RearRightWheelSpeedSensorFault "DATABASE_CANDIDATE: layout imported; physical meaning not independently verified. PSA-RE bits 6.2. Rear right wheel-speed pulse counter malfunction Upstream default raw=0 (not necessarily valid data).";
CM_ SG_ 1037 RearLeftWheelPulseCounter14bit "DATABASE_CANDIDATE: layout imported; physical meaning not independently verified. PSA-RE bits 4.0-6.3. 14-bit free-running pulse counter, rear left wheel Upstream default raw=0 (not necessarily valid data).";
CM_ SG_ 1037 RearLeftWheelSpeedSensorFault "DATABASE_CANDIDATE: layout imported; physical meaning not independently verified. PSA-RE bits 4.1. Rear left wheel-speed pulse counter malfunction Upstream default raw=0 (not necessarily valid data).";
CM_ SG_ 1037 FrontRightWheelPulseCounter14bit "DATABASE_CANDIDATE: layout imported; physical meaning not independently verified. PSA-RE bits 3.7-4.2. 14-bit free-running pulse counter, front right wheel Upstream default raw=0 (not necessarily valid data).";
CM_ SG_ 1037 FrontRightWheelSpeedSensorFault "DATABASE_CANDIDATE: layout imported; physical meaning not independently verified. PSA-RE bits 2.0. Front right wheel-speed pulse counter malfunction Upstream default raw=0 (not necessarily valid data).";
CM_ SG_ 1037 FrontLeftWheelPulseCounter14bit "DATABASE_CANDIDATE: layout imported; physical meaning not independently verified. PSA-RE bits 1.6-2.1. 14-bit free-running pulse counter, front left wheel Upstream default raw=0 (not necessarily valid data).";
CM_ SG_ 1037 FrontLeftWheelSpeedSensorFault "DATABASE_CANDIDATE: layout imported; physical meaning not independently verified. PSA-RE bits 1.7. Front left wheel-speed pulse counter malfunction Upstream default raw=0 (not necessarily valid data).";
CM_ BO_ 1038 "Observed OBD 6/14 HS1. CAN ID 0x40E; ID_DLC_match. PSA-RE name: BSI_DATA_2. Body controller data 7: left/right indicator requests, low/high-beam state, fuel level info, and daytime-running/motorway/town/dynamic-bend lighting inhibitions. Source: https://github.com/prototux/PSA-RE/blob/67f7581e7622410efdbb29c7eda3b86982b9b450/buses/AEE2010.full/HS.HS1/40E.yml. Database sender alternatives: BSI. ECU labels are database claims; forwarding/physical transmitter not independently identified. All fitting source fields retained, including default/unavailable-only candidates. See audit/source JSON for exclusions and unresolved alternatives.";
CM_ SG_ 1038 HighBeamCommand "DATABASE_CANDIDATE: layout imported; physical meaning not independently verified. PSA-RE bits 5.0. High beam headlights command Upstream default raw=0 (not necessarily valid data).";
CM_ SG_ 1038 LowBeamCommand "DATABASE_CANDIDATE: layout imported; physical meaning not independently verified. PSA-RE bits 5.1. Low beam headlights command Upstream default raw=0 (not necessarily valid data).";
CM_ SG_ 1038 HeadlightFlashCommand "DATABASE_CANDIDATE: layout imported; physical meaning not independently verified. PSA-RE bits 5.2. Headlight flash command Upstream default raw=0 (not necessarily valid data).";
CM_ SG_ 1038 SideLightsCommand "DATABASE_CANDIDATE: layout imported; physical meaning not independently verified. PSA-RE bits 5.3. Side (position) lights command Upstream default raw=0 (not necessarily valid data).";
CM_ SG_ 1038 WelcomeLightingMode "DATABASE_CANDIDATE: layout imported; physical meaning not independently verified. PSA-RE bits 5.7-5.4. Welcome lighting mode (RGB LED duration at unlocking) Upstream default raw=0 (not necessarily valid data).";
CM_ SG_ 1038 Unused1 "DATABASE_CANDIDATE: layout imported; physical meaning not independently verified. PSA-RE bits 4.6-4.0. ";
CM_ SG_ 1038 MatrixBeamCommand "DATABASE_CANDIDATE: layout imported; physical meaning not independently verified. PSA-RE bits 4.7. MatrixBeam headlight function command Upstream default raw=0 (not necessarily valid data).";
CM_ SG_ 1038 DriverSide "DATABASE_CANDIDATE: layout imported; physical meaning not independently verified. PSA-RE bits 3.1-3.0. Side of the vehicle where the driver's seat is installed Upstream default raw=0 (not necessarily valid data).";
CM_ SG_ 1038 WelcomeModePositionLedIntensity "DATABASE_CANDIDATE: layout imported; physical meaning not independently verified. PSA-RE bits 3.5-3.2. Intensity level of the position LEDs in welcome mode Upstream default raw=8 (not necessarily valid data).";
CM_ SG_ 1038 DrlCommand "DATABASE_CANDIDATE: layout imported; physical meaning not independently verified. PSA-RE bits 3.6. Daytime running lights (DRL) command Upstream default raw=0 (not necessarily valid data).";
CM_ SG_ 1038 ThreeModuleCutoffRequest "DATABASE_CANDIDATE: layout imported; physical meaning not independently verified. PSA-RE bits 3.7. Cutoff request for the three additional modules Upstream default raw=0 (not necessarily valid data).";
CM_ SG_ 1038 RgbLedIntensity "DATABASE_CANDIDATE: layout imported; physical meaning not independently verified. PSA-RE bits 2.3-2.0. RGB LED intensity level Upstream default raw=8 (not necessarily valid data).";
CM_ SG_ 1038 WelcomeScreenColor "DATABASE_CANDIDATE: layout imported; physical meaning not independently verified. PSA-RE bits 2.7-2.4. Welcome screen color setting Upstream default raw=0 (not necessarily valid data).";
CM_ SG_ 1038 FrameChecksum40e "DATABASE_CANDIDATE: layout imported; physical meaning not independently verified. PSA-RE bits 1.3-1.0. Checksum of frame 0x40E (initial value 0x2)";
CM_ SG_ 1038 ProcessCounter40e "DATABASE_CANDIDATE: layout imported; physical meaning not independently verified. PSA-RE bits 1.7-1.4. 4-bit rolling process counter of frame 0x40E Upstream default raw=0 (not necessarily valid data).";
CM_ BO_ 1042 "Observed OBD 6/14 HS1. CAN ID 0x412; ID_DLC_match. PSA-RE name: BSI_CABIN_DATA_4. Body controller cabin data: hybrid blower setpoint, load-shedding requests for ABS/ESP, electric power steering, EasyMove and suspension, demisting request and hybrid zero-emission cabin inhibition. Source: https://github.com/prototux/PSA-RE/blob/67f7581e7622410efdbb29c7eda3b86982b9b450/buses/AEE2010.full/HS.HS1/412.yml. Database sender alternatives: BSI. ECU labels are database claims; forwarding/physical transmitter not independently identified. All fitting source fields retained, including default/unavailable-only candidates. See audit/source JSON for exclusions and unresolved alternatives.";
CM_ SG_ 1042 FapDownstreamTemperature "DATABASE_CANDIDATE: layout imported; physical meaning not independently verified. PSA-RE bits 8.7-8.0. Temperature downstream of the particulate filter (FAP), monitored by the CMM Raw invalid=255; numeric DBC decoders may still scale it: check raw before use.";
CM_ SG_ 1042 MinAdditiveLevelReached "DATABASE_CANDIDATE: layout imported; physical meaning not independently verified. PSA-RE bits 7.1-7.0. Minimum exhaust additive (AdBlue) level reached Upstream default raw=3 (not necessarily valid data).";
CM_ SG_ 1042 RearWindowStatus "DATABASE_CANDIDATE: layout imported; physical meaning not independently verified. PSA-RE bits 7.2. Rear window status Upstream default raw=0 (not necessarily valid data).";
CM_ SG_ 1042 DoorsStatus "DATABASE_CANDIDATE: layout imported; physical meaning not independently verified. PSA-RE bits 7.7-7.3. Doors/openings state (5 bits) Upstream default raw=0 (not necessarily valid data).";
CM_ SG_ 1042 EngineOilTemperatureBsi "DATABASE_CANDIDATE: layout imported; physical meaning not independently verified. PSA-RE bits 6.7-6.0. Engine oil temperature, as acquired by the BSI Raw invalid=255; numeric DBC decoders may still scale it: check raw before use. Upstream default raw=20 (not necessarily valid data).";
CM_ SG_ 1042 SlidingRoofState "DATABASE_CANDIDATE: layout imported; physical meaning not independently verified. PSA-RE bits 5.1-5.0. Sliding roof position state Upstream default raw=3 (not necessarily valid data).";
CM_ SG_ 1042 Unused6 "DATABASE_CANDIDATE: layout imported; physical meaning not independently verified. PSA-RE bits 5.3-5.2. ";
CM_ SG_ 1042 Unused5 "DATABASE_CANDIDATE: layout imported; physical meaning not independently verified. PSA-RE bits 5.7-5.4. ";
CM_ SG_ 1042 FuelLow "DATABASE_CANDIDATE: layout imported; physical meaning not independently verified. PSA-RE bits 4.0. Minimum fuel level reached Upstream default raw=0 (not necessarily valid data).";
CM_ SG_ 1042 FuelGaugeDiagnostic "DATABASE_CANDIDATE: layout imported; physical meaning not independently verified. PSA-RE bits 4.2-4.1. Fuel gauge diagnostic (low fuel, invalid, short-circuit, open circuit) Upstream default raw=0 (not necessarily valid data).";
CM_ SG_ 1042 Unused4 "DATABASE_CANDIDATE: layout imported; physical meaning not independently verified. PSA-RE bits 4.5-4.3. ";
CM_ SG_ 1042 PowerSteeringModeRequest "DATABASE_CANDIDATE: layout imported; physical meaning not independently verified. PSA-RE bits 4.7-4.6. Power steering multi-mode request Upstream default raw=0 (not necessarily valid data).";
CM_ SG_ 1042 GearboxSnowSwitch "DATABASE_CANDIDATE: layout imported; physical meaning not independently verified. PSA-RE bits 3.0. Gearbox snow mode switch pressed Upstream default raw=0 (not necessarily valid data).";
CM_ SG_ 1042 GearboxSportSwitch "DATABASE_CANDIDATE: layout imported; physical meaning not independently verified. PSA-RE bits 3.1. Gearbox sport mode switch pressed Upstream default raw=0 (not necessarily valid data).";
CM_ SG_ 1042 GearboxPaddleInfo "DATABASE_CANDIDATE: layout imported; physical meaning not independently verified. PSA-RE bits 3.3-3.2. Gearbox paddle shifter information (upshift/downshift request) Upstream default raw=0 (not necessarily valid data).";
CM_ SG_ 1042 Unused3 "DATABASE_CANDIDATE: layout imported; physical meaning not independently verified. PSA-RE bits 3.6-3.4. ";
CM_ SG_ 1042 AsrEspDisconnectRequest "DATABASE_CANDIDATE: layout imported; physical meaning not independently verified. PSA-RE bits 3.7. ASR or ESP disconnection request Upstream default raw=0 (not necessarily valid data).";
CM_ SG_ 1042 Unused2 "DATABASE_CANDIDATE: layout imported; physical meaning not independently verified. PSA-RE bits 2.0. ";
CM_ SG_ 1042 BrakeSwitchDiagnosticCondition "DATABASE_CANDIDATE: layout imported; physical meaning not independently verified. PSA-RE bits 2.1. Brake pedal switch diagnostic window condition Upstream default raw=0 (not necessarily valid data).";
CM_ SG_ 1042 EngineOilMeasurementRequest "DATABASE_CANDIDATE: layout imported; physical meaning not independently verified. PSA-RE bits 2.2. Engine oil measurement request Upstream default raw=0 (not necessarily valid data).";
CM_ SG_ 1042 CabinHeatingRequest "DATABASE_CANDIDATE: layout imported; physical meaning not independently verified. PSA-RE bits 2.3. Cabin heating system activation request Upstream default raw=0 (not necessarily valid data).";
CM_ SG_ 1042 AdaptiveDampingModeRequest "DATABASE_CANDIDATE: layout imported; physical meaning not independently verified. PSA-RE bits 2.5-2.4. Adaptive damping mode request Upstream default raw=0 (not necessarily valid data).";
CM_ SG_ 1042 Unused1 "DATABASE_CANDIDATE: layout imported; physical meaning not independently verified. PSA-RE bits 2.7-2.6. ";
CM_ SG_ 1042 BrakePedalSwitchDisabled "DATABASE_CANDIDATE: layout imported; physical meaning not independently verified. PSA-RE bits 1.0. Main brake pedal switch out-of-service status Upstream default raw=0 (not necessarily valid data).";
CM_ SG_ 1042 GearboxManualModePushRequest "DATABASE_CANDIDATE: layout imported; physical meaning not independently verified. PSA-RE bits 1.1. Manual gearbox mode request via push button Upstream default raw=0 (not necessarily valid data).";
CM_ SG_ 1042 ReverseGearManualGearbox "DATABASE_CANDIDATE: layout imported; physical meaning not independently verified. PSA-RE bits 1.2. Reverse gear engaged (manual gearbox) Upstream default raw=0 (not necessarily valid data).";
CM_ SG_ 1042 ParkingBrakeSwitch "DATABASE_CANDIDATE: layout imported; physical meaning not independently verified. PSA-RE bits 1.3. Handbrake (parking brake) switch state Upstream default raw=0 (not necessarily valid data).";
CM_ SG_ 1042 DynamicPackActivationComplement "DATABASE_CANDIDATE: layout imported; physical meaning not independently verified. PSA-RE bits 1.4. Complement of the dynamic pack activation signal Upstream default raw=1 (not necessarily valid data).";
CM_ SG_ 1042 BrakePedalSwitch "DATABASE_CANDIDATE: layout imported; physical meaning not independently verified. PSA-RE bits 1.5. Main brake pedal switch state Upstream default raw=0 (not necessarily valid data).";
CM_ SG_ 1042 DynamicPackActivation "DATABASE_CANDIDATE: layout imported; physical meaning not independently verified. PSA-RE bits 1.6. Dynamic driving pack activation request Upstream default raw=0 (not necessarily valid data).";
CM_ SG_ 1042 ElectricalSystemNeedFault "DATABASE_CANDIDATE: layout imported; physical meaning not independently verified. PSA-RE bits 1.7. Electrical system need management fault Upstream default raw=0 (not necessarily valid data).";
CM_ BO_ 1054 "Observed OBD 6/14 HS1. CAN ID 0x41E; ID_DLC_match. PSA-RE name: CAMERA_LANE_TRACKING_DATA. Camera lane-tracking data: lead-vehicle lane-crossing flags, cluster angle/distance left and right, minimum cluster distance/angle and perception status. Source: https://github.com/prototux/PSA-RE/blob/67f7581e7622410efdbb29c7eda3b86982b9b450/buses/AEE2010.full/HS.HS1/41E.yml. Database sender alternatives: CVM. ECU labels are database claims; forwarding/physical transmitter not independently identified. All fitting source fields retained, including default/unavailable-only candidates. See audit/source JSON for exclusions and unresolved alternatives.";
CM_ SG_ 1054 Unused1 "DATABASE_CANDIDATE: layout imported; physical meaning not independently verified. PSA-RE bits 8.2-8.0. ";
CM_ SG_ 1054 MatrixBeamPerceptionStatus "DATABASE_CANDIDATE: layout imported; physical meaning not independently verified. PSA-RE bits 8.4-8.3. Matrix LED beam perception function status Upstream default raw=2 (not necessarily valid data).";
CM_ SG_ 1054 ClusterMinDistance "DATABASE_CANDIDATE: layout imported; physical meaning not independently verified. PSA-RE bits 7.5-8.5. Minimum horizontal distance to the closest detected vehicle in the camera's field of view (m) Upstream default raw=0 (not necessarily valid data).";
CM_ SG_ 1054 CenterLeadVehicleCrossState "DATABASE_CANDIDATE: layout imported; physical meaning not independently verified. PSA-RE bits 7.7-7.6. Orientation of the vehicle detected at the far right of the camera's field of view (approaching or moving away) Upstream default raw=3 (not necessarily valid data).";
CM_ SG_ 1054 ClusterMinVerticalAngle "DATABASE_CANDIDATE: layout imported; physical meaning not independently verified. PSA-RE bits 6.7-6.0. Vertical angle of the closest detected vehicle in the camera's field of view (%rad) Raw invalid=127; numeric DBC decoders may still scale it: check raw before use. Upstream default raw=0 (not necessarily valid data).";
CM_ SG_ 1054 RightLeadVehicleCrossState "DATABASE_CANDIDATE: layout imported; physical meaning not independently verified. PSA-RE bits 5.1-5.0. Orientation of the vehicle detected at the far right of the camera's field of view (approaching or moving away) Upstream default raw=3 (not necessarily valid data).";
CM_ SG_ 1054 ClusterRightEdgeAngle "DATABASE_CANDIDATE: layout imported; physical meaning not independently verified. PSA-RE bits 4.2-5.2. Horizontal angle to the far-right edge of the detected vehicle in the camera's field of view (°) Raw invalid=255; numeric DBC decoders may still scale it: check raw before use. Upstream default raw=0 (not necessarily valid data).";
CM_ SG_ 1054 ClusterRightEdgeDistance "DATABASE_CANDIDATE: layout imported; physical meaning not independently verified. PSA-RE bits 3.3-4.3. Horizontal distance to the far-right edge of the detected vehicle in the camera's field of view (m) Raw invalid=511; numeric DBC decoders may still scale it: check raw before use. Upstream default raw=0 (not necessarily valid data).";
CM_ SG_ 1054 LeftLeadVehicleCrossState "DATABASE_CANDIDATE: layout imported; physical meaning not independently verified. PSA-RE bits 3.5-3.4. Orientation of the vehicle detected at the far left of the camera's field of view (approaching or moving away) Upstream default raw=3 (not necessarily valid data).";
CM_ SG_ 1054 ClusterLeftEdgeAngle "DATABASE_CANDIDATE: layout imported; physical meaning not independently verified. PSA-RE bits 2.6-3.6. Horizontal angle to the far-left edge of the detected vehicle in the camera's field of view (°) Raw invalid=255; numeric DBC decoders may still scale it: check raw before use. Upstream default raw=0 (not necessarily valid data).";
CM_ SG_ 1054 ClusterLeftEdgeDistance "DATABASE_CANDIDATE: layout imported; physical meaning not independently verified. PSA-RE bits 1.7-2.7. Horizontal distance to the far-left edge of the detected vehicle in the camera's field of view (m) Raw invalid=511; numeric DBC decoders may still scale it: check raw before use. Upstream default raw=0 (not necessarily valid data).";
CM_ BO_ 1067 "Observed OBD 6/14 HS1. CAN ID 0x42B; DLC_unspecified. PSA-RE name: LEFT_LANE_LINE_INFO. Left lane line detection data from the front camera: curvature, heading angle, line type and detection status for lane keeping and departure warning. Source: https://github.com/prototux/PSA-RE/blob/67f7581e7622410efdbb29c7eda3b86982b9b450/buses/AEE2010.full/HS.HS1/42B.yml. Database sender alternatives: CVM. ECU labels are database claims; forwarding/physical transmitter not independently identified. All fitting source fields retained, including default/unavailable-only candidates. See audit/source JSON for exclusions and unresolved alternatives.";
CM_ SG_ 1067 Unused1 "DATABASE_CANDIDATE: layout imported; physical meaning not independently verified. PSA-RE bits 8.3-8.0. ";
CM_ SG_ 1067 LkaCameraFault "DATABASE_CANDIDATE: layout imported; physical meaning not independently verified. PSA-RE bits 8.4. Camera module fault status for the lane keeping assist (LKA) function Upstream default raw=0 (not necessarily valid data).";
CM_ SG_ 1067 LeftLineValidityLka "DATABASE_CANDIDATE: layout imported; physical meaning not independently verified. PSA-RE bits 8.5. Validity of the left lane line as seen by the camera, for the LKA function Upstream default raw=0 (not necessarily valid data).";
CM_ SG_ 1067 RawBits56_57 "RAW. PSA-RE bits 8.7-8.6. Raw unmapped/padding bits; no physical interpretation.";
CM_ SG_ 1067 RawByte7 "RAW. PSA-RE bits 7.7-7.0. Raw unmapped/padding bits; no physical interpretation.";
CM_ SG_ 1067 LeftLineValidityDaa "DATABASE_CANDIDATE: layout imported; physical meaning not independently verified. PSA-RE bits 6.0. Validity of the left lane line as seen by the camera, for the DAA function Upstream default raw=0 (not necessarily valid data).";
CM_ SG_ 1067 LeftLineType "DATABASE_CANDIDATE: layout imported; physical meaning not independently verified. PSA-RE bits 6.3-6.1. Type of left lane line seen by the camera Upstream default raw=0 (not necessarily valid data).";
CM_ SG_ 1067 LeftLineHeadingAngle "DATABASE_CANDIDATE: layout imported; physical meaning not independently verified. PSA-RE bits 5.7-6.4. Vehicle heading angle relative to the left lane line Raw invalid=2047; numeric DBC decoders may still scale it: check raw before use. Upstream default raw=2046 (not necessarily valid data).";
CM_ SG_ 1067 LeftLineCurvatureDerivative "DATABASE_CANDIDATE: layout imported; physical meaning not independently verified. PSA-RE bits 3.7-4.0. Derivative of the road curvature, estimated from the left lane line Raw invalid=32767; numeric DBC decoders may still scale it: check raw before use. Upstream default raw=32766 (not necessarily valid data).";
CM_ SG_ 1067 LeftLineEstimatedCurvature "DATABASE_CANDIDATE: layout imported; physical meaning not independently verified. PSA-RE bits 1.7-2.0. Estimated curvature of the left lane line Raw invalid=32767; numeric DBC decoders may still scale it: check raw before use. Upstream default raw=32766 (not necessarily valid data).";
CM_ BO_ 1074 "Observed OBD 6/14 HS1. CAN ID 0x432; ID_DLC_match. PSA-RE name: BSI_CABIN_DATA_6. Body controller cabin data: hybrid blower setpoint, load-shedding requests for ABS/ESP, electric power steering, EasyMove and suspension, demisting request and hybrid zero-emission cabin inhibition. Source: https://github.com/prototux/PSA-RE/blob/67f7581e7622410efdbb29c7eda3b86982b9b450/buses/AEE2010.full/HS.HS1/432.yml. Database sender alternatives: BSI. ECU labels are database claims; forwarding/physical transmitter not independently identified. All fitting source fields retained, including default/unavailable-only candidates. See audit/source JSON for exclusions and unresolved alternatives.";
CM_ SG_ 1074 EngineStartIntentGeneral "DATABASE_CANDIDATE: layout imported; physical meaning not independently verified. PSA-RE bits 8.1-8.0. General engine start intent request Upstream default raw=2 (not necessarily valid data).";
CM_ SG_ 1074 EcoModeDriverRequest "DATABASE_CANDIDATE: layout imported; physical meaning not independently verified. PSA-RE bits 8.2. Eco mode requested by the driver Upstream default raw=0 (not necessarily valid data).";
CM_ SG_ 1074 HybridPowerLatchWakeup "DATABASE_CANDIDATE: layout imported; physical meaning not independently verified. PSA-RE bits 8.3. Hybrid system power latch wake-up Upstream default raw=0 (not necessarily valid data).";
CM_ SG_ 1074 ElectricalNetworkState "DATABASE_CANDIDATE: layout imported; physical meaning not independently verified. PSA-RE bits 8.7-8.4. Vehicle electrical network state (nominal, degraded, available for start, starting, restarting) Upstream default raw=0 (not necessarily valid data).";
CM_ SG_ 1074 MainStatus "DATABASE_CANDIDATE: layout imported; physical meaning not independently verified. PSA-RE bits 7.1-7.0. Vehicle electrical system main state Upstream default raw=0 (not necessarily valid data).";
CM_ SG_ 1074 FaultLogContext "DATABASE_CANDIDATE: layout imported; physical meaning not independently verified. PSA-RE bits 7.7-7.2. Fault log context information";
CM_ SG_ 1074 AddedFuelVolumeCounter "DATABASE_CANDIDATE: layout imported; physical meaning not independently verified. PSA-RE bits 6.2-6.0. Added fuel volume counter Upstream default raw=0 (not necessarily valid data).";
CM_ SG_ 1074 StartRequestStatus "DATABASE_CANDIDATE: layout imported; physical meaning not independently verified. PSA-RE bits 6.3. Start request status (main/secondary) Upstream default raw=0 (not necessarily valid data).";
CM_ SG_ 1074 Unused2 "DATABASE_CANDIDATE: layout imported; physical meaning not independently verified. PSA-RE bits 6.4. ";
CM_ SG_ 1074 UcapsPrechargeWakeup "DATABASE_CANDIDATE: layout imported; physical meaning not independently verified. PSA-RE bits 6.5. Ultracapacitor (UCAPS) precharge/discharge wake-up Upstream default raw=0 (not necessarily valid data).";
CM_ SG_ 1074 EnginePostVentilationWakeup "DATABASE_CANDIDATE: layout imported; physical meaning not independently verified. PSA-RE bits 6.6. Engine post-ventilation wake-up Upstream default raw=0 (not necessarily valid data).";
CM_ SG_ 1074 TcuHydraulicWakeupRequest "DATABASE_CANDIDATE: layout imported; physical meaning not independently verified. PSA-RE bits 6.7. TCU wake-up (RCD) request to restore hydraulic pressure Upstream default raw=0 (not necessarily valid data).";
CM_ SG_ 1074 TireHeightCorrectionWakeu_4ee41a "DATABASE_CANDIDATE: layout imported; physical meaning not independently verified. PSA-RE bits 5.0. Pneumatic (tire) height correction partial wake-up (RCD) request Upstream default raw=0 (not necessarily valid data).";
CM_ SG_ 1074 EbbBrakeAssistWakeup "DATABASE_CANDIDATE: layout imported; physical meaning not independently verified. PSA-RE bits 5.1. Partial wake-up between the BSI and EBB for brake assist needs Upstream default raw=0 (not necessarily valid data).";
CM_ SG_ 1074 DisplayNeedsWakeupRequest "DATABASE_CANDIDATE: layout imported; physical meaning not independently verified. PSA-RE bits 5.2. Wake-up request for display needs Upstream default raw=0 (not necessarily valid data).";
CM_ SG_ 1074 MecatronicHeadlampWakeupRequest "DATABASE_CANDIDATE: layout imported; physical meaning not independently verified. PSA-RE bits 5.3. Partial wake-up request to the BCPM for the mecatronic headlamp Upstream default raw=0 (not necessarily valid data).";
CM_ SG_ 1074 EngineOilMeasurementWakeup "DATABASE_CANDIDATE: layout imported; physical meaning not independently verified. PSA-RE bits 5.4. Wake-up to trigger engine oil information acquisition, requested by the BSI Upstream default raw=0 (not necessarily valid data).";
CM_ SG_ 1074 VehicleOverloadWakeup "DATABASE_CANDIDATE: layout imported; physical meaning not independently verified. PSA-RE bits 5.5. Partial wake-up related to vehicle overload Upstream default raw=0 (not necessarily valid data).";
CM_ SG_ 1074 EngineStartPreparationWakeup "DATABASE_CANDIDATE: layout imported; physical meaning not independently verified. PSA-RE bits 5.6. Engine start preparation wake-up (RCD) request (petrol engine) Upstream default raw=0 (not necessarily valid data).";
CM_ SG_ 1074 BrakeEcuSpeedWakeupRequest "DATABASE_CANDIDATE: layout imported; physical meaning not independently verified. PSA-RE bits 5.7. Partial wake-up (RCD) request of the brake ECU for vehicle speed transmission Upstream default raw=0 (not necessarily valid data).";
CM_ SG_ 1074 AddedFuelVolume "DATABASE_CANDIDATE: layout imported; physical meaning not independently verified. PSA-RE bits 4.7-4.0. Added fuel volume Raw invalid=255; numeric DBC decoders may still scale it: check raw before use. Upstream default raw=254 (not necessarily valid data).";
CM_ SG_ 1074 FseDisplayWakeupRequest "DATABASE_CANDIDATE: layout imported; physical meaning not independently verified. PSA-RE bits 3.0. Wake-up (RCD) request for electric parking brake (FSE) display needs Upstream default raw=0 (not necessarily valid data).";
CM_ SG_ 1074 ShortSharedPrePostWakeup "DATABASE_CANDIDATE: layout imported; physical meaning not independently verified. PSA-RE bits 3.1. Short shared partial wake-up before and/or after main mode Upstream default raw=0 (not necessarily valid data).";
CM_ SG_ 1074 ShortPostMainWakeup1 "DATABASE_CANDIDATE: layout imported; physical meaning not independently verified. PSA-RE bits 3.2. Short partial wake-up 1, after the main wake-up Upstream default raw=0 (not necessarily valid data).";
CM_ SG_ 1074 PriorityElectricalConsumer "DATABASE_CANDIDATE: layout imported; physical meaning not independently verified. PSA-RE bits 3.3. Priority electrical consumer request in the vehicle Upstream default raw=0 (not necessarily valid data).";
CM_ SG_ 1074 HadcEnableRequest "DATABASE_CANDIDATE: layout imported; physical meaning not independently verified. PSA-RE bits 3.4. HADC activation request Upstream default raw=0 (not necessarily valid data).";
CM_ SG_ 1074 EngineStartPreparationRequest "DATABASE_CANDIDATE: layout imported; physical meaning not independently verified. PSA-RE bits 3.5. Internal combustion engine start preparation request sent by the body computer to the engine ECU Upstream default raw=0 (not necessarily valid data).";
CM_ SG_ 1074 PulseStartRequest "DATABASE_CANDIDATE: layout imported; physical meaning not independently verified. PSA-RE bits 3.7-3.6. Pulse start request sent by the body computer to the engine ECU Upstream default raw=1 (not necessarily valid data).";
CM_ SG_ 1074 BsiCalculationProcessCounter "DATABASE_CANDIDATE: layout imported; physical meaning not independently verified. PSA-RE bits 2.3-2.0. Free-running counter (0 to 15) confirming a new BSI calculation cycle Upstream default raw=0 (not necessarily valid data).";
CM_ SG_ 1074 ElectricalSystemStartIntent "DATABASE_CANDIDATE: layout imported; physical meaning not independently verified. PSA-RE bits 2.5-2.4. Engine start intent from the electrical system (SEV) Upstream default raw=1 (not necessarily valid data).";
CM_ SG_ 1074 Unused1 "DATABASE_CANDIDATE: layout imported; physical meaning not independently verified. PSA-RE bits 2.7-2.6. ";
CM_ SG_ 1074 EngineStopRequest "DATABASE_CANDIDATE: layout imported; physical meaning not independently verified. PSA-RE bits 1.1-1.0. Internal combustion engine stop request sent by the body computer to the engine ECU Upstream default raw=1 (not necessarily valid data).";
CM_ SG_ 1074 StarterStopRequest "DATABASE_CANDIDATE: layout imported; physical meaning not independently verified. PSA-RE bits 1.2. Starter stop request sent by the body computer to the engine ECU Upstream default raw=0 (not necessarily valid data).";
CM_ SG_ 1074 HeightCorrectionWakeupRequest "DATABASE_CANDIDATE: layout imported; physical meaning not independently verified. PSA-RE bits 1.3. Vehicle base height correction wake-up (RCD) request Upstream default raw=0 (not necessarily valid data).";
CM_ SG_ 1074 AntiTheftWakeupRequest "DATABASE_CANDIDATE: layout imported; physical meaning not independently verified. PSA-RE bits 1.4. Anti-theft anticipation wake-up (RCD) request Upstream default raw=0 (not necessarily valid data).";
CM_ SG_ 1074 GearboxStateWakeupRequest "DATABASE_CANDIDATE: layout imported; physical meaning not independently verified. PSA-RE bits 1.5. Gearbox wake-up (RCD) request for gearbox status transmission Upstream default raw=0 (not necessarily valid data).";
CM_ SG_ 1074 MainWakeupStatus "DATABASE_CANDIDATE: layout imported; physical meaning not independently verified. PSA-RE bits 1.7-1.6. Main network wake-up request (RCD) Upstream default raw=0 (not necessarily valid data).";
CM_ BO_ 1086 "Observed OBD 6/14 HS1. CAN ID 0x43E; ID_DLC_match. PSA-RE name: CAMERA_LANE_TRACKING_DATA_2. Camera lane-tracking data: lead-vehicle lane-crossing flags, cluster angle/distance left and right, minimum cluster distance/angle and perception status. Source: https://github.com/prototux/PSA-RE/blob/67f7581e7622410efdbb29c7eda3b86982b9b450/buses/AEE2010.full/HS.HS1/43E.yml. Database sender alternatives: CVM. ECU labels are database claims; forwarding/physical transmitter not independently identified. All fitting source fields retained, including default/unavailable-only candidates. See audit/source JSON for exclusions and unresolved alternatives.";
CM_ SG_ 1086 RoadProfileRightPoint3 "DATABASE_CANDIDATE: layout imported; physical meaning not independently verified. PSA-RE bits 6.7-6.0. Point 3 of the right-side road profile (m) Raw invalid=255; numeric DBC decoders may still scale it: check raw before use. Upstream default raw=254 (not necessarily valid data).";
CM_ SG_ 1086 RoadProfileLeftPoint3 "DATABASE_CANDIDATE: layout imported; physical meaning not independently verified. PSA-RE bits 5.7-5.0. Point 3 of the left-side road profile (m) Raw invalid=255; numeric DBC decoders may still scale it: check raw before use. Upstream default raw=254 (not necessarily valid data).";
CM_ SG_ 1086 RoadProfileRightPoint2 "DATABASE_CANDIDATE: layout imported; physical meaning not independently verified. PSA-RE bits 4.7-4.0. Point 2 of the right-side road profile (m) Raw invalid=255; numeric DBC decoders may still scale it: check raw before use. Upstream default raw=254 (not necessarily valid data).";
CM_ SG_ 1086 RoadProfileLeftPoint2 "DATABASE_CANDIDATE: layout imported; physical meaning not independently verified. PSA-RE bits 3.7-3.0. Point 2 of the left-side road profile (m) Raw invalid=255; numeric DBC decoders may still scale it: check raw before use. Upstream default raw=254 (not necessarily valid data).";
CM_ SG_ 1086 RoadProfileRightPoint1 "DATABASE_CANDIDATE: layout imported; physical meaning not independently verified. PSA-RE bits 2.7-2.0. Point 1 of the right-side road profile (m) Raw invalid=255; numeric DBC decoders may still scale it: check raw before use. Upstream default raw=254 (not necessarily valid data).";
CM_ SG_ 1086 RoadProfileLeftPoint1 "DATABASE_CANDIDATE: layout imported; physical meaning not independently verified. PSA-RE bits 1.7-1.0. Point 1 of the left-side road profile (m) Raw invalid=255; numeric DBC decoders may still scale it: check raw before use. Upstream default raw=254 (not necessarily valid data).";
CM_ BO_ 1099 "Observed OBD 6/14 HS1. CAN ID 0x44B; DLC_unspecified. PSA-RE name: RIGHT_LANE_LINE_INFO. Right lane line detection data from the front camera: curvature, distance to line, heading angle, line type and detection status for lane keeping and departure warning. Source: https://github.com/prototux/PSA-RE/blob/67f7581e7622410efdbb29c7eda3b86982b9b450/buses/AEE2010.full/HS.HS1/44B.yml. Database sender alternatives: CVM. ECU labels are database claims; forwarding/physical transmitter not independently identified. All fitting source fields retained, including default/unavailable-only candidates. See audit/source JSON for exclusions and unresolved alternatives.";
CM_ SG_ 1099 Unused1 "DATABASE_CANDIDATE: layout imported; physical meaning not independently verified. PSA-RE bits 8.4-8.0. ";
CM_ SG_ 1099 RightLineValidityLka "DATABASE_CANDIDATE: layout imported; physical meaning not independently verified. PSA-RE bits 8.5. Validity of the right lane line as seen by the camera, for the LKA function Upstream default raw=0 (not necessarily valid data).";
CM_ SG_ 1099 DistanceToRightLine "DATABASE_CANDIDATE: layout imported; physical meaning not independently verified. PSA-RE bits 7.7-8.6. Distance from the vehicle centre to the right lane line Raw invalid=511; numeric DBC decoders may still scale it: check raw before use. Upstream default raw=510 (not necessarily valid data).";
CM_ SG_ 1099 RightLineValidityDaa "DATABASE_CANDIDATE: layout imported; physical meaning not independently verified. PSA-RE bits 6.0. Validity of the right lane line as seen by the camera, for the DAA function Upstream default raw=0 (not necessarily valid data).";
CM_ SG_ 1099 RightLineType "DATABASE_CANDIDATE: layout imported; physical meaning not independently verified. PSA-RE bits 6.3-6.1. Type of right lane line seen by the camera Upstream default raw=0 (not necessarily valid data).";
CM_ SG_ 1099 RightLineHeadingAngle "DATABASE_CANDIDATE: layout imported; physical meaning not independently verified. PSA-RE bits 5.7-6.4. Vehicle heading angle relative to the right lane line Raw invalid=2047; numeric DBC decoders may still scale it: check raw before use. Upstream default raw=2046 (not necessarily valid data).";
CM_ SG_ 1099 RightLineCurvatureDerivative "DATABASE_CANDIDATE: layout imported; physical meaning not independently verified. PSA-RE bits 3.7-4.0. Derivative of the road curvature, estimated from the right lane line Raw invalid=32767; numeric DBC decoders may still scale it: check raw before use. Upstream default raw=32766 (not necessarily valid data).";
CM_ SG_ 1099 RightLineEstimatedCurvature "DATABASE_CANDIDATE: layout imported; physical meaning not independently verified. PSA-RE bits 1.7-2.0. Estimated curvature of the right lane line Raw invalid=32767; numeric DBC decoders may still scale it: check raw before use. Upstream default raw=32766 (not necessarily valid data).";
CM_ BO_ 1101 "Observed OBD 6/14 HS1. CAN ID 0x44D; ID_DLC_match. PSA-RE name: WHEEL_SPEEDS_ABS. Wheel speeds, sent by the ABS unit. Source: https://github.com/prototux/PSA-RE/blob/67f7581e7622410efdbb29c7eda3b86982b9b450/buses/AEE2010.full/HS.HS1/44D.yml. Database sender alternatives: ABS. ECU labels are database claims; forwarding/physical transmitter not independently identified. All fitting source fields retained, including default/unavailable-only candidates. See audit/source JSON for exclusions and unresolved alternatives.";
CM_ SG_ 1101 FrontAverageWheelRpm "OWNER_CONFIRMED in READY capture: speed/SOC agree with vehicle; startup values need validity gating. PSA-RE bits 7.7-8.0. Front wheels average rotational speed Raw invalid=65535; numeric DBC decoders may still scale it: check raw before use. Upstream default raw=65535 (not necessarily valid data).";
CM_ SG_ 1101 WheelSpeedRR "OWNER_CONFIRMED in READY capture: speed/SOC agree with vehicle; startup values need validity gating. PSA-RE bits 5.7-6.0. Rear right wheel speed. Raw invalid=65535; numeric DBC decoders may still scale it: check raw before use. Upstream default raw=65535 (not necessarily valid data).";
CM_ SG_ 1101 WheelSpeedRL "OWNER_CONFIRMED in READY capture: speed/SOC agree with vehicle; startup values need validity gating. PSA-RE bits 3.7-4.0. Rear left wheel speed. Raw invalid=65535; numeric DBC decoders may still scale it: check raw before use. Upstream default raw=65535 (not necessarily valid data).";
CM_ SG_ 1101 FrontAverageSpeed "OWNER_CONFIRMED in READY capture: speed/SOC agree with vehicle; startup values need validity gating. PSA-RE bits 1.7-2.0. Vehicle speed averaged from the front wheels Raw invalid=65535; numeric DBC decoders may still scale it: check raw before use. Upstream default raw=65535 (not necessarily valid data).";
CM_ BO_ 1102 "Observed OBD 6/14 HS1. CAN ID 0x44E; ID_DLC_match. PSA-RE name: BSI_CABIN_DATA_7. Body controller cabin data: hybrid blower setpoint, load-shedding requests for ABS/ESP, electric power steering, EasyMove and suspension, demisting request and hybrid zero-emission cabin inhibition. Source: https://github.com/prototux/PSA-RE/blob/67f7581e7622410efdbb29c7eda3b86982b9b450/buses/AEE2010.full/HS.HS1/44E.yml. Database sender alternatives: BSI. ECU labels are database claims; forwarding/physical transmitter not independently identified. All fitting source fields retained, including default/unavailable-only candidates. See audit/source JSON for exclusions and unresolved alternatives.";
CM_ SG_ 1102 RearHeaterCoreInletWaterSetpoint "DATABASE_CANDIDATE: layout imported; physical meaning not independently verified. PSA-RE bits 3.7-3.0. Rear heater core inlet water temperature setpoint Raw invalid=255; numeric DBC decoders may still scale it: check raw before use.";
CM_ SG_ 1102 EvaporatorAdditionalSenso_064c17 "DATABASE_CANDIDATE: layout imported; physical meaning not independently verified. PSA-RE bits 2.4-2.0. Air temperature measured at the evaporator outlet by the additional sensor Raw invalid=31; numeric DBC decoders may still scale it: check raw before use.";
CM_ SG_ 1102 RearEvaporatorSensorTempe_68d237 "DATABASE_CANDIDATE: layout imported; physical meaning not independently verified. PSA-RE bits 1.7-2.5. Rear evaporator outlet air temperature setpoint Raw invalid=2047; numeric DBC decoders may still scale it: check raw before use.";
CM_ BO_ 1108 "Observed OBD 6/14 HS1. CAN ID 0x454; ID_DLC_match. PSA-RE name: HV_BATTERY_MANAGEMENT_DATA_3. HV battery management data: engine auto-stop authorisation, warning-lamp reset command and request, climate-control inhibition, engine action request, and battery state of charge/state of health. Source: https://github.com/prototux/PSA-RE/blob/67f7581e7622410efdbb29c7eda3b86982b9b450/buses/AEE2010.electric/HS.HS1/454.yml. Database sender alternatives: VCU,E_VCU. ECU labels are database claims; forwarding/physical transmitter not independently identified. All fitting source fields retained, including default/unavailable-only candidates. See audit/source JSON for exclusions and unresolved alternatives.";
CM_ SG_ 1108 Unused1 "DATABASE_CANDIDATE: layout imported; physical meaning not independently verified. PSA-RE bits 8.4-8.0. ";
CM_ SG_ 1108 HvBatteryTotalPositiveCurrentAh "DATABASE_CANDIDATE: layout imported; physical meaning not independently verified. PSA-RE bits 6.0-8.5. Total positive (charge) current quantity of the HV battery Raw invalid=4095; numeric DBC decoders may still scale it: check raw before use.";
CM_ SG_ 1108 TimeHvBattOverTemperature "DATABASE_CANDIDATE: layout imported; physical meaning not independently verified. PSA-RE bits 5.5-6.1. Cumulative time the HV battery has spent above the maximum allowed temperature Raw invalid=8191; numeric DBC decoders may still scale it: check raw before use.";
CM_ SG_ 1108 BatterySohResistance "DATABASE_CANDIDATE: layout imported; physical meaning not independently verified. PSA-RE bits 4.4-5.6. HV battery state of health, resistance-based Raw invalid=127; numeric DBC decoders may still scale it: check raw before use.";
CM_ SG_ 1108 BatterySohCapacity "DATABASE_CANDIDATE: layout imported; physical meaning not independently verified. PSA-RE bits 3.3-4.5. HV battery state of health, capacity-based Raw invalid=127; numeric DBC decoders may still scale it: check raw before use.";
CM_ SG_ 1108 DcChargeRelayActuationCounter "DATABASE_CANDIDATE: layout imported; physical meaning not independently verified. PSA-RE bits 2.5-3.4. Number of times the DC charging relay has been actuated Raw invalid=1023; numeric DBC decoders may still scale it: check raw before use.";
CM_ SG_ 1108 MainRelayActuationCounter "DATABASE_CANDIDATE: layout imported; physical meaning not independently verified. PSA-RE bits 1.7-2.6. Number of times the main HV contactor relay has been actuated Raw invalid=1023; numeric DBC decoders may still scale it: check raw before use.";
CM_ BO_ 1118 "Observed OBD 6/14 HS1. CAN ID 0x45E; ID_DLC_match. PSA-RE name: CAMERA_LANE_TRACKING_DATA_3. Camera lane-tracking data: lead-vehicle lane-crossing flags, cluster angle/distance left and right, minimum cluster distance/angle and perception status. Source: https://github.com/prototux/PSA-RE/blob/67f7581e7622410efdbb29c7eda3b86982b9b450/buses/AEE2010.full/HS.HS1/45E.yml. Database sender alternatives: CVM. ECU labels are database claims; forwarding/physical transmitter not independently identified. All fitting source fields retained, including default/unavailable-only candidates. See audit/source JSON for exclusions and unresolved alternatives.";
CM_ SG_ 1118 RoadProfileRightPoint6 "DATABASE_CANDIDATE: layout imported; physical meaning not independently verified. PSA-RE bits 6.7-6.0. Point 6 of the right-side road profile (m) Raw invalid=255; numeric DBC decoders may still scale it: check raw before use. Upstream default raw=254 (not necessarily valid data).";
CM_ SG_ 1118 RoadProfileLeftPoint6 "DATABASE_CANDIDATE: layout imported; physical meaning not independently verified. PSA-RE bits 5.7-5.0. Point 6 of the left-side road profile (m) Raw invalid=255; numeric DBC decoders may still scale it: check raw before use. Upstream default raw=254 (not necessarily valid data).";
CM_ SG_ 1118 RoadProfileRightPoint5 "DATABASE_CANDIDATE: layout imported; physical meaning not independently verified. PSA-RE bits 4.7-4.0. Point 5 of the right-side road profile (m) Raw invalid=255; numeric DBC decoders may still scale it: check raw before use. Upstream default raw=254 (not necessarily valid data).";
CM_ SG_ 1118 RoadProfileLeftPoint5 "DATABASE_CANDIDATE: layout imported; physical meaning not independently verified. PSA-RE bits 3.7-3.0. Point 5 of the left-side road profile (m) Raw invalid=255; numeric DBC decoders may still scale it: check raw before use. Upstream default raw=254 (not necessarily valid data).";
CM_ SG_ 1118 RoadProfileRightPoint4 "DATABASE_CANDIDATE: layout imported; physical meaning not independently verified. PSA-RE bits 2.7-2.0. Point 4 of the right-side road profile (m) Raw invalid=255; numeric DBC decoders may still scale it: check raw before use. Upstream default raw=254 (not necessarily valid data).";
CM_ SG_ 1118 RoadProfileLeftPoint4 "DATABASE_CANDIDATE: layout imported; physical meaning not independently verified. PSA-RE bits 1.7-1.0. Point 4 of the left-side road profile (m) Raw invalid=255; numeric DBC decoders may still scale it: check raw before use. Upstream default raw=254 (not necessarily valid data).";
CM_ BO_ 1122 "Observed OBD 6/14 HS1. CAN ID 0x462; ID_DLC_match. PSA-RE name: EV_CHARGE_STATUS. Electric vehicle charge status: charging station stop-charge request and charge-in-progress mode. Source: https://github.com/prototux/PSA-RE/blob/67f7581e7622410efdbb29c7eda3b86982b9b450/buses/AEE2010.electric/HS.HS1/462.yml. Database sender alternatives: E_VCU. ECU labels are database claims; forwarding/physical transmitter not independently identified. All fitting source fields retained, including default/unavailable-only candidates. See audit/source JSON for exclusions and unresolved alternatives.";
CM_ SG_ 1122 RawByte4 "RAW. PSA-RE bits 4.7-4.0. Raw unmapped/padding bits; no physical interpretation.";
CM_ SG_ 1122 RawByte3 "RAW. PSA-RE bits 3.7-3.0. Raw unmapped/padding bits; no physical interpretation.";
CM_ SG_ 1122 RawByte2 "RAW. PSA-RE bits 2.7-2.0. Raw unmapped/padding bits; no physical interpretation.";
CM_ SG_ 1122 RawBits4_7 "RAW. PSA-RE bits 1.3-1.0. Raw unmapped/padding bits; no physical interpretation.";
CM_ SG_ 1122 FastChargeStopRequest "DATABASE_CANDIDATE: layout imported; physical meaning not independently verified. PSA-RE bits 1.4. Request to stop fast charging (DC charging station, EVSE)";
CM_ SG_ 1122 ChargeModeInProgress "DATABASE_CANDIDATE: layout imported; physical meaning not independently verified. PSA-RE bits 1.7-1.5. Current battery charging mode (slow AC, fast DC, no charging)";
CM_ BO_ 1128 "Observed OBD 6/14 HS1. CAN ID 0x468; ID_DLC_match. PSA-RE name: ENGINE_DYNAMIC_DATA_3. Engine dynamic data 3, sent on turbo-transition or rear-preparation change: alternator regulation voltage setpoint, secondary brake-contact incoherence, engine and production faults, ignition state, damper and starter state, generator output level, starter protection. Source: https://github.com/prototux/PSA-RE/blob/67f7581e7622410efdbb29c7eda3b86982b9b450/buses/AEE2010.full/HS.HS1/468.yml. Database sender alternatives: E_VCU,CMM. ECU labels are database claims; forwarding/physical transmitter not independently identified. All fitting source fields retained, including default/unavailable-only candidates. See audit/source JSON for exclusions and unresolved alternatives.";
CM_ SG_ 1128 ElectricalConsumerClass1Cut "DATABASE_CANDIDATE: layout imported; physical meaning not independently verified. PSA-RE bits 8.0. Class 1 electrical consumers not powered (load shedding) Upstream default raw=0 (not necessarily valid data).";
CM_ SG_ 1128 ElectricalConsumerClass2Cut "DATABASE_CANDIDATE: layout imported; physical meaning not independently verified. PSA-RE bits 8.1. Class 2 electrical consumers not powered (load shedding) Upstream default raw=0 (not necessarily valid data).";
CM_ SG_ 1128 ElectricalConsumerClass3Cut "DATABASE_CANDIDATE: layout imported; physical meaning not independently verified. PSA-RE bits 8.2. Class 3 electrical consumers not powered (load shedding) Upstream default raw=0 (not necessarily valid data).";
CM_ SG_ 1128 ElectricalConsumerClass4Cut "DATABASE_CANDIDATE: layout imported; physical meaning not independently verified. PSA-RE bits 8.3. Class 4 electrical consumers not powered (load shedding) Upstream default raw=0 (not necessarily valid data).";
CM_ SG_ 1128 ElectricalConsumerClass5Cut "DATABASE_CANDIDATE: layout imported; physical meaning not independently verified. PSA-RE bits 8.4. Class 5 electrical consumers not powered (load shedding) Upstream default raw=0 (not necessarily valid data).";
CM_ SG_ 1128 ElectricalConsumerClass6Cut "DATABASE_CANDIDATE: layout imported; physical meaning not independently verified. PSA-RE bits 8.5. Class 6 electrical consumers not powered (load shedding) Upstream default raw=0 (not necessarily valid data).";
CM_ SG_ 1128 ElectricalConsumerClass7Cut "DATABASE_CANDIDATE: layout imported; physical meaning not independently verified. PSA-RE bits 8.6. Class 7 electrical consumers not powered (load shedding) Upstream default raw=0 (not necessarily valid data).";
CM_ SG_ 1128 ElectricalConsumerClass8Cut "DATABASE_CANDIDATE: layout imported; physical meaning not independently verified. PSA-RE bits 8.7. Class 8 electrical consumers not powered (load shedding) Upstream default raw=0 (not necessarily valid data).";
CM_ SG_ 1128 ElectricalConsumerClass9Cut "DATABASE_CANDIDATE: layout imported; physical meaning not independently verified. PSA-RE bits 7.0. Class 9 electrical consumers not powered (load shedding) Upstream default raw=0 (not necessarily valid data).";
CM_ SG_ 1128 EngineStopImminent "DATABASE_CANDIDATE: layout imported; physical meaning not independently verified. PSA-RE bits 7.1. Engine stop imminent Upstream default raw=0 (not necessarily valid data).";
CM_ SG_ 1128 LoadSheddingRequest "DATABASE_CANDIDATE: layout imported; physical meaning not independently verified. PSA-RE bits 7.2. Load shedding request Upstream default raw=0 (not necessarily valid data).";
CM_ SG_ 1128 VacuumSupplyFaultLampRequest "DATABASE_CANDIDATE: layout imported; physical meaning not independently verified. PSA-RE bits 7.3. Vacuum supply fault warning lamp request Upstream default raw=0 (not necessarily valid data).";
CM_ SG_ 1128 GeneratorLoadRequest "DATABASE_CANDIDATE: layout imported; physical meaning not independently verified. PSA-RE bits 7.5-7.4. Load request sent to the electrical power generator Upstream default raw=0 (not necessarily valid data).";
CM_ SG_ 1128 AutomaticGearboxLockupRequest "DATABASE_CANDIDATE: layout imported; physical meaning not independently verified. PSA-RE bits 7.6. Automatic gearbox torque converter lock-up request Upstream default raw=0 (not necessarily valid data).";
CM_ SG_ 1128 SafetyLoadSheddingLevel1 "DATABASE_CANDIDATE: layout imported; physical meaning not independently verified. PSA-RE bits 7.7. Level 1 safety load shedding, issued by the engine ECU Upstream default raw=0 (not necessarily valid data).";
CM_ SG_ 1128 ElectricalSupplyStatus12v "DATABASE_CANDIDATE: layout imported; physical meaning not independently verified. PSA-RE bits 6.3-6.0. 12V electrical power supply status, provided by the powertrain Upstream default raw=1 (not necessarily valid data).";
CM_ SG_ 1128 StubbedSignal1 "DATABASE_CANDIDATE: layout imported; physical meaning not independently verified. PSA-RE bits 6.4. Removed signal, stubbed to a fixed value Upstream default raw=0 (not necessarily valid data).";
CM_ SG_ 1128 RawBits41_42 "RAW. PSA-RE bits 6.6-6.5. Raw unmapped/padding bits; no physical interpretation.";
CM_ SG_ 1128 CreepAuthorization "DATABASE_CANDIDATE: layout imported; physical meaning not independently verified. PSA-RE bits 6.7. Creep (idle crawl) authorization";
CM_ SG_ 1128 RelayR3ControlRequest "DATABASE_CANDIDATE: layout imported; physical meaning not independently verified. PSA-RE bits 5.0. Request to energize relay R3 Upstream default raw=0 (not necessarily valid data).";
CM_ SG_ 1128 RelayR2ControlRequest "DATABASE_CANDIDATE: layout imported; physical meaning not independently verified. PSA-RE bits 5.1. Request to energize relay R2 Upstream default raw=0 (not necessarily valid data).";
CM_ SG_ 1128 RelayR1ControlRequest "DATABASE_CANDIDATE: layout imported; physical meaning not independently verified. PSA-RE bits 5.2. Request to energize relay R1 Upstream default raw=0 (not necessarily valid data).";
CM_ SG_ 1128 GeneratorProductionFault "DATABASE_CANDIDATE: layout imported; physical meaning not independently verified. PSA-RE bits 5.3. Generator production fault Upstream default raw=0 (not necessarily valid data).";
CM_ SG_ 1128 DcdcLvVoltageSetpoint "DATABASE_CANDIDATE: layout imported; physical meaning not independently verified. PSA-RE bits 4.1-5.4. DC/DC converter low-voltage side voltage setpoint Raw invalid=63; numeric DBC decoders may still scale it: check raw before use. Upstream default raw=0 (not necessarily valid data). Unresolved source alternatives: [{\"factor\": 0.11, \"note\": \"Also observed with another scaling (factor 0.11)\"}]";
CM_ SG_ 1128 GeneratorProductionLevel "DATABASE_CANDIDATE: layout imported; physical meaning not independently verified. PSA-RE bits 4.4-4.2. Generator production level Upstream default raw=6 (not necessarily valid data).";
CM_ SG_ 1128 GeneratorProductionStatus "DATABASE_CANDIDATE: layout imported; physical meaning not independently verified. PSA-RE bits 4.7-4.5. Generator production status (on/off) Upstream default raw=6 (not necessarily valid data).";
CM_ SG_ 1128 StarterInhibitDriverUnavailable "DATABASE_CANDIDATE: layout imported; physical meaning not independently verified. PSA-RE bits 3.0. Starter motor inhibition, driver unavailable Upstream default raw=1 (not necessarily valid data).";
CM_ SG_ 1128 BoostPressure "DATABASE_CANDIDATE: layout imported; physical meaning not independently verified. PSA-RE bits 3.5-3.1. Turbocharger boost pressure Raw invalid=31; numeric DBC decoders may still scale it: check raw before use. Upstream default raw=0 (not necessarily valid data).";
CM_ SG_ 1128 ElectricalConsumerActivat_f46ef1 "DATABASE_CANDIDATE: layout imported; physical meaning not independently verified. PSA-RE bits 3.7-3.6. Electrical consumer activation request, for the energy management system Upstream default raw=1 (not necessarily valid data).";
CM_ SG_ 1128 TractionChainStatus "DATABASE_CANDIDATE: layout imported; physical meaning not independently verified. PSA-RE bits 2.1-2.0. Traction chain status (open/closed) Upstream default raw=0 (not necessarily valid data).";
CM_ SG_ 1128 StartAuthorizationStatus "DATABASE_CANDIDATE: layout imported; physical meaning not independently verified. PSA-RE bits 2.3-2.2. Engine start authorization status Upstream default raw=0 (not necessarily valid data).";
CM_ SG_ 1128 CmmFault "DATABASE_CANDIDATE: layout imported; physical meaning not independently verified. PSA-RE bits 2.5-2.4. CMM fault status Upstream default raw=3 (not necessarily valid data).";
CM_ SG_ 1128 TurboTransitionInProgress "DATABASE_CANDIDATE: layout imported; physical meaning not independently verified. PSA-RE bits 2.7-2.6. Turbo transition in progress (single-turbo to twin-turbo mode or vice versa)";
CM_ SG_ 1128 Unused1 "DATABASE_CANDIDATE: layout imported; physical meaning not independently verified. PSA-RE bits 1.2-1.0. ";
CM_ SG_ 1128 DampFunctionStatus "DATABASE_CANDIDATE: layout imported; physical meaning not independently verified. PSA-RE bits 1.4-1.3. Controlled engine start/stop (DAMP) function status Upstream default raw=0 (not necessarily valid data).";
CM_ SG_ 1128 StarterProtectionStatus "DATABASE_CANDIDATE: layout imported; physical meaning not independently verified. PSA-RE bits 1.5. The engine ECU cannot execute the start request because the engine is already running Upstream default raw=0 (not necessarily valid data).";
CM_ SG_ 1128 BrakePedalSecondarySwitch_db3725 "DATABASE_CANDIDATE: layout imported; physical meaning not independently verified. PSA-RE bits 1.6. Brake pedal secondary switch signal uncertain Upstream default raw=0 (not necessarily valid data).";
CM_ SG_ 1128 StarterCommandFeedback "DATABASE_CANDIDATE: layout imported; physical meaning not independently verified. PSA-RE bits 1.7. Starter command feedback Upstream default raw=0 (not necessarily valid data).";
CM_ BO_ 1134 "Observed OBD 6/14 HS1. CAN ID 0x46E; ID_DLC_match. PSA-RE name: BSI_CABIN_DATA_8. Body controller cabin data: hybrid blower setpoint, load-shedding requests for ABS/ESP, electric power steering, EasyMove and suspension, demisting request and hybrid zero-emission cabin inhibition. Source: https://github.com/prototux/PSA-RE/blob/67f7581e7622410efdbb29c7eda3b86982b9b450/buses/AEE2010.full/HS.HS1/46E.yml. Database sender alternatives: BSI. ECU labels are database claims; forwarding/physical transmitter not independently identified. All fitting source fields retained, including default/unavailable-only candidates. See audit/source JSON for exclusions and unresolved alternatives.";
CM_ SG_ 1134 RawBits9_15 "RAW. PSA-RE bits 2.6-2.0. Raw unmapped/padding bits; no physical interpretation.";
CM_ SG_ 1134 FuelGaugeResistance "DATABASE_CANDIDATE: layout imported; physical meaning not independently verified. PSA-RE bits 1.7-2.7. Ohmic resistance corresponding to the fuel level in the tank Raw invalid=511; numeric DBC decoders may still scale it: check raw before use.";
CM_ BO_ 1150 "Observed OBD 6/14 HS1. CAN ID 0x47E; ID_DLC_match. PSA-RE name: CAMERA_LANE_TRACKING_DATA_4. Camera lane-tracking data: lead-vehicle lane-crossing flags, cluster angle/distance left and right, minimum cluster distance/angle and perception status. Source: https://github.com/prototux/PSA-RE/blob/67f7581e7622410efdbb29c7eda3b86982b9b450/buses/AEE2010.full/HS.HS1/47E.yml. Database sender alternatives: CVM. ECU labels are database claims; forwarding/physical transmitter not independently identified. All fitting source fields retained, including default/unavailable-only candidates. See audit/source JSON for exclusions and unresolved alternatives.";
CM_ SG_ 1150 RightShockGeometry "DATABASE_CANDIDATE: layout imported; physical meaning not independently verified. PSA-RE bits 8.3-8.0. Type of shock geometry detected on the right side Raw invalid=15; numeric DBC decoders may still scale it: check raw before use. Upstream default raw=0 (not necessarily valid data).";
CM_ SG_ 1150 LeftShockGeometry "DATABASE_CANDIDATE: layout imported; physical meaning not independently verified. PSA-RE bits 8.7-8.4. Type of shock geometry detected on the left side Raw invalid=15; numeric DBC decoders may still scale it: check raw before use. Upstream default raw=0 (not necessarily valid data).";
CM_ SG_ 1150 RightShockDistance "DATABASE_CANDIDATE: layout imported; physical meaning not independently verified. PSA-RE bits 7.7-7.0. Distance between the detected right-side shock geometry and the vehicle (m) Raw invalid=255; numeric DBC decoders may still scale it: check raw before use. Upstream default raw=234 (not necessarily valid data).";
CM_ SG_ 1150 LeftShockDistance "DATABASE_CANDIDATE: layout imported; physical meaning not independently verified. PSA-RE bits 6.7-6.0. Distance between the detected left-side shock geometry and the vehicle (m) Raw invalid=255; numeric DBC decoders may still scale it: check raw before use. Upstream default raw=234 (not necessarily valid data).";
CM_ SG_ 1150 NextRoadObstacleDistance "DATABASE_CANDIDATE: layout imported; physical meaning not independently verified. PSA-RE bits 5.7-5.0. Distance between the next detected road obstacle and the vehicle (m) Raw invalid=255; numeric DBC decoders may still scale it: check raw before use. Upstream default raw=234 (not necessarily valid data).";
CM_ SG_ 1150 Unused1 "DATABASE_CANDIDATE: layout imported; physical meaning not independently verified. PSA-RE bits 4.2-4.0. ";
CM_ SG_ 1150 RoadSurfaceCondition "DATABASE_CANDIDATE: layout imported; physical meaning not independently verified. PSA-RE bits 4.7-4.3. Road surface condition Raw invalid=31; numeric DBC decoders may still scale it: check raw before use. Upstream default raw=30 (not necessarily valid data).";
CM_ SG_ 1150 RoadObstacleType "DATABASE_CANDIDATE: layout imported; physical meaning not independently verified. PSA-RE bits 3.7-3.0. Type of road obstacle detected (speed reducer, speed bump, oscillation...) Upstream default raw=254 (not necessarily valid data).";
CM_ SG_ 1150 RoadProfileRightPoint7 "DATABASE_CANDIDATE: layout imported; physical meaning not independently verified. PSA-RE bits 2.7-2.0. Point 7 of the right-side road profile (m) Raw invalid=255; numeric DBC decoders may still scale it: check raw before use. Upstream default raw=254 (not necessarily valid data).";
CM_ SG_ 1150 RoadProfileLeftPoint7 "DATABASE_CANDIDATE: layout imported; physical meaning not independently verified. PSA-RE bits 1.7-1.0. Point 7 of the left-side road profile (m) Raw invalid=255; numeric DBC decoders may still scale it: check raw before use. Upstream default raw=254 (not necessarily valid data).";
CM_ BO_ 1161 "Observed OBD 6/14 HS1. CAN ID 0x489; ID_DLC_match. PSA-RE name: GEARBOX_DATA_V2. Gearbox data, version 2: gear-change refused, fault state, start inhibition, sport mode, lever position display, driving program, engaged mechanical gear, target gear and driver-requested gear display. Source: https://github.com/prototux/PSA-RE/blob/67f7581e7622410efdbb29c7eda3b86982b9b450/buses/AEE2010.full/HS.HS1/489.yml. Database sender alternatives: E_VCU,BVA. ECU labels are database claims; forwarding/physical transmitter not independently identified. All fitting source fields retained, including default/unavailable-only candidates. See audit/source JSON for exclusions and unresolved alternatives.";
CM_ SG_ 1161 DriverTargetGearDisplay "DATABASE_CANDIDATE: layout imported; physical meaning not independently verified. PSA-RE bits 8.3-8.0. Driver target gear position requested for display Upstream default raw=15 (not necessarily valid data).";
CM_ SG_ 1161 GearboxDynamicModeAvailability "DATABASE_CANDIDATE: layout imported; physical meaning not independently verified. PSA-RE bits 8.5-8.4. Gearbox sport/eco mode availability Upstream default raw=3 (not necessarily valid data).";
CM_ SG_ 1161 GearboxLongInitInProgress "DATABASE_CANDIDATE: layout imported; physical meaning not independently verified. PSA-RE bits 8.6. Long gearbox initialization in progress Upstream default raw=0 (not necessarily valid data).";
CM_ SG_ 1161 GearboxRedWarningLampRequest "DATABASE_CANDIDATE: layout imported; physical meaning not independently verified. PSA-RE bits 8.7. Request to light the red warning lamp from the gearbox Upstream default raw=0 (not necessarily valid data).";
CM_ SG_ 1161 PowertrainSportinessIndexState "DATABASE_CANDIDATE: layout imported; physical meaning not independently verified. PSA-RE bits 7.7-7.0. Powertrain sportiness index (state: economic, comfort, dynamic, sport, hypershift) Upstream default raw=10 (not necessarily valid data).";
CM_ SG_ 1161 TorqueConversionRatioExtended "DATABASE_CANDIDATE: layout imported; physical meaning not independently verified. PSA-RE bits 5.3-6.0. Torque conversion ratio, extended-resolution value (output torque / input torque of the gearbox) Raw invalid=4095; numeric DBC decoders may still scale it: check raw before use. Upstream default raw=1 (not necessarily valid data). Unresolved source alternatives: [{\"factor\": 0.011, \"note\": \"Also observed with another scaling (factor 0.011)\"}]";
CM_ SG_ 1161 GearboxDynamicModeStatus "DATABASE_CANDIDATE: layout imported; physical meaning not independently verified. PSA-RE bits 5.5-5.4. Gearbox dynamic mode status Upstream default raw=0 (not necessarily valid data).";
CM_ SG_ 1161 BrakePressRequest "DATABASE_CANDIDATE: layout imported; physical meaning not independently verified. PSA-RE bits 5.6. Brake application request Upstream default raw=0 (not necessarily valid data).";
CM_ SG_ 1161 SportMode "DATABASE_CANDIDATE: layout imported; physical meaning not independently verified. PSA-RE bits 5.7. Sport mode status Upstream default raw=0 (not necessarily valid data).";
CM_ SG_ 1161 GearboxOilTemperature "DATABASE_CANDIDATE: layout imported; physical meaning not independently verified. PSA-RE bits 4.7-4.0. Gearbox oil temperature Raw invalid=255; numeric DBC decoders may still scale it: check raw before use. Upstream default raw=60 (not necessarily valid data).";
CM_ SG_ 1161 GearboxMilContinuousRequest "DATABASE_CANDIDATE: layout imported; physical meaning not independently verified. PSA-RE bits 3.0. Gearbox MIL lamp continuous lighting request Upstream default raw=0 (not necessarily valid data).";
CM_ SG_ 1161 GearboxMilBlinkingRequest "DATABASE_CANDIDATE: layout imported; physical meaning not independently verified. PSA-RE bits 3.1. MIL lamp blinking request linked to the simplified EOBD unit manager function Upstream default raw=0 (not necessarily valid data).";
CM_ SG_ 1161 GearboxMilOnCounterResetCommand "DATABASE_CANDIDATE: layout imported; physical meaning not independently verified. PSA-RE bits 3.2. Gearbox request to reset the MIL-ON mileage counters Upstream default raw=0 (not necessarily valid data).";
CM_ SG_ 1161 GearboxMisfireAlgorithmDi_6d0f78 "DATABASE_CANDIDATE: layout imported; physical meaning not independently verified. PSA-RE bits 3.3. Gearbox misfire-detection algorithm disturbance Upstream default raw=0 (not necessarily valid data).";
CM_ SG_ 1161 CrankingProhibit "DATABASE_CANDIDATE: layout imported; physical meaning not independently verified. PSA-RE bits 3.4. Flag prohibiting engine cranking Upstream default raw=1 (not necessarily valid data).";
CM_ SG_ 1161 DoublePedalPressDetection "DATABASE_CANDIDATE: layout imported; physical meaning not independently verified. PSA-RE bits 3.5. Double pedal press detection Upstream default raw=0 (not necessarily valid data).";
CM_ SG_ 1161 ShiftLockActive "DATABASE_CANDIDATE: layout imported; physical meaning not independently verified. PSA-RE bits 3.6. Shift-lock command active";
CM_ SG_ 1161 RadiatorFanIncreaseReques_ff8db7 "DATABASE_CANDIDATE: layout imported; physical meaning not independently verified. PSA-RE bits 3.7. Request from the gearbox for increased radiator fan cooling Upstream default raw=0 (not necessarily valid data).";
CM_ SG_ 1161 GearboxReadinessCodeSummary "DATABASE_CANDIDATE: layout imported; physical meaning not independently verified. PSA-RE bits 2.0. Gearbox readiness code summary Upstream default raw=1 (not necessarily valid data).";
CM_ SG_ 1161 GearChangeRefused "DATABASE_CANDIDATE: layout imported; physical meaning not independently verified. PSA-RE bits 2.1. Gear change refused Upstream default raw=0 (not necessarily valid data).";
CM_ SG_ 1161 GearboxDrivingLawSelection "DATABASE_CANDIDATE: layout imported; physical meaning not independently verified. PSA-RE bits 2.3-2.2. Gearbox shift strategy currently selected (normal, sport/performance, kickdown, snow), sent by the automatic and mechatronic gearbox Upstream default raw=0 (not necessarily valid data).";
CM_ SG_ 1161 GearboxFaultsStates "DATABASE_CANDIDATE: layout imported; physical meaning not independently verified. PSA-RE bits 2.7-2.4. Gearbox faults / states bitmask (oil change, MIL lamp, oil temperature alert, start inhibit) Upstream default raw=0 (not necessarily valid data).";
CM_ SG_ 1161 GearPositionDisplay "SUPPORTED_CAPTURE: coherent changes across independent messages. PSA-RE bits 1.3-1.0. Gear lever position for display Upstream default raw=15 (not necessarily valid data).";
CM_ SG_ 1161 GearboxMechanicallyEngagedGear "DATABASE_CANDIDATE: layout imported; physical meaning not independently verified. PSA-RE bits 1.7-1.4. Gear mechanically engaged in the gearbox (effective gear) Upstream default raw=15 (not necessarily valid data).";
CM_ BO_ 1172 "Observed OBD 6/14 HS1. CAN ID 0x494; no_HS1_definition. PSA-RE name: unknown.  Source: none in HS.HS1. Database sender alternatives: unknown. ECU labels are database claims; forwarding/physical transmitter not independently identified. All fitting source fields retained, including default/unavailable-only candidates. See audit/source JSON for exclusions and unresolved alternatives.";
CM_ SG_ 1172 RawByte8 "RAW. PSA-RE bits 8.7-8.0. Raw unmapped/padding bits; no physical interpretation.";
CM_ SG_ 1172 RawByte7 "RAW. PSA-RE bits 7.7-7.0. Raw unmapped/padding bits; no physical interpretation.";
CM_ SG_ 1172 RawByte6 "RAW. PSA-RE bits 6.7-6.0. Raw unmapped/padding bits; no physical interpretation.";
CM_ SG_ 1172 RawByte5 "RAW. PSA-RE bits 5.7-5.0. Raw unmapped/padding bits; no physical interpretation.";
CM_ SG_ 1172 RawByte4 "RAW. PSA-RE bits 4.7-4.0. Raw unmapped/padding bits; no physical interpretation.";
CM_ SG_ 1172 RawByte3 "RAW. PSA-RE bits 3.7-3.0. Raw unmapped/padding bits; no physical interpretation.";
CM_ SG_ 1172 RawByte2 "RAW. PSA-RE bits 2.7-2.0. Raw unmapped/padding bits; no physical interpretation.";
CM_ SG_ 1172 RawByte1 "RAW. PSA-RE bits 1.7-1.0. Raw unmapped/padding bits; no physical interpretation.";
CM_ BO_ 1173 "Observed OBD 6/14 HS1. CAN ID 0x495; DLC_mismatch. PSA-RE name: POWER_STEERING_STATUS. Power steering status. Source: https://github.com/prototux/PSA-RE/blob/67f7581e7622410efdbb29c7eda3b86982b9b450/buses/AEE2010.full/HS.HS1/495.yml. Database sender alternatives: DAE. ECU labels are database claims; forwarding/physical transmitter not independently identified. All fitting source fields retained, including default/unavailable-only candidates. See audit/source JSON for exclusions and unresolved alternatives.";
CM_ SG_ 1173 EpsOilTemperature "DATABASE_CANDIDATE: layout imported; physical meaning not independently verified. PSA-RE bits 4.7-4.0. Power steering oil temperature (°C) Raw invalid=255; numeric DBC decoders may still scale it: check raw before use. Upstream default raw=60 (not necessarily valid data). WARNING: upstream DLC 6 differs from observed 4; this in-bounds prefix is an unverified candidate.";
CM_ SG_ 1173 SteeringTorqueLimitState "DATABASE_CANDIDATE: layout imported; physical meaning not independently verified. PSA-RE bits 3.0. Status indicating that the power steering is limiting the applied torque Upstream default raw=0 (not necessarily valid data). WARNING: upstream DLC 6 differs from observed 4; this in-bounds prefix is an unverified candidate.";
CM_ SG_ 1173 SteeringWheelHeldByDriver "DATABASE_CANDIDATE: layout imported; physical meaning not independently verified. PSA-RE bits 3.1. Status indicating whether the driver is holding the steering wheel Upstream default raw=0 (not necessarily valid data). WARNING: upstream DLC 6 differs from observed 4; this in-bounds prefix is an unverified candidate.";
CM_ SG_ 1173 EpsStateForLka "DATABASE_CANDIDATE: layout imported; physical meaning not independently verified. PSA-RE bits 3.4-3.2. Electric power steering state with respect to the lane keeping assist (LKA) function Upstream default raw=0 (not necessarily valid data). WARNING: upstream DLC 6 differs from observed 4; this in-bounds prefix is an unverified candidate.";
CM_ SG_ 1173 EngineStopAuthorizationByEps "DATABASE_CANDIDATE: layout imported; physical meaning not independently verified. PSA-RE bits 3.5. Engine stop authorization from the power steering subsystem Upstream default raw=0 (not necessarily valid data). WARNING: upstream DLC 6 differs from observed 4; this in-bounds prefix is an unverified candidate.";
CM_ SG_ 1173 EngineRestartInhibitByEps "DATABASE_CANDIDATE: layout imported; physical meaning not independently verified. PSA-RE bits 3.6. Engine restart inhibit request from the power steering subsystem Upstream default raw=0 (not necessarily valid data). WARNING: upstream DLC 6 differs from observed 4; this in-bounds prefix is an unverified candidate.";
CM_ SG_ 1173 EngineRestartRequestByEps "DATABASE_CANDIDATE: layout imported; physical meaning not independently verified. PSA-RE bits 3.7. Engine restart request from the power steering subsystem Upstream default raw=0 (not necessarily valid data). WARNING: upstream DLC 6 differs from observed 4; this in-bounds prefix is an unverified candidate.";
CM_ SG_ 1173 Unused1 "DATABASE_CANDIDATE: layout imported; physical meaning not independently verified. PSA-RE bits 2.3-2.0.  WARNING: upstream DLC 6 differs from observed 4; this in-bounds prefix is an unverified candidate.";
CM_ SG_ 1173 EpsDynamicMode "DATABASE_CANDIDATE: layout imported; physical meaning not independently verified. PSA-RE bits 2.5-2.4. Electric power steering dynamic mode (normal, dynamic, adjustable) Upstream default raw=0 (not necessarily valid data). WARNING: upstream DLC 6 differs from observed 4; this in-bounds prefix is an unverified candidate.";
CM_ SG_ 1173 EpsWarningLampState2 "DATABASE_CANDIDATE: layout imported; physical meaning not independently verified. PSA-RE bits 2.7-2.6. Power steering warning lamp state Upstream default raw=0 (not necessarily valid data). WARNING: upstream DLC 6 differs from observed 4; this in-bounds prefix is an unverified candidate.";
CM_ SG_ 1173 SteeringWheelTorque "DATABASE_CANDIDATE: layout imported; physical meaning not independently verified. PSA-RE bits 1.7-1.0. Torque applied by the driver on the steering wheel; a negative value acts in the counterclockwise direction (N.m) Raw invalid=127; numeric DBC decoders may still scale it: check raw before use. Upstream default raw=127 (not necessarily valid data). WARNING: upstream DLC 6 differs from observed 4; this in-bounds prefix is an unverified candidate.";
CM_ BO_ 1186 "Observed OBD 6/14 HS1. CAN ID 0x4A2; no_HS1_definition. PSA-RE name: unknown.  Source: none in HS.HS1. Database sender alternatives: unknown. ECU labels are database claims; forwarding/physical transmitter not independently identified. All fitting source fields retained, including default/unavailable-only candidates. See audit/source JSON for exclusions and unresolved alternatives.";
CM_ SG_ 1186 RawByte2 "RAW. PSA-RE bits 2.7-2.0. Raw unmapped/padding bits; no physical interpretation.";
CM_ SG_ 1186 RawByte1 "RAW. PSA-RE bits 1.7-1.0. Raw unmapped/padding bits; no physical interpretation.";
CM_ BO_ 1230 "Observed OBD 6/14 HS1. CAN ID 0x4CE; ID_DLC_match. PSA-RE name: BSI_CABIN_DATA_11. Body controller cabin data: hybrid blower setpoint, load-shedding requests for ABS/ESP, electric power steering, EasyMove and suspension, demisting request and hybrid zero-emission cabin inhibition. Source: https://github.com/prototux/PSA-RE/blob/67f7581e7622410efdbb29c7eda3b86982b9b450/buses/AEE2010.full/HS.HS1/4CE.yml. Database sender alternatives: BSI. ECU labels are database claims; forwarding/physical transmitter not independently identified. All fitting source fields retained, including default/unavailable-only candidates. See audit/source JSON for exclusions and unresolved alternatives.";
CM_ SG_ 1230 RawByte8 "RAW. PSA-RE bits 8.7-8.0. Raw unmapped/padding bits; no physical interpretation.";
CM_ SG_ 1230 RawBits54_55 "RAW. PSA-RE bits 7.1-7.0. Raw unmapped/padding bits; no physical interpretation.";
CM_ SG_ 1230 FrontLeftWheelStatus "DATABASE_CANDIDATE: layout imported; physical meaning not independently verified. PSA-RE bits 7.6-7.2. Front left wheel tyre pressure status Upstream default raw=16 (not necessarily valid data).";
CM_ SG_ 1230 FrontRightWheelStatus "DATABASE_CANDIDATE: layout imported; physical meaning not independently verified. PSA-RE bits 6.3-7.7. Front right wheel tyre pressure status Upstream default raw=16 (not necessarily valid data).";
CM_ SG_ 1230 RearLeftWheelStatus "DATABASE_CANDIDATE: layout imported; physical meaning not independently verified. PSA-RE bits 5.0-6.4. Rear left wheel tyre pressure status Upstream default raw=16 (not necessarily valid data).";
CM_ SG_ 1230 RearRightWheelStatus "DATABASE_CANDIDATE: layout imported; physical meaning not independently verified. PSA-RE bits 5.5-5.1. Rear right wheel tyre pressure status Upstream default raw=16 (not necessarily valid data).";
CM_ SG_ 1230 AbsFault "DATABASE_CANDIDATE: layout imported; physical meaning not independently verified. PSA-RE bits 5.6. ABS/EHB fault Upstream default raw=0 (not necessarily valid data).";
CM_ SG_ 1230 BrakeLevelAlert "DATABASE_CANDIDATE: layout imported; physical meaning not independently verified. PSA-RE bits 5.7. Brake fluid level alert Upstream default raw=0 (not necessarily valid data).";
CM_ SG_ 1230 RejectPowerOnInEco "DATABASE_CANDIDATE: layout imported; physical meaning not independently verified. PSA-RE bits 4.0. Request to set to ON rejected (in economy mode) Upstream default raw=0 (not necessarily valid data).";
CM_ SG_ 1230 BrakesFault "DATABASE_CANDIDATE: layout imported; physical meaning not independently verified. PSA-RE bits 4.1. Brake pad wear fault Upstream default raw=0 (not necessarily valid data).";
CM_ SG_ 1230 FonctActLvvRvv "DATABASE_CANDIDATE: layout imported; physical meaning not independently verified. PSA-RE bits 4.3-4.2. Active selection of the cruise control/speed limiter/ACC function Upstream default raw=0 (not necessarily valid data).";
CM_ SG_ 1230 GearPositionToDisplay "DATABASE_CANDIDATE: layout imported; physical meaning not independently verified. PSA-RE bits 4.7-4.4. Gear position to display on the instrument cluster (P, R, N, D, 6th gear) Upstream default raw=11 (not necessarily valid data).";
CM_ SG_ 1230 FrontBlowerPlusSwitchState "DATABASE_CANDIDATE: layout imported; physical meaning not independently verified. PSA-RE bits 3.3-3.0. Front blower switch state when pressing the \"+\" button Upstream default raw=9 (not necessarily valid data).";
CM_ SG_ 1230 RearBlowerPlusSwitchState "DATABASE_CANDIDATE: layout imported; physical meaning not independently verified. PSA-RE bits 3.7-3.4. Rear blower switch state when pressing the \"+\" button Upstream default raw=9 (not necessarily valid data).";
CM_ SG_ 1230 UnderinflationAlert "DATABASE_CANDIDATE: layout imported; physical meaning not independently verified. PSA-RE bits 2.0. Tyre underinflation alert Upstream default raw=0 (not necessarily valid data).";
CM_ SG_ 1230 CenterTemperatureSetpoint "DATABASE_CANDIDATE: layout imported; physical meaning not independently verified. PSA-RE bits 2.3-2.1. Centered temperature setpoint value Upstream default raw=3 (not necessarily valid data).";
CM_ SG_ 1230 MaintenanceType2 "DATABASE_CANDIDATE: layout imported; physical meaning not independently verified. PSA-RE bits 2.4. Maintenance schedule type (mileage-based or mileage + time-based) Upstream default raw=0 (not necessarily valid data).";
CM_ SG_ 1230 MaintenanceType "DATABASE_CANDIDATE: layout imported; physical meaning not independently verified. PSA-RE bits 2.5. Maintenance type";
CM_ SG_ 1230 TimeSymbol "DATABASE_CANDIDATE: layout imported; physical meaning not independently verified. PSA-RE bits 2.6. Sign of the time-based deadline";
CM_ SG_ 1230 ParkingBrakes "DATABASE_CANDIDATE: layout imported; physical meaning not independently verified. PSA-RE bits 2.7. Parking brake status Upstream default raw=0 (not necessarily valid data).";
CM_ SG_ 1230 ParticleFilterFault "DATABASE_CANDIDATE: layout imported; physical meaning not independently verified. PSA-RE bits 1.0. Particulate filter indicator light request Upstream default raw=0 (not necessarily valid data).";
CM_ SG_ 1230 CheckAutonomy "DATABASE_CANDIDATE: layout imported; physical meaning not independently verified. PSA-RE bits 1.1. Invalid range";
CM_ SG_ 1230 DistanceBlinking "DATABASE_CANDIDATE: layout imported; physical meaning not independently verified. PSA-RE bits 1.2. Display of the mileage and its sign";
CM_ SG_ 1230 MaintenanceWrenchIconDisplay "DATABASE_CANDIDATE: layout imported; physical meaning not independently verified. PSA-RE bits 1.3. Maintenance wrench icon display mode (fixed/blinking) Upstream default raw=0 (not necessarily valid data).";
CM_ SG_ 1230 OilPressureAlert "DATABASE_CANDIDATE: layout imported; physical meaning not independently verified. PSA-RE bits 1.4. Oil pressure alert Upstream default raw=0 (not necessarily valid data).";
CM_ SG_ 1230 OilLevelAlert "DATABASE_CANDIDATE: layout imported; physical meaning not independently verified. PSA-RE bits 1.5. Oil level alert Upstream default raw=0 (not necessarily valid data).";
CM_ SG_ 1230 LowFuelBlink "DATABASE_CANDIDATE: layout imported; physical meaning not independently verified. PSA-RE bits 1.6. Low fuel indicator blinking request Upstream default raw=0 (not necessarily valid data).";
CM_ SG_ 1230 DieselWaterFault "DATABASE_CANDIDATE: layout imported; physical meaning not independently verified. PSA-RE bits 1.7. Water in diesel fuel filter fault Upstream default raw=0 (not necessarily valid data).";
CM_ BO_ 1257 "Observed OBD 6/14 HS1. CAN ID 0x4E9; ID_DLC_match. PSA-RE name: GEARBOX_DATA_2. Gearbox data: gear-change refused, fault state, start inhibition, sport mode, lever position display, driving program, engaged mechanical gear, target gear and driver-requested gear display. Source: https://github.com/prototux/PSA-RE/blob/67f7581e7622410efdbb29c7eda3b86982b9b450/buses/AEE2010.full/HS.HS1/4E9.yml. Database sender alternatives: BVA. ECU labels are database claims; forwarding/physical transmitter not independently identified. All fitting source fields retained, including default/unavailable-only candidates. See audit/source JSON for exclusions and unresolved alternatives.";
CM_ SG_ 1257 Unused1 "DATABASE_CANDIDATE: layout imported; physical meaning not independently verified. PSA-RE bits 4.2-4.0. ";
CM_ SG_ 1257 EagbWaterPumpFault "DATABASE_CANDIDATE: layout imported; physical meaning not independently verified. PSA-RE bits 4.3. EAGB (electric automated gearbox) water pump fault state Upstream default raw=0 (not necessarily valid data).";
CM_ SG_ 1257 GearboxEmergencyMode "DATABASE_CANDIDATE: layout imported; physical meaning not independently verified. PSA-RE bits 4.4. Gearbox emergency mode active Upstream default raw=0 (not necessarily valid data).";
CM_ SG_ 1257 SscFaultState "DATABASE_CANDIDATE: layout imported; physical meaning not independently verified. PSA-RE bits 4.6-4.5. SSC actuator fault state (opening/closing fault) Upstream default raw=0 (not necessarily valid data).";
CM_ SG_ 1257 PemFailsafeState "DATABASE_CANDIDATE: layout imported; physical meaning not independently verified. PSA-RE bits 4.7. Primary electric machine (PEM) degraded mode status Upstream default raw=0 (not necessarily valid data).";
CM_ SG_ 1257 EagbFailsafeState "DATABASE_CANDIDATE: layout imported; physical meaning not independently verified. PSA-RE bits 3.0. EAGB (electric automated gearbox) degraded mode status Upstream default raw=0 (not necessarily valid data).";
CM_ SG_ 1257 EagbDriveState "DATABASE_CANDIDATE: layout imported; physical meaning not independently verified. PSA-RE bits 3.2-3.1. EAGB (electric automated gearbox) control state Upstream default raw=0 (not necessarily valid data).";
CM_ SG_ 1257 GearboxManualModeSelection "DATABASE_CANDIDATE: layout imported; physical meaning not independently verified. PSA-RE bits 3.4-3.3. Gearbox manual mode selection (automatic, manual, ASM) Upstream default raw=0 (not necessarily valid data).";
CM_ SG_ 1257 GearboxDynamicModeState "DATABASE_CANDIDATE: layout imported; physical meaning not independently verified. PSA-RE bits 3.7-3.5. Current gearbox manual/dynamic mode state (normal, sport, eco, snow) Upstream default raw=0 (not necessarily valid data).";
CM_ SG_ 1257 FrameChecksum4e9 "DATABASE_CANDIDATE: layout imported; physical meaning not independently verified. PSA-RE bits 2.3-2.0. Checksum of frame 0x4E9";
CM_ SG_ 1257 ProcessCounter4e9 "DATABASE_CANDIDATE: layout imported; physical meaning not independently verified. PSA-RE bits 2.7-2.4. 4-bit rolling process counter of frame 0x4E9";
CM_ SG_ 1257 ParkingLockState "SUPPORTED_CAPTURE: coherent changes across independent messages. PSA-RE bits 1.1-1.0. Gearbox parking lock state Upstream default raw=3 (not necessarily valid data).";
CM_ SG_ 1257 TcuClearDtcRequest "DATABASE_CANDIDATE: layout imported; physical meaning not independently verified. PSA-RE bits 1.2. Request to clear OBD faults from the TCU (LVNSD) Upstream default raw=0 (not necessarily valid data).";
CM_ SG_ 1257 SemiAutomaticMode "DATABASE_CANDIDATE: layout imported; physical meaning not independently verified. PSA-RE bits 1.3. Semi-automatic manual mode (ASM) status Upstream default raw=0 (not necessarily valid data).";
CM_ SG_ 1257 FreewheelingAuthorizationGearbox "DATABASE_CANDIDATE: layout imported; physical meaning not independently verified. PSA-RE bits 1.5-1.4. Freewheeling function authorization given by the automatic gearbox (BVA) Upstream default raw=0 (not necessarily valid data).";
CM_ SG_ 1257 GearboxFreewheelingStatus "DATABASE_CANDIDATE: layout imported; physical meaning not independently verified. PSA-RE bits 1.7-1.6. Gearbox freewheeling function feedback status Upstream default raw=0 (not necessarily valid data).";
CM_ BO_ 1272 "Observed OBD 6/14 HS1. CAN ID 0x4F8; DLC_mismatch. PSA-RE name: ENGINE_ECU_DATA_8. Engine ECU data: power-reduction-off request, atmospheric pressure, main wake-up and SCR purge wake-up. Source: https://github.com/prototux/PSA-RE/blob/67f7581e7622410efdbb29c7eda3b86982b9b450/buses/AEE2010.full/HS.HS1/4F8.yml. Database sender alternatives: CMM. ECU labels are database claims; forwarding/physical transmitter not independently identified. All fitting source fields retained, including default/unavailable-only candidates. See audit/source JSON for exclusions and unresolved alternatives.";
CM_ SG_ 1272 RawByte5 "RAW. PSA-RE bits 5.7-5.0. Raw unmapped/padding bits; no physical interpretation. WARNING: upstream DLC 8 differs from observed 5; this in-bounds prefix is an unverified candidate.";
CM_ SG_ 1272 IcePowerState "DATABASE_CANDIDATE: layout imported; physical meaning not independently verified. PSA-RE bits 4.1-4.0. Combustion engine operating state Upstream default raw=0 (not necessarily valid data). WARNING: upstream DLC 8 differs from observed 5; this in-bounds prefix is an unverified candidate.";
CM_ SG_ 1272 PrimaryMachinePowerState "DATABASE_CANDIDATE: layout imported; physical meaning not independently verified. PSA-RE bits 4.4-4.2. Primary electric machine operating state Upstream default raw=0 (not necessarily valid data). WARNING: upstream DLC 8 differs from observed 5; this in-bounds prefix is an unverified candidate.";
CM_ SG_ 1272 SteeringLoadShedRequest "DATABASE_CANDIDATE: layout imported; physical meaning not independently verified. PSA-RE bits 4.7-4.5. Load-shedding request sent to the electric power steering ECU Upstream default raw=0 (not necessarily valid data). WARNING: upstream DLC 8 differs from observed 5; this in-bounds prefix is an unverified candidate.";
CM_ SG_ 1272 ProcessCounter4b4f8 "DATABASE_CANDIDATE: layout imported; physical meaning not independently verified. PSA-RE bits 3.3-3.0. 4-bit process counter Upstream default raw=0 (not necessarily valid data). WARNING: upstream DLC 8 differs from observed 5; this in-bounds prefix is an unverified candidate.";
CM_ SG_ 1272 ChecksumFrame4f8 "DATABASE_CANDIDATE: layout imported; physical meaning not independently verified. PSA-RE bits 3.7-3.4. Frame checksum WARNING: upstream DLC 8 differs from observed 5; this in-bounds prefix is an unverified candidate.";
CM_ SG_ 1272 AcElectricalPowerLimit "DATABASE_CANDIDATE: layout imported; physical meaning not independently verified. PSA-RE bits 2.7-2.0. Power consumable by the air conditioning components (electric AC compressor and high-voltage water heater) (W) Raw invalid=255; numeric DBC decoders may still scale it: check raw before use. Upstream default raw=0 (not necessarily valid data). WARNING: upstream DLC 8 differs from observed 5; this in-bounds prefix is an unverified candidate.";
CM_ SG_ 1272 SemiAutomaticMode "DATABASE_CANDIDATE: layout imported; physical meaning not independently verified. PSA-RE bits 1.0. Semi-automatic manual mode (ASM) status Upstream default raw=0 (not necessarily valid data). WARNING: upstream DLC 8 differs from observed 5; this in-bounds prefix is an unverified candidate.";
CM_ SG_ 1272 QuickCoolingRequest "DATABASE_CANDIDATE: layout imported; physical meaning not independently verified. PSA-RE bits 1.1. Quick cooling request Upstream default raw=0 (not necessarily valid data). WARNING: upstream DLC 8 differs from observed 5; this in-bounds prefix is an unverified candidate.";
CM_ SG_ 1272 EngineStartWithSsc "DATABASE_CANDIDATE: layout imported; physical meaning not independently verified. PSA-RE bits 1.2. Engine start performed with the SSC (starter-alternator) Upstream default raw=0 (not necessarily valid data). WARNING: upstream DLC 8 differs from observed 5; this in-bounds prefix is an unverified candidate.";
CM_ SG_ 1272 EngineRunNeedIgnoringGbx "DATABASE_CANDIDATE: layout imported; physical meaning not independently verified. PSA-RE bits 1.3. Need for the engine to run, not taking gearbox needs into account Upstream default raw=0 (not necessarily valid data). WARNING: upstream DLC 8 differs from observed 5; this in-bounds prefix is an unverified candidate.";
CM_ SG_ 1272 IceEcuDtcClearRequest "DATABASE_CANDIDATE: layout imported; physical meaning not independently verified. PSA-RE bits 1.4. Request to clear the combustion engine ECU's OBD fault codes Upstream default raw=0 (not necessarily valid data). WARNING: upstream DLC 8 differs from observed 5; this in-bounds prefix is an unverified candidate.";
CM_ SG_ 1272 EbdLoadShedRequest "DATABASE_CANDIDATE: layout imported; physical meaning not independently verified. PSA-RE bits 1.5. Load-shedding request from the electronic brake force distribution (EBD) Upstream default raw=0 (not necessarily valid data). WARNING: upstream DLC 8 differs from observed 5; this in-bounds prefix is an unverified candidate.";
CM_ SG_ 1272 LvBatteryDiagRequest "DATABASE_CANDIDATE: layout imported; physical meaning not independently verified. PSA-RE bits 1.6. Activation request for the low-voltage battery module diagnostic Upstream default raw=0 (not necessarily valid data). WARNING: upstream DLC 8 differs from observed 5; this in-bounds prefix is an unverified candidate.";
CM_ SG_ 1272 LvBatteryModeRequest "DATABASE_CANDIDATE: layout imported; physical meaning not independently verified. PSA-RE bits 1.7. Low-voltage battery module open/close request Upstream default raw=0 (not necessarily valid data). WARNING: upstream DLC 8 differs from observed 5; this in-bounds prefix is an unverified candidate.";
CM_ BO_ 1274 "Observed OBD 6/14 HS1. CAN ID 0x4FA; ID_DLC_match. PSA-RE name: LVNSD_DATA. LVNSD node data: service-blink request, battery diagnostic state and switch state. Source: https://github.com/prototux/PSA-RE/blob/67f7581e7622410efdbb29c7eda3b86982b9b450/buses/AEE2010.full/HS.HS1/4FA.yml. Database sender alternatives: LVNSD. ECU labels are database claims; forwarding/physical transmitter not independently identified. All fitting source fields retained, including default/unavailable-only candidates. See audit/source JSON for exclusions and unresolved alternatives.";
CM_ SG_ 1274 Unused1 "DATABASE_CANDIDATE: layout imported; physical meaning not independently verified. PSA-RE bits 2.1-4.0. ";
CM_ SG_ 1274 LvBatteryStopServiceBlinkRequest "DATABASE_CANDIDATE: layout imported; physical meaning not independently verified. PSA-RE bits 2.2. Request from the low-voltage battery module to blink the Stop and Service warning lamps on the display Upstream default raw=0 (not necessarily valid data).";
CM_ SG_ 1274 LvBatterySwitchState "DATABASE_CANDIDATE: layout imported; physical meaning not independently verified. PSA-RE bits 2.4-2.3. Low-voltage battery switch state Upstream default raw=0 (not necessarily valid data).";
CM_ SG_ 1274 LvBatteryDiagResult "DATABASE_CANDIDATE: layout imported; physical meaning not independently verified. PSA-RE bits 2.7-2.5. Conclusion of the low-voltage battery diagnostic Upstream default raw=0 (not necessarily valid data).";
CM_ SG_ 1274 ProcessCounter4b4fa "DATABASE_CANDIDATE: layout imported; physical meaning not independently verified. PSA-RE bits 1.3-1.0. 4-bit process counter Upstream default raw=0 (not necessarily valid data).";
CM_ SG_ 1274 ChecksumFrame4fa "DATABASE_CANDIDATE: layout imported; physical meaning not independently verified. PSA-RE bits 1.7-1.4. Frame checksum";
CM_ BO_ 1278 "Observed OBD 6/14 HS1. CAN ID 0x4FE; ID_DLC_match. PSA-RE name: ELECTRONIC_SHIFT_LEVER_DATA. Electronic gear-shift lever data: acknowledgement validation, brake request, fault, direction control, driver action, lever movement and position, unlock request. Source: https://github.com/prototux/PSA-RE/blob/67f7581e7622410efdbb29c7eda3b86982b9b450/buses/AEE2010.full/HS.HS1/4FE.yml. Database sender alternatives: ESM,BSI. ECU labels are database claims; forwarding/physical transmitter not independently identified. All fitting source fields retained, including default/unavailable-only candidates. See audit/source JSON for exclusions and unresolved alternatives.";
CM_ SG_ 1278 Unused1 "DATABASE_CANDIDATE: layout imported; physical meaning not independently verified. PSA-RE bits 3.1-3.0. ";
CM_ SG_ 1278 AutoParkManeuverRequest "DATABASE_CANDIDATE: layout imported; physical meaning not independently verified. PSA-RE bits 3.3-3.2. Maneuver request from the automatic parking assist (ACPK) system Upstream default raw=0 (not necessarily valid data).";
CM_ SG_ 1278 DriverLeverTakeoverRequest "DATABASE_CANDIDATE: layout imported; physical meaning not independently verified. PSA-RE bits 3.6-3.4. Driver request to take back control of the gear lever while the automatic parking assist (ACPK) is operating Upstream default raw=0 (not necessarily valid data).";
CM_ SG_ 1278 SteeringControlledByAutoPark "DATABASE_CANDIDATE: layout imported; physical meaning not independently verified. PSA-RE bits 3.7. Status indicating whether steering is controlled by the automatic parking assist (ACPK) Upstream default raw=0 (not necessarily valid data).";
CM_ SG_ 1278 GearSelectorFault "DATABASE_CANDIDATE: layout imported; physical meaning not independently verified. PSA-RE bits 2.1-2.0. Gear selector module fault Upstream default raw=0 (not necessarily valid data).";
CM_ SG_ 1278 LeverMovement "SUPPORTED_CAPTURE: coherent changes across independent messages. PSA-RE bits 2.2. Gear lever movement detected Upstream default raw=0 (not necessarily valid data).";
CM_ SG_ 1278 BrakePedalRequestToDriver "DATABASE_CANDIDATE: layout imported; physical meaning not independently verified. PSA-RE bits 2.3. Request for the driver to press the brake pedal Upstream default raw=0 (not necessarily valid data).";
CM_ SG_ 1278 LeverUnlockButtonRequest "DATABASE_CANDIDATE: layout imported; physical meaning not independently verified. PSA-RE bits 2.4. Request for the driver to press the lever unlock button Upstream default raw=0 (not necessarily valid data).";
CM_ SG_ 1278 LeverPosition "SUPPORTED_CAPTURE: coherent changes across independent messages. PSA-RE bits 2.7-2.5. Monostable gear lever position (P, R, N, D, M) Upstream default raw=6 (not necessarily valid data).";
CM_ SG_ 1278 RollingCounter "SUPPORTED_CAPTURE: coherent changes across independent messages. PSA-RE bits 1.3-1.0. 4-bit process counter Upstream default raw=0 (not necessarily valid data).";
CM_ SG_ 1278 Checksum "SUPPORTED_CAPTURE: coherent changes across independent messages. PSA-RE bits 1.7-1.4. Frame checksum";
VAL_ 1012 BatteryTempSlot49 255 "Not_available" ;
VAL_ 1012 BatteryTempSlot42 255 "Not_available" ;
VAL_ 1012 BatteryTempSlot35 255 "Not_available" ;
VAL_ 1012 BatteryTempSlot28 255 "Not_available" ;
VAL_ 1012 BatteryTempSlot21 255 "Not_available" ;
VAL_ 1012 BatteryTempSlot14 255 "Not_available" ;
VAL_ 1012 BatteryTempSlot07 255 "Not_available" ;
VAL_ 1012 BatteryTempSlot48 255 "Not_available" ;
VAL_ 1012 BatteryTempSlot41 255 "Not_available" ;
VAL_ 1012 BatteryTempSlot34 255 "Not_available" ;
VAL_ 1012 BatteryTempSlot27 255 "Not_available" ;
VAL_ 1012 BatteryTempSlot20 255 "Not_available" ;
VAL_ 1012 BatteryTempSlot13 255 "Not_available" ;
VAL_ 1012 BatteryTempSlot06 255 "Not_available" ;
VAL_ 1012 BatteryTempSlot54 255 "Not_available" ;
VAL_ 1012 BatteryTempSlot47 255 "Not_available" ;
VAL_ 1012 BatteryTempSlot40 255 "Not_available" ;
VAL_ 1012 BatteryTempSlot33 255 "Not_available" ;
VAL_ 1012 BatteryTempSlot26 255 "Not_available" ;
VAL_ 1012 BatteryTempSlot19 255 "Not_available" ;
VAL_ 1012 BatteryTempSlot12 255 "Not_available" ;
VAL_ 1012 BatteryTempSlot05 255 "Not_available" ;
VAL_ 1012 BatteryTempSlot53 255 "Not_available" ;
VAL_ 1012 BatteryTempSlot46 255 "Not_available" ;
VAL_ 1012 BatteryTempSlot39 255 "Not_available" ;
VAL_ 1012 BatteryTempSlot32 255 "Not_available" ;
VAL_ 1012 BatteryTempSlot25 255 "Not_available" ;
VAL_ 1012 BatteryTempSlot18 255 "Not_available" ;
VAL_ 1012 BatteryTempSlot11 255 "Not_available" ;
VAL_ 1012 BatteryTempSlot04 255 "Not_available" ;
VAL_ 1012 BatteryTempSlot52 255 "Not_available" ;
VAL_ 1012 BatteryTempSlot45 255 "Not_available" ;
VAL_ 1012 BatteryTempSlot38 255 "Not_available" ;
VAL_ 1012 BatteryTempSlot31 255 "Not_available" ;
VAL_ 1012 BatteryTempSlot24 255 "Not_available" ;
VAL_ 1012 BatteryTempSlot17 255 "Not_available" ;
VAL_ 1012 BatteryTempSlot10 255 "Not_available" ;
VAL_ 1012 BatteryTempSlot03 255 "Not_available" ;
VAL_ 1012 BatteryTempSlot51 255 "Not_available" ;
VAL_ 1012 BatteryTempSlot44 255 "Not_available" ;
VAL_ 1012 BatteryTempSlot37 255 "Not_available" ;
VAL_ 1012 BatteryTempSlot30 255 "Not_available" ;
VAL_ 1012 BatteryTempSlot23 255 "Not_available" ;
VAL_ 1012 BatteryTempSlot16 255 "Not_available" ;
VAL_ 1012 BatteryTempSlot09 255 "Not_available" ;
VAL_ 1012 BatteryTempSlot02 255 "Not_available" ;
VAL_ 1012 BatteryTempSlot50 255 "Not_available" ;
VAL_ 1012 BatteryTempSlot43 255 "Not_available" ;
VAL_ 1012 BatteryTempSlot36 255 "Not_available" ;
VAL_ 1012 BatteryTempSlot29 255 "Not_available" ;
VAL_ 1012 BatteryTempSlot22 255 "Not_available" ;
VAL_ 1012 BatteryTempSlot15 255 "Not_available" ;
VAL_ 1012 BatteryTempSlot08 255 "Not_available" ;
VAL_ 1012 BatteryTempSlot01 255 "Not_available" ;
VAL_ 1035 SecondaryRightLineLkaStatus 0 "Invalid" 1 "Valid" ;
VAL_ 1035 SecondaryRightLineType 0 "Undetermined" 1 "Solid line detected" 2 "Dotted line detected" 3 "Double solid line detected" 5 "Road Edge detected" 6 "Barrier detected" 7 "Invalid" ;
VAL_ 1035 SecondaryLeftLineLkaStatus 0 "Invalid" 1 "Valid" ;
VAL_ 1035 SecondaryLeftLineType 0 "Undetermined" 1 "Solid line detected" 2 "Dotted line detected" 3 "Double solid line detected" 5 "Road Edge detected" 6 "Barrier detected" 7 "Invalid" ;
VAL_ 1035 SecondaryRightLineDistance 511 "Not_available" ;
VAL_ 1035 SecondaryLeftLineDistance 511 "Not_available" ;
VAL_ 1037 RearRightWheelSpeedSensorFault 0 "No fault" 1 "Rear-right pulse counter fault" ;
VAL_ 1037 RearLeftWheelSpeedSensorFault 0 "No fault on the RRL pulse counter" 1 "Fault on the rear left pulse counter" ;
VAL_ 1037 FrontRightWheelSpeedSensorFault 0 "No fault on front-right pulse counter" 1 "Fault" ;
VAL_ 1037 FrontLeftWheelSpeedSensorFault 0 "No fault on the FRL pulse counter" 1 "Front left pulse counter fault" ;
VAL_ 1038 HighBeamCommand 0 "Off" 1 "On" ;
VAL_ 1038 LowBeamCommand 0 "Off" 1 "On" ;
VAL_ 1038 HeadlightFlashCommand 0 "Off" 1 "On" ;
VAL_ 1038 SideLightsCommand 0 "Off" 1 "On" ;
VAL_ 1038 WelcomeLightingMode 0 "No function" 1 "Lighting on unlock, 15 s" 2 "Lighting on unlock, 30 s" 3 "Unlock lighting, 60 s" 4 "Off" 5 "Follow-me-home lighting, 15 s" 6 "Follow-me-home lighting, 30 s" 7 "Follow-me-home lighting, 60 s" 8 "Remote lighting" 9 "Lock" 10 "Location" 11 "Event" 12 "Shop window" 13 "Inhibition" 15 "Invalid" ;
VAL_ 1038 MatrixBeamCommand 0 "Function off" 1 "Function active" ;
VAL_ 1038 DriverSide 0 "Invalid" 1 "Right direction" 2 "Left direction" 3 "Invalid" ;
VAL_ 1038 DrlCommand 0 "Off" 1 "On" ;
VAL_ 1038 ThreeModuleCutoffRequest 0 "Not requested" 1 "Requested" ;
VAL_ 1038 WelcomeScreenColor 0 "Color 1" 1 "Color 2" 2 "Colour 3" 3 "Color 4" 4 "Colour 5" 5 "Colour 6" 6 "Colour 7" 7 "Color 8" 10 "Inhibition" ;
VAL_ 1042 FapDownstreamTemperature 255 "Not_available" ;
VAL_ 1042 MinAdditiveLevelReached 0 "Invalid data" 1 "Minimum level reached" 2 "Minimum level not reached" 3 "Invalid data" ;
VAL_ 1042 RearWindowStatus 0 "Rear window closed or no rear window" 1 "Rear window open" ;
VAL_ 1042 DoorsStatus 0 "Boot closed" 1 "Driver door open" 2 "Passenger door open" 4 "Rear left door open" 8 "ARD open" 16 "Trunk open" ;
VAL_ 1042 EngineOilTemperatureBsi 255 "Not_available" ;
VAL_ 1042 SlidingRoofState 0 "Sliding roof closed" 1 "Sliding roof half-open / open" 2 "Sliding roof in convertible position" 3 "Fault / invalid" ;
VAL_ 1042 FuelLow 0 "Level above minimum" 1 "Minimum level reached" ;
VAL_ 1042 FuelGaugeDiagnostic 0 "No fuel gauge fault" 1 "Invalid fuel gauge" 2 "Fuel gauge short-circuited to ground" 3 "Fuel gauge open circuit" ;
VAL_ 1042 PowerSteeringModeRequest 0 "Normal mode request" 1 "Dynamic mode request" 2 "Tunable mode requested" ;
VAL_ 1042 GearboxSnowSwitch 0 "AGB snow switch / snow-sport push button not pressed" 1 "Gearbox snow switch pressed / sport-snow combined switch on" ;
VAL_ 1042 GearboxSportSwitch 0 "Gearbox Sport switch not pressed" 1 "Gearbox Sport switch pressed" ;
VAL_ 1042 GearboxPaddleInfo 0 "No change" 1 "Gear up" 2 "Gear down" 3 "Invalid" ;
VAL_ 1042 AsrEspDisconnectRequest 0 "No ASR or CDC disconnection requested" 1 "ASR or CDS disconnection requested" ;
VAL_ 1042 BrakeSwitchDiagnosticCondition 0 "Diagnostic window conditions not met" 1 "Diagnostic window entered" ;
VAL_ 1042 EngineOilMeasurementRequest 0 "No engine oil measurement request" 1 "Engine oil measurement request" ;
VAL_ 1042 CabinHeatingRequest 0 "No activation request" 1 "Switch-on request" ;
VAL_ 1042 AdaptiveDampingModeRequest 0 "Normal mode request" 1 "Dynamic mode request" 2 "Comfort mode requested" ;
VAL_ 1042 BrakePedalSwitchDisabled 0 "Main brake switch OK" 1 "Main brake switch faulty" ;
VAL_ 1042 GearboxManualModePushRequest 0 "Push button released" 1 "Push button pressed" ;
VAL_ 1042 ReverseGearManualGearbox 0 "Forward range or neutral" 1 "Reverse engaged" ;
VAL_ 1042 ParkingBrakeSwitch 0 "Parking brake released" 1 "Parking brake applied" ;
VAL_ 1042 DynamicPackActivationComplement 0 "Dynamic mode request" 1 "Normal mode request" ;
VAL_ 1042 BrakePedalSwitch 0 "Brake pedal released" 1 "Brake pedal pressed" ;
VAL_ 1042 DynamicPackActivation 0 "Normal mode request" 1 "Dynamic mode request" ;
VAL_ 1042 ElectricalSystemNeedFault 0 "No fault" 1 "Fault detected" ;
VAL_ 1054 MatrixBeamPerceptionStatus 0 "Available" 1 "Paused" 2 "Unavailable" 3 "Invalid" ;
VAL_ 1054 CenterLeadVehicleCrossState 0 "Leading vehicle" 1 "Oncoming vehicle" 2 "No vehicle" 3 "Unavailable" ;
VAL_ 1054 ClusterMinVerticalAngle 127 "Not_available" ;
VAL_ 1054 RightLeadVehicleCrossState 0 "Leading vehicle" 1 "Oncoming vehicle" 2 "No vehicle" 3 "Unavailable" ;
VAL_ 1054 ClusterRightEdgeAngle 255 "Not_available" ;
VAL_ 1054 ClusterRightEdgeDistance 511 "Not_available" ;
VAL_ 1054 LeftLeadVehicleCrossState 0 "Leading vehicle" 1 "Oncoming vehicle" 2 "No vehicle" 3 "Unavailable" ;
VAL_ 1054 ClusterLeftEdgeAngle 255 "Not_available" ;
VAL_ 1054 ClusterLeftEdgeDistance 511 "Not_available" ;
VAL_ 1067 LkaCameraFault 0 "No fault detected" 1 "Failure detected" ;
VAL_ 1067 LeftLineValidityLka 0 "Not valid" 1 "Enter" ;
VAL_ 1067 LeftLineValidityDaa 0 "Invalid" 1 "Valid" ;
VAL_ 1067 LeftLineType 0 "Undetermined" 1 "Solid line detected" 2 "Dotted line detected" 3 "Double solid line detected" 5 "Road Edge detected" 6 "Barrier detected" 7 "Invalid" ;
VAL_ 1067 LeftLineHeadingAngle 2047 "Not_available" ;
VAL_ 1067 LeftLineCurvatureDerivative 32767 "Not_available" ;
VAL_ 1067 LeftLineEstimatedCurvature 32767 "Not_available" ;
VAL_ 1074 EngineStartIntentGeneral 1 "Start intent" 2 "No intention to start" ;
VAL_ 1074 EcoModeDriverRequest 0 "Eco mode not requested" 1 "Eco mode requested" ;
VAL_ 1074 HybridPowerLatchWakeup 0 "No power latch wake-up request" 1 "Power latch wake-up request" ;
VAL_ 1074 ElectricalNetworkState 0 "Nominal torque interface" 1 "Degraded TI" 2 "Information availability request" 3 "Starting" 4 "Restart" 5 "Nominal" 6 "Degraded" 7 "Safe mode" ;
VAL_ 1074 MainStatus 0 "Stop" 1 "Ignition on" 2 "DEM (starter)" ;
VAL_ 1074 StartRequestStatus 0 "Nominal request" 1 "Secondary request" ;
VAL_ 1074 UcapsPrechargeWakeup 0 "Wake-up not requested" 1 "Wake-up requested" ;
VAL_ 1074 EnginePostVentilationWakeup 0 "Wake-up not requested" 1 "Wake-up requested" ;
VAL_ 1074 TcuHydraulicWakeupRequest 0 "Wake-up not requested" 1 "Wake-up requested" ;
VAL_ 1074 TireHeightCorrectionWakeu_4ee41a 0 "Wake-up not requested" 1 "Wake-up requested" ;
VAL_ 1074 EbbBrakeAssistWakeup 0 "No wakeup" 1 "Clock" ;
VAL_ 1074 DisplayNeedsWakeupRequest 0 "Wake-up not requested" 1 "Wake-up requested" ;
VAL_ 1074 MecatronicHeadlampWakeupRequest 0 "Off" 1 "On" ;
VAL_ 1074 EngineOilMeasurementWakeup 0 "Wake-up not requested" 1 "Wake-up requested" ;
VAL_ 1074 VehicleOverloadWakeup 0 "Off" 1 "On" ;
VAL_ 1074 EngineStartPreparationWakeup 0 "Wake-up not requested" 1 "Wake-up requested" ;
VAL_ 1074 BrakeEcuSpeedWakeupRequest 0 "No partial wake-up request" 1 "Partial wake-up request" ;
VAL_ 1074 AddedFuelVolume 255 "Not_available" ;
VAL_ 1074 FseDisplayWakeupRequest 0 "Wake-up not requested" 1 "Wake-up requested" ;
VAL_ 1074 ShortSharedPrePostWakeup 0 "No request" 1 "Requested" ;
VAL_ 1074 ShortPostMainWakeup1 0 "No request" 1 "Requested" ;
VAL_ 1074 PriorityElectricalConsumer 0 "No priority vehicle electrical consumer engaged" 1 "Priority vehicle electrical consumer engaged" ;
VAL_ 1074 HadcEnableRequest 0 "No activation request" 1 "HADC activation request" ;
VAL_ 1074 EngineStartPreparationRequest 0 "No engine preparation requested" 1 "Engine preparation request" ;
VAL_ 1074 PulseStartRequest 1 "No pulse-start request" 2 "Momentary start request" ;
VAL_ 1074 ElectricalSystemStartIntent 1 "No wish to start" 2 "Wish to start" ;
VAL_ 1074 EngineStopRequest 1 "No request stop engine" 2 "Combustion engine stop request" ;
VAL_ 1074 StarterStopRequest 0 "No starter stop request" 1 "Starter stop request" ;
VAL_ 1074 HeightCorrectionWakeupRequest 0 "Wake-up not requested" 1 "Wake-up requested" ;
VAL_ 1074 AntiTheftWakeupRequest 0 "Wake-up not requested" 1 "Wake-up requested" ;
VAL_ 1074 GearboxStateWakeupRequest 0 "Wake-up not requested" 1 "Wake-up requested" ;
VAL_ 1074 MainWakeupStatus 0 "Invalid RCD" 1 "No main wake-up request" 2 "Main wake-up request" 3 "Invalid" ;
VAL_ 1086 RoadProfileRightPoint3 255 "Not_available" ;
VAL_ 1086 RoadProfileLeftPoint3 255 "Not_available" ;
VAL_ 1086 RoadProfileRightPoint2 255 "Not_available" ;
VAL_ 1086 RoadProfileLeftPoint2 255 "Not_available" ;
VAL_ 1086 RoadProfileRightPoint1 255 "Not_available" ;
VAL_ 1086 RoadProfileLeftPoint1 255 "Not_available" ;
VAL_ 1099 RightLineValidityLka 0 "Not valid" 1 "Enter" ;
VAL_ 1099 DistanceToRightLine 511 "Not_available" ;
VAL_ 1099 RightLineValidityDaa 0 "Invalid" 1 "Valid" ;
VAL_ 1099 RightLineType 0 "Undetermined" 1 "Solid line detected" 2 "Dotted line detected" 3 "Double solid line detected" 5 "Road Edge detected" 6 "Barrier detected" 7 "Invalid" ;
VAL_ 1099 RightLineHeadingAngle 2047 "Not_available" ;
VAL_ 1099 RightLineCurvatureDerivative 32767 "Not_available" ;
VAL_ 1099 RightLineEstimatedCurvature 32767 "Not_available" ;
VAL_ 1101 FrontAverageWheelRpm 65535 "Not_available" ;
VAL_ 1101 WheelSpeedRR 65535 "Not_available" ;
VAL_ 1101 WheelSpeedRL 65535 "Not_available" ;
VAL_ 1101 FrontAverageSpeed 65535 "Not_available" ;
VAL_ 1102 RearHeaterCoreInletWaterSetpoint 255 "Not_available" ;
VAL_ 1102 EvaporatorAdditionalSenso_064c17 31 "Not_available" ;
VAL_ 1102 RearEvaporatorSensorTempe_68d237 2047 "Not_available" ;
VAL_ 1108 HvBatteryTotalPositiveCurrentAh 4095 "Not_available" ;
VAL_ 1108 TimeHvBattOverTemperature 8191 "Not_available" ;
VAL_ 1108 BatterySohResistance 127 "Not_available" ;
VAL_ 1108 BatterySohCapacity 127 "Not_available" ;
VAL_ 1108 DcChargeRelayActuationCounter 1023 "Not_available" ;
VAL_ 1108 MainRelayActuationCounter 1023 "Not_available" ;
VAL_ 1118 RoadProfileRightPoint6 255 "Not_available" ;
VAL_ 1118 RoadProfileLeftPoint6 255 "Not_available" ;
VAL_ 1118 RoadProfileRightPoint5 255 "Not_available" ;
VAL_ 1118 RoadProfileLeftPoint5 255 "Not_available" ;
VAL_ 1118 RoadProfileRightPoint4 255 "Not_available" ;
VAL_ 1118 RoadProfileLeftPoint4 255 "Not_available" ;
VAL_ 1122 FastChargeStopRequest 0 "No request" 1 "Requested" ;
VAL_ 1122 ChargeModeInProgress 0 "Slow (AC)" 1 "Fast (DC)" 2 "No load" ;
VAL_ 1128 ElectricalConsumerClass1Cut 0 "Class 1 powered (active EE components)" 1 "Class 1 not powered (ELECTRICAL_CONSUMER_CLASS_1_CUT, C1 EE devices active)" ;
VAL_ 1128 ElectricalConsumerClass2Cut 0 "Class 2 electrical consumers powered (ELECTRICAL_CONSUMER_CLASS_2_CUT, C2 devices active)" 1 "Class 2 not powered (ELECTRICAL_CONSUMER_CLASS_2_CUT)" ;
VAL_ 1128 ElectricalConsumerClass3Cut 0 "Class 3 powered (C3 electrical components active)" 1 "Class 3 powered off (ELECTRICAL_CONSUMER_CLASS_3_CUT, C3 EE devices active)" ;
VAL_ 1128 ElectricalConsumerClass4Cut 0 "Class 4 powered (ELECTRICAL_CONSUMER_CLASS_4_CUT: C4 electrical components active)" 1 "Class 4 powered (ELECTRICAL_CONSUMER_CLASS_4_CUT, C4 electrical devices active)" ;
VAL_ 1128 ElectricalConsumerClass5Cut 0 "Class 5 powered (ELECTRICAL_CONSUMER_CLASS_5_CUT: C5 electrical components active)" 1 "Class 5 not powered (ELECTRICAL_CONSUMER_CLASS_5_CUT, C5 EE devices active)" ;
VAL_ 1128 ElectricalConsumerClass6Cut 0 "Class 6 powered (class 6 electrical equipment active)" 1 "Class 6 unpowered (ELECTRICAL_CONSUMER_CLASS_6_CUT, C6 electrical devices active)" ;
VAL_ 1128 ElectricalConsumerClass7Cut 0 "Class 7 powered (C7 electrical components active)" 1 "Class 7 not powered (ELECTRICAL_CONSUMER_CLASS_7_CUT, C7 EE devices active)" ;
VAL_ 1128 ElectricalConsumerClass8Cut 0 "Class 8 powered (ELECTRICAL_CONSUMER_CLASS_8_CUT, class 8 electrical components active)" 1 "Class 8 not powered (ELECTRICAL_CONSUMER_CLASS_8_CUT)" ;
VAL_ 1128 ElectricalConsumerClass9Cut 0 "Class 9 powered (active EE components)" 1 "Class 9 not powered (ELECTRICAL_CONSUMER_CLASS_9_CUT: C9 electrical components active)" ;
VAL_ 1128 EngineStopImminent 0 "Engine stop not imminent" 1 "Engine stop imminent" ;
VAL_ 1128 LoadSheddingRequest 0 "No power-shedding request" 1 "Power-shedding level request" ;
VAL_ 1128 VacuumSupplyFaultLampRequest 0 "No ignition request" 1 "Fault lamp lighting request" ;
VAL_ 1128 GeneratorLoadRequest 0 "No load application request" 1 "Maximum load request" 2 "Medium load request" ;
VAL_ 1128 AutomaticGearboxLockupRequest 0 "No request" 1 "Requested" ;
VAL_ 1128 SafetyLoadSheddingLevel1 0 "No load shedding request" 1 "Power saving level request" ;
VAL_ 1128 ElectricalSupplyStatus12v 0 "1.1: storage system / storage system" 1 "1.2: storage system / storage system with electrical machines without holding" 2 "1.3c: storage system / storage system with electrical machine, full hold" 3 "1.3r: storage system / storage system with electrical machines with restricted holding" 4 "2.1: storage system with electric machines, no holding" 5 "3c.1 : storage system with electrical machines with complete holding" 6 "3r.1: storage system with electric machines, restricted holding" 7 "4.1 : active generator with storage system / storage system" 8 "5.5: active generator without storage system / active generator without storage system" 9 "1.3vr storage / storage with MEL, very limited hold" 10 "Storage mode with electric machine, very limited hold / storage" ;
VAL_ 1128 StubbedSignal1 0 "Plug at '0' (used as stubbed value)" ;
VAL_ 1128 CreepAuthorization 0 "Creep prohibition" 1 "Creep authorization" ;
VAL_ 1128 RelayR3ControlRequest 0 "No control request" 1 "Control request" ;
VAL_ 1128 RelayR2ControlRequest 0 "No control request" 1 "Control request" ;
VAL_ 1128 RelayR1ControlRequest 0 "No control request" 1 "Control request" ;
VAL_ 1128 GeneratorProductionFault 0 "No production fault" 1 "Production fault" ;
VAL_ 1128 DcdcLvVoltageSetpoint 63 "Not_available" ;
VAL_ 1128 GeneratorProductionLevel 0 "Low" 1 "Medium" 2 "High" 3 "Full load" 6 "Unavailable" 7 "Invalid" ;
VAL_ 1128 GeneratorProductionStatus 0 "Off" 1 "On" 6 "Unavailable" 7 "Invalid" ;
VAL_ 1128 StarterInhibitDriverUnavailable 0 "No inhibition" 1 "Inhibition" ;
VAL_ 1128 BoostPressure 31 "Not_available" ;
VAL_ 1128 ElectricalConsumerActivat_f46ef1 1 "No request" 2 "Requested" ;
VAL_ 1128 TractionChainStatus 0 "Traction chain open" 1 "Powertrain closed status" 2 "Invalid powertrain status" ;
VAL_ 1128 StartAuthorizationStatus 0 "Waiting" 1 "Authorization" 2 "Forbidding" ;
VAL_ 1128 CmmFault 0 "No fault" 1 "G3 fault" 2 "G4 fault" 3 "Unavailable" ;
VAL_ 1128 TurboTransitionInProgress 0 "No active turbo transition" 1 "Single-turbo to twin-turbo mode transition" 2 "Biturbo to monoturbo mode transition" 3 "Invalid" ;
VAL_ 1128 DampFunctionStatus 0 "No fault" 1 "DAMP fault detected" ;
VAL_ 1128 StarterProtectionStatus 0 "Starter protection disabled" 1 "Starter protection enabled" ;
VAL_ 1128 BrakePedalSecondarySwitch_db3725 0 "Secondary contact OK" 1 "Uncertain brake secondary contact" ;
VAL_ 1128 StarterCommandFeedback 0 "The starter is not rotating" 1 "Starter motor rotating" ;
VAL_ 1134 FuelGaugeResistance 511 "Not_available" ;
VAL_ 1150 RightShockGeometry 15 "Not_available" ;
VAL_ 1150 LeftShockGeometry 15 "Not_available" ;
VAL_ 1150 RightShockDistance 255 "Not_available" ;
VAL_ 1150 LeftShockDistance 255 "Not_available" ;
VAL_ 1150 NextRoadObstacleDistance 255 "Not_available" ;
VAL_ 1150 RoadSurfaceCondition 31 "Not_available" ;
VAL_ 1150 RoadObstacleType 0 "No obstacle" 1 "Speed reducer" 2 "Speed bump, plate type" 3 "Half-round type speed bump" 4 "Obstacle of oscillation type" 5 "Severe pothole" 6 "Obstacle of type Berlin cushion" 7 "Right obstacle, no left obstacle" ;
VAL_ 1150 RoadProfileRightPoint7 255 "Not_available" ;
VAL_ 1150 RoadProfileLeftPoint7 255 "Not_available" ;
VAL_ 1161 DriverTargetGearDisplay 0 "P" 1 "R" 2 "N" 3 "Powered drive (BVMP)" 4 "4" 5 "3" 6 "2" 7 "1" 8 "7" 9 "Up (BVMP)" 10 "Down" 11 "Auto/Manual (BVMP)" 12 "6" 13 "8" 14 "5" 15 "Gear position unknown" ;
VAL_ 1161 GearboxDynamicModeAvailability 0 "Eco and sport modes available" 1 "Eco mode available" 2 "Sport mode available" 3 "No mode available" ;
VAL_ 1161 GearboxLongInitInProgress 0 "No initialization in progress" 1 "Initialization in progress" ;
VAL_ 1161 GearboxRedWarningLampRequest 0 "No request" 1 "Requested" ;
VAL_ 1161 PowertrainSportinessIndexState 0 "Economic type" 10 "Comfort type" 50 "Dynamic type" 90 "Sport type" 100 "Hypershift" ;
VAL_ 1161 TorqueConversionRatioExtended 4095 "Not_available" ;
VAL_ 1161 GearboxDynamicModeStatus 0 "Normal mode" 1 "Dynamic mode" 2 "Eco mode" 3 "Invalid" ;
VAL_ 1161 BrakePressRequest 0 "Brake press not requested" 1 "Brake press requested" ;
VAL_ 1161 SportMode 0 "Sport mode deactivated" 1 "Sport mode activated" ;
VAL_ 1161 GearboxOilTemperature 255 "Not_available" ;
VAL_ 1161 GearboxMilContinuousRequest 0 "No request" 1 "MIL lamp continuous lighting request" ;
VAL_ 1161 GearboxMilBlinkingRequest 0 "No request" 1 "Requested" ;
VAL_ 1161 GearboxMilOnCounterResetCommand 0 "MIL-on distance counter increment" 1 "Km counter reset possible" ;
VAL_ 1161 GearboxMisfireAlgorithmDi_6d0f78 0 "No disturbance" 1 "Disturbance" ;
VAL_ 1161 CrankingProhibit 0 "Crank enabled" 1 "Cranking prohibited" ;
VAL_ 1161 DoublePedalPressDetection 0 "No detection" 1 "Detection" ;
VAL_ 1161 ShiftLockActive 0 "Shift lock inactive (lever not locked)" 1 "Shift lock active (lever locked)" ;
VAL_ 1161 RadiatorFanIncreaseReques_ff8db7 0 "No request" 1 "Cooling increase request" ;
VAL_ 1161 GearboxReadinessCodeSummary 0 "Done" 1 "Not done" ;
VAL_ 1161 GearChangeRefused 0 "Gear shift performed" 1 "Gear shift refused" ;
VAL_ 1161 GearboxDrivingLawSelection 0 "Normal driving law" 1 "Performance/sport driving strategy in automatic gearbox" 2 "Pulse/manual driving law" 3 "Winter driving law on automatic gearbox" ;
VAL_ 1161 GearboxFaultsStates 0 "No global request" 1 "Drain request" 2 "Request to light fault lamp" 4 "Oil temperature alarm" 8 "No start in one of the emergency gears" 9 "Start in one of the emergency gears" 12 "Clutch temperature rise" ;
VAL_ 1161 GearPositionDisplay 0 "P (automatic gearbox)" 1 "R" 2 "N" 3 "D (automatic gearbox)" 4 "4" 5 "3" 6 "2" 7 "1" 8 "P/R or N/R intermediate in automatic gearbox" 9 "N/D intermediate position (automatic gearbox)" 10 "Intermediate position (automatic gearbox)" 11 "8" 12 "6" 13 "7" 14 "5" 15 "CMF disabled or unavailable" ;
VAL_ 1161 GearboxMechanicallyEngagedGear 1 "Gear: 1" 2 "Gear: 2" 3 "Gear: 3" 4 "Transmission range: 4" 5 "Gear: 5" 6 "Gear: 6" 7 "Transmission range: 7" 8 "Gear: 8" 9 "Reverse gear" 10 "Neutral" 15 "Engaged gear uncertain" ;
VAL_ 1173 EpsOilTemperature 255 "Not_available" ;
VAL_ 1173 SteeringTorqueLimitState 0 "No saturation" 1 "Saturation applied" ;
VAL_ 1173 SteeringWheelHeldByDriver 0 "No steering activity detected from the driver" 1 "Steering activity detected from driver torque" ;
VAL_ 1173 EpsStateForLka 0 "Not allowed" 1 "Allowed" 2 "Available" 3 "Activated" 4 "Failure detected" ;
VAL_ 1173 EngineStopAuthorizationByEps 0 "Stop not allowed" 1 "Stop authorization" ;
VAL_ 1173 EngineRestartInhibitByEps 0 "No inhibition of restart" 1 "Restart inhibition" ;
VAL_ 1173 EngineRestartRequestByEps 0 "No need for restart" 1 "Restart needed" ;
VAL_ 1173 EpsDynamicMode 0 "Normal mode" 1 "Dynamic mode" 2 "Tunable mode" 3 "Invalid" ;
VAL_ 1173 EpsWarningLampState2 0 "No request to light the warning lamp" 1 "Request to light the red warning lamp" 2 "Request to light orange lamp" ;
VAL_ 1173 SteeringWheelTorque 127 "Not_available" ;
VAL_ 1230 FrontLeftWheelStatus 1 "Punctured wheel" 2 "Slightly deflated wheel" 4 "Severely deflated wheel" 8 "Wheel pressure not monitored" 16 "Normal pressure" ;
VAL_ 1230 FrontRightWheelStatus 1 "Punctured wheel" 2 "Slightly deflated wheel" 4 "Severely deflated wheel" 8 "Wheel pressure not monitored" 16 "Normal pressure" ;
VAL_ 1230 RearLeftWheelStatus 1 "Punctured wheel" 2 "Slightly deflated wheel" 4 "Severely deflated wheel" 8 "Wheel pressure not monitored" 16 "Normal pressure" ;
VAL_ 1230 RearRightWheelStatus 1 "Punctured wheel" 2 "Slightly deflated wheel" 4 "Severely deflated wheel" 8 "Wheel pressure not monitored" 16 "Normal pressure" ;
VAL_ 1230 AbsFault 0 "No fault detected" 1 "Fault present" ;
VAL_ 1230 BrakeLevelAlert 0 "No alert" 1 "Alarm present" ;
VAL_ 1230 RejectPowerOnInEco 0 "Not refused" 1 "Refused" ;
VAL_ 1230 BrakesFault 0 "No fault detected" 1 "Fault present" ;
VAL_ 1230 FonctActLvvRvv 0 "All functions OFF" 1 "Cruise control ON" 2 "Speed limiter ON" 3 "ACC ON" ;
VAL_ 1230 GearPositionToDisplay 0 "P" 1 "'R'" 2 "'N'" 3 "“D”" 4 "Gear 6" 5 "5th gear" 6 "4th gear" 7 "3rd gear" 8 "Gear 2" 9 "1st gear" 10 "Invalid" 11 "No gear to display" 12 "7th gear" 13 "Invalid" 14 "Invalid" 15 "Invalid" ;
VAL_ 1230 FrontBlowerPlusSwitchState 2 "Speed 1" 3 "Speed 2" 4 "Speed 3" 5 "Speed 4" 6 "Speed5" 7 "Speed 6" 8 "Speed 7" 9 "Speed 8" ;
VAL_ 1230 RearBlowerPlusSwitchState 2 "Speed 1" 3 "Speed 2" 4 "Speed 3" 5 "Speed 4" 6 "Speed5" 7 "Speed 6" 8 "Speed 7" 9 "Speed 8" ;
VAL_ 1230 UnderinflationAlert 0 "No alert" 1 "Alarm present" ;
VAL_ 1230 CenterTemperatureSetpoint 0 "18°C or 64°F" 1 "19°C or 66°F" 2 "20 °C or 68 °F" 3 "21°C or 70°F" 4 "22°C or 72°F" 5 "23 °C or 74 °F" 6 "24 °C or 76 °F" 7 "25 °C or 78 °F" ;
VAL_ 1230 MaintenanceType2 0 "Distance-based (km)" 1 "Distance + time" ;
VAL_ 1230 MaintenanceType 0 "Distance-based (km)" 1 "Time-based" ;
VAL_ 1230 TimeSymbol 0 "Normal (+)" 1 "Maintenance overdue (-)" ;
VAL_ 1230 ParkingBrakes 0 "Loose" 1 "Tight" ;
VAL_ 1230 ParticleFilterFault 0 "Off" 1 "Steady on" ;
VAL_ 1230 CheckAutonomy 0 "Valid" 1 "Invalid" ;
VAL_ 1230 DistanceBlinking 0 "Fixed display" 1 "Blinking display" ;
VAL_ 1230 MaintenanceWrenchIconDisplay 0 "Off/steady" 1 "Steady/blinking" ;
VAL_ 1230 OilPressureAlert 0 "No alert" 1 "Alarm present" ;
VAL_ 1230 OilLevelAlert 0 "No alert" 1 "Alarm present" ;
VAL_ 1230 LowFuelBlink 0 "Steady lighting request" 1 "Flashing request" ;
VAL_ 1230 DieselWaterFault 0 "No fault detected" 1 "Fault present" ;
VAL_ 1257 EagbWaterPumpFault 0 "No eAGB Water Pump failure" 1 "eAGB water pump fault" ;
VAL_ 1257 GearboxEmergencyMode 0 "No emergency mode" 1 "Emergency mode" ;
VAL_ 1257 SscFaultState 0 "No SSC fault" 1 "SSC opening fault" 2 "SSC closing fault" ;
VAL_ 1257 PemFailsafeState 0 "No electric machine fault" 1 "Electric machine not available" ;
VAL_ 1257 EagbFailsafeState 0 "No EAGB fault" 1 "EAGB unavailable (open)" ;
VAL_ 1257 EagbDriveState 1 "Inactive" 2 "Partially active" 3 "Active" ;
VAL_ 1257 GearboxManualModeSelection 0 "Automatic mode" 1 "Manual mode" 2 "ASM mode" ;
VAL_ 1257 GearboxDynamicModeState 0 "Normal mode" 1 "Sport mode" 2 "Eco mode" 3 "Snow mode" ;
VAL_ 1257 ParkingLockState 0 "00: Park position engaged" 1 "01: Park position released" 2 "10: Reserved" 3 "11: Invalid" ;
VAL_ 1257 TcuClearDtcRequest 0 "Fault reset not requested" 1 "Fault reset requested" ;
VAL_ 1257 SemiAutomaticMode 0 "ASM deactivated" 1 "ASM activated" ;
VAL_ 1257 FreewheelingAuthorizationGearbox 0 "No freewheeling possible" 1 "Freewheeling with open powertrain possible" 2 "Freewheeling only possible with lock-up off" 3 "Freewheeling possible only with the traction chain open or the torque converter unlocked" ;
VAL_ 1257 GearboxFreewheelingStatus 0 "No freewheeling" 1 "Transient" 2 "Freewheeling with powertrain open" 3 "Freewheeling with lock-up off only" ;
VAL_ 1272 IcePowerState 0 "Off" 1 "In traction" 2 "Charging" 3 "Invalid" ;
VAL_ 1272 PrimaryMachinePowerState 0 "Off" 1 "Traction under acceleration" 2 "Traction, deceleration on" 3 "Charging" 4 "Invalid" ;
VAL_ 1272 SteeringLoadShedRequest 0 "Nominal" 1 "Performance adapted" 2 "Undervoltage on restart" 3 "EE fault" 4 "TJC or HAD nominal mode" 5 "TJC or HAD fault mode" ;
VAL_ 1272 AcElectricalPowerLimit 255 "Not_available" ;
VAL_ 1272 SemiAutomaticMode 0 "ASM deactivated" 1 "ASM activated" ;
VAL_ 1272 QuickCoolingRequest 0 "Deactivated" 1 "Activated" ;
VAL_ 1272 EngineStartWithSsc 0 "Without SSC" 1 "With SSC" ;
VAL_ 1272 EngineRunNeedIgnoringGbx 0 "No need" 1 "Need" ;
VAL_ 1272 IceEcuDtcClearRequest 0 "Fault reset not requested" 1 "Fault reset requested" ;
VAL_ 1272 EbdLoadShedRequest 0 "No ESP reconfiguration request" 1 "ESP reconfiguration request" ;
VAL_ 1272 LvBatteryDiagRequest 0 "No request" 1 "Requested" ;
VAL_ 1272 LvBatteryModeRequest 0 "Close request" 1 "Opening requested" ;
VAL_ 1274 LvBatteryStopServiceBlinkRequest 0 "No request" 1 "Requested" ;
VAL_ 1274 LvBatterySwitchState 0 "Switch closed" 1 "Switch open" 2 "Failure detected" ;
VAL_ 1274 LvBatteryDiagResult 0 "Not carried out" 1 "Reliable" 2 "Level 1 unreliable" 3 "Level 2 not reliable" 4 "Test not feasible or not reliable" ;
VAL_ 1278 AutoParkManeuverRequest 0 "No request" 1 "Requested" 2 "Unconfigured" 3 "Fault" ;
VAL_ 1278 DriverLeverTakeoverRequest 0 "None" 1 "Unknown request" 2 "Park request" 3 "R request" 4 "Neutral request" 5 "D request" ;
VAL_ 1278 SteeringControlledByAutoPark 0 "False" 1 "True" ;
VAL_ 1278 GearSelectorFault 0 "No fault" 1 "Severity-3 CAAR fault detected" 2 "Severity-4 CAAR fault detected" ;
VAL_ 1278 LeverMovement 0 "No movement" 1 "Movement" ;
VAL_ 1278 BrakePedalRequestToDriver 0 "No request" 1 "Requested" ;
VAL_ 1278 LeverUnlockButtonRequest 0 "No unlock requested" 1 "Unlock requested" ;
VAL_ 1278 LeverPosition 0 "P" 1 "R" 2 "N" 3 "D" 4 "M" 6 "Unknown position" 7 "Invalid" ;
SG_MUL_VAL_ 1012 BatteryTempSlot01 TemperatureGroup 0-0;
SG_MUL_VAL_ 1012 BatteryTempSlot08 TemperatureGroup 1-1;
SG_MUL_VAL_ 1012 BatteryTempSlot15 TemperatureGroup 2-2;
SG_MUL_VAL_ 1012 BatteryTempSlot22 TemperatureGroup 3-3;
SG_MUL_VAL_ 1012 BatteryTempSlot29 TemperatureGroup 4-4;
SG_MUL_VAL_ 1012 BatteryTempSlot36 TemperatureGroup 5-5;
SG_MUL_VAL_ 1012 BatteryTempSlot43 TemperatureGroup 6-6;
SG_MUL_VAL_ 1012 BatteryTempSlot50 TemperatureGroup 7-7;
SG_MUL_VAL_ 1012 BatteryTempSlot02 TemperatureGroup 0-0;
SG_MUL_VAL_ 1012 BatteryTempSlot09 TemperatureGroup 1-1;
SG_MUL_VAL_ 1012 BatteryTempSlot16 TemperatureGroup 2-2;
SG_MUL_VAL_ 1012 BatteryTempSlot23 TemperatureGroup 3-3;
SG_MUL_VAL_ 1012 BatteryTempSlot30 TemperatureGroup 4-4;
SG_MUL_VAL_ 1012 BatteryTempSlot37 TemperatureGroup 5-5;
SG_MUL_VAL_ 1012 BatteryTempSlot44 TemperatureGroup 6-6;
SG_MUL_VAL_ 1012 BatteryTempSlot51 TemperatureGroup 7-7;
SG_MUL_VAL_ 1012 BatteryTempSlot03 TemperatureGroup 0-0;
SG_MUL_VAL_ 1012 BatteryTempSlot10 TemperatureGroup 1-1;
SG_MUL_VAL_ 1012 BatteryTempSlot17 TemperatureGroup 2-2;
SG_MUL_VAL_ 1012 BatteryTempSlot24 TemperatureGroup 3-3;
SG_MUL_VAL_ 1012 BatteryTempSlot31 TemperatureGroup 4-4;
SG_MUL_VAL_ 1012 BatteryTempSlot38 TemperatureGroup 5-5;
SG_MUL_VAL_ 1012 BatteryTempSlot45 TemperatureGroup 6-6;
SG_MUL_VAL_ 1012 BatteryTempSlot52 TemperatureGroup 7-7;
SG_MUL_VAL_ 1012 BatteryTempSlot04 TemperatureGroup 0-0;
SG_MUL_VAL_ 1012 BatteryTempSlot11 TemperatureGroup 1-1;
SG_MUL_VAL_ 1012 BatteryTempSlot18 TemperatureGroup 2-2;
SG_MUL_VAL_ 1012 BatteryTempSlot25 TemperatureGroup 3-3;
SG_MUL_VAL_ 1012 BatteryTempSlot32 TemperatureGroup 4-4;
SG_MUL_VAL_ 1012 BatteryTempSlot39 TemperatureGroup 5-5;
SG_MUL_VAL_ 1012 BatteryTempSlot46 TemperatureGroup 6-6;
SG_MUL_VAL_ 1012 BatteryTempSlot53 TemperatureGroup 7-7;
SG_MUL_VAL_ 1012 BatteryTempSlot05 TemperatureGroup 0-0;
SG_MUL_VAL_ 1012 BatteryTempSlot12 TemperatureGroup 1-1;
SG_MUL_VAL_ 1012 BatteryTempSlot19 TemperatureGroup 2-2;
SG_MUL_VAL_ 1012 BatteryTempSlot26 TemperatureGroup 3-3;
SG_MUL_VAL_ 1012 BatteryTempSlot33 TemperatureGroup 4-4;
SG_MUL_VAL_ 1012 BatteryTempSlot40 TemperatureGroup 5-5;
SG_MUL_VAL_ 1012 BatteryTempSlot47 TemperatureGroup 6-6;
SG_MUL_VAL_ 1012 BatteryTempSlot54 TemperatureGroup 7-7;
SG_MUL_VAL_ 1012 BatteryTempSlot06 TemperatureGroup 0-0;
SG_MUL_VAL_ 1012 BatteryTempSlot13 TemperatureGroup 1-1;
SG_MUL_VAL_ 1012 BatteryTempSlot20 TemperatureGroup 2-2;
SG_MUL_VAL_ 1012 BatteryTempSlot27 TemperatureGroup 3-3;
SG_MUL_VAL_ 1012 BatteryTempSlot34 TemperatureGroup 4-4;
SG_MUL_VAL_ 1012 BatteryTempSlot41 TemperatureGroup 5-5;
SG_MUL_VAL_ 1012 BatteryTempSlot48 TemperatureGroup 6-6;
SG_MUL_VAL_ 1012 RawByte7_Mux7 TemperatureGroup 7-7;
SG_MUL_VAL_ 1012 BatteryTempSlot07 TemperatureGroup 0-0;
SG_MUL_VAL_ 1012 BatteryTempSlot14 TemperatureGroup 1-1;
SG_MUL_VAL_ 1012 BatteryTempSlot21 TemperatureGroup 2-2;
SG_MUL_VAL_ 1012 BatteryTempSlot28 TemperatureGroup 3-3;
SG_MUL_VAL_ 1012 BatteryTempSlot35 TemperatureGroup 4-4;
SG_MUL_VAL_ 1012 BatteryTempSlot42 TemperatureGroup 5-5;
SG_MUL_VAL_ 1012 BatteryTempSlot49 TemperatureGroup 6-6;
SG_MUL_VAL_ 1012 RawByte8_Mux7 TemperatureGroup 7-7;
